VERSION ""

NS_ :

BS_:

BU_: mADC

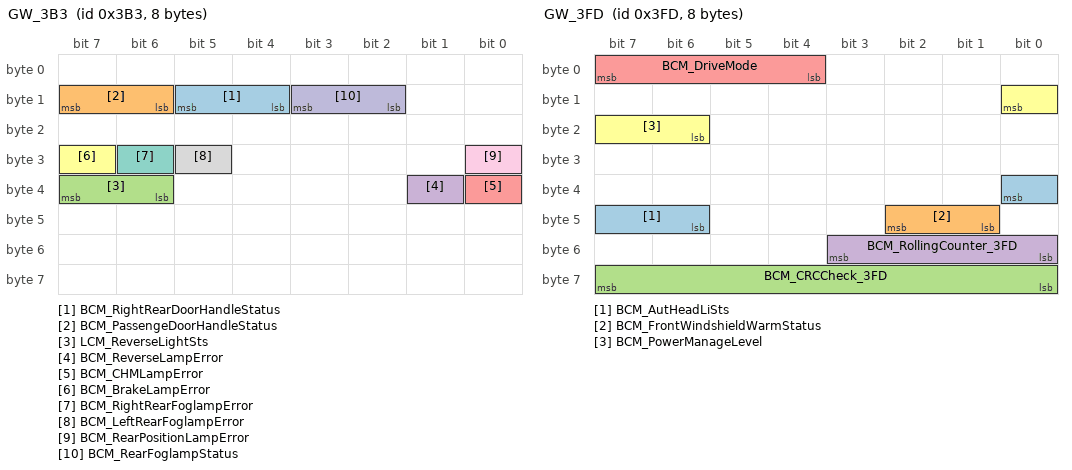
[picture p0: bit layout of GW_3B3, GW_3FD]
BO_ 947 GW_3B3: 8 Vector__XXX
 SG_ BCM_RightRearDoorHandleStatus : 13|2@0+ (1,0) [0|3] ""  mADC
 SG_ BCM_PassengeDoorHandleStatus : 15|2@0+ (1,0) [0|3] ""  mADC
 SG_ LCM_ReverseLightSts : 39|2@0+ (1,0) [0|3] ""  mADC
 SG_ BCM_ReverseLampError : 33|1@0+ (1,0) [0|1] ""  mADC
 SG_ BCM_CHMLampError : 32|1@0+ (1,0) [0|1] ""  mADC
 SG_ BCM_BrakeLampError : 31|1@0+ (1,0) [0|1] ""  mADC
 SG_ BCM_RightRearFoglampError : 30|1@0+ (1,0) [0|1] ""  mADC
 SG_ BCM_LeftRearFoglampError : 29|1@0+ (1,0) [0|1] ""  mADC
 SG_ BCM_RearPositionLampError : 24|1@0+ (1,0) [0|1] ""  mADC
 SG_ BCM_RearFoglampStatus : 11|2@0+ (1,0) [0|3] ""  mADC

BO_ 957 GW_3BD: 64 Vector__XXX
 SG_ HU_Llong_Tunnel_Len : 394|11@0+ (10,0) [0|20470] ""  mADC
 SG_ HU_Long_Ramp_Side : 396|2@0+ (1,0) [0|3] ""  mADC
 SG_ HU_Long_Ramp_Dis : 391|11@0+ (10,0) [0|20470] ""  mADC
 SG_ HU_ParallelRoadSide : 476|2@0+ (1,0) [0|3] ""  mADC
 SG_ HU_ParallelRoadInfo : 478|2@0+ (1,0) [0|3] ""  mADC
 SG_ HU_EnterParallelRoadInfo : 464|2@0+ (1,0) [0|3] ""  mADC
 SG_ HU_ParallelRoadDistance : 456|8@0+ (10,0) [0|2000] "m"  mADC
 SG_ HU_AsistantSysteSwitch : 365|2@0+ (1,0) [0|2] ""  mADC
 SG_ HU_ALCModeSelection : 353|2@0+ (1,0) [0|3] ""  mADC
 SG_ HU_SlotUserSelected : 271|4@0+ (1,0) [0|15] ""  mADC
 SG_ HU_SentryModeSt : 424|3@0+ (1,0) [0|5] ""  mADC
 SG_ HU_AutoHeadLiSet : 242|3@0+ (1,0) [0|7] ""  mADC
 SG_ HU_RADSSwitch : 220|2@0+ (1,0) [0|3] ""  mADC
 SG_ HU_CRCCheck_394 : 63|8@0+ (1,0) [0|255] ""  mADC
 SG_ HU_RollingCounter_394 : 51|4@0+ (1,0) [0|15] ""  mADC
 SG_ HU_LaneChangeReq : 13|2@0+ (1,0) [0|3] ""  mADC
 SG_ HU_UDLCEnable : 17|2@0+ (1,0) [0|3] ""  mADC
 SG_ HU_ESSEnable : 11|2@0+ (1,0) [0|3] ""  mADC
 SG_ HU_ELKEnable : 1|2@0+ (1,0) [0|3] ""  mADC
 SG_ HU_TLAEnable : 9|2@0+ (1,0) [0|3] ""  mADC
 SG_ HU_LAEBEnable : 194|2@0+ (1,0) [0|3] ""  mADC
 SG_ HU_APAModeSelect : 247|3@0+ (1,0) [0|7] ""  mADC
 SG_ HU_NaviDistance : 144|17@0+ (1,0) [0|131070] "m"  mADC

BO_ 964 GW_3C4: 64 Vector__XXX
 SG_ HU_Indication_BusLane_Dis : 415|8@0+ (10,0) [0|2550] ""  mADC
 SG_ HU_Indication_PedestrianCro_Dis : 407|8@0+ (10,0) [0|2550] ""  mADC
 SG_ HU_Indication_MainRoadPri_Dis : 399|8@0+ (10,0) [0|2550] ""  mADC
 SG_ HU_Indication_Walk_Dis : 391|8@0+ (10,0) [0|2550] ""  mADC
 SG_ HU_Indication_OneWay_Dis : 487|8@0+ (10,0) [0|2550] ""  mADC
 SG_ HU_Prohibitory_GiveWayOncom_Dis : 479|8@0+ (10,0) [0|2550] ""  mADC
 SG_ HU_Prohibitory_Honking_Dis : 471|8@0+ (10,0) [0|2550] ""  mADC
 SG_ HU_Prohibitory_Enter_Dis : 463|8@0+ (10,0) [0|2550] ""  mADC
 SG_ HU_Prohibitory_StopToGiveWay_Dis : 455|8@0+ (10,0) [0|2550] ""  mADC
 SG_ HU_Indication_BusLane : 492|1@0+ (1,0) [0|1] ""  mADC
 SG_ HU_Indication_PedestrianCrossing : 493|1@0+ (1,0) [0|1] ""  mADC
 SG_ HU_Indication_MainRoadPriority : 494|1@0+ (1,0) [0|1] ""  mADC
 SG_ HU_Indication_Walk : 495|1@0+ (1,0) [0|1] ""  mADC
 SG_ HU_Indication_OneWay : 327|1@0+ (1,0) [0|1] ""  mADC
 SG_ HU_Prohibitory_GiveWayToOncoming : 436|1@0+ (1,0) [0|1] ""  mADC
 SG_ HU_Prohibitory_Honking : 437|1@0+ (1,0) [0|1] ""  mADC
 SG_ HU_Prohibitory_Enter : 438|1@0+ (1,0) [0|1] ""  mADC
 SG_ HU_Prohibitory_StopToGiveWay : 439|1@0+ (1,0) [0|1] ""  mADC
 SG_ HU_Prohibitory_SpeedLimit : 424|1@0+ (1,0) [0|1] ""  mADC
 SG_ HU_Prohibitory_VehParkLongTime : 425|1@0+ (1,0) [0|1] ""  mADC
 SG_ HU_Prohibitory_VehicleParking : 426|1@0+ (1,0) [0|1] ""  mADC
 SG_ HU_Prohibitory_Overtake : 427|1@0+ (1,0) [0|1] ""  mADC
 SG_ HU_Prohibitory_Uturn : 428|1@0+ (1,0) [0|1] ""  mADC
 SG_ HU_Prohibitory_Straight : 429|1@0+ (1,0) [0|1] ""  mADC
 SG_ HU_Prohibitory_TurnRight : 430|1@0+ (1,0) [0|1] ""  mADC
 SG_ HU_Prohibitory_MotorVehicles : 431|1@0+ (1,0) [0|1] ""  mADC
 SG_ HU_Prohibitory_DriveInto : 416|1@0+ (1,0) [0|1] ""  mADC
 SG_ HU_Warning_RoadWorks : 417|1@0+ (1,0) [0|1] ""  mADC
 SG_ HU_Warning_Slow : 418|1@0+ (1,0) [0|1] ""  mADC
 SG_ HU_Warning_Tunnel : 419|1@0+ (1,0) [0|1] ""  mADC
 SG_ HU_Warning_Slip : 420|1@0+ (1,0) [0|1] ""  mADC
 SG_ HU_Warning_Pedestrian : 421|1@0+ (1,0) [0|1] ""  mADC
 SG_ HU_Warning_ContinuousDetours : 422|1@0+ (1,0) [0|1] ""  mADC
 SG_ HU_Warning_ReverseCurve : 423|1@0+ (1,0) [0|1] ""  mADC
 SG_ HU_BSDLCAMode : 183|3@0+ (1,0) [0|7] ""  mADC
 SG_ HU_CrossingAngle4 : 343|8@0+ (1,0) [0|255] ""  mADC
 SG_ HU_CrossingAngle3 : 351|8@0+ (1,0) [0|255] ""  mADC
 SG_ HU_CrossingAngle2 : 359|8@0+ (1,0) [0|255] ""  mADC
 SG_ HU_CrossingAngle1 : 367|8@0+ (1,0) [0|255] ""  mADC
 SG_ HU_EnterRoundaboutInfo : 373|2@0+ (1,0) [0|3] ""  mADC
 SG_ HU_RoundaboutDistance : 333|6@0+ (10,0) [0|63] ""  mADC
 SG_ HU_EnterCrossingInfo : 375|2@0+ (1,0) [0|3] ""  mADC
 SG_ HU_CrossingDistance : 323|6@0+ (10,0) [0|63] ""  mADC
 SG_ HU_CRCCheck_3C4 : 503|16@0+ (1,0) [0|65535] ""  mADC
 SG_ HU_RollingCounter_3C4 : 491|4@0+ (1,0) [0|15] ""  mADC
 SG_ HU_MapMatchStatus : 309|2@0+ (1,0) [0|3] ""  mADC
 SG_ HU_MapDataUpdateStatus : 118|3@0+ (1,0) [0|7] ""  mADC
 SG_ HU_SlopeGradient_300m : 303|10@0+ (0.1,-51.1) [-51.1|51.1] "%"  mADC
 SG_ HU_RoadCurvature_600m : 281|10@0+ (1,0) [0|1023] "1/m"  mADC
 SG_ HU_RoadCurvature_400m : 275|10@0+ (1,0) [0|1023] "1/m"  mADC
 SG_ HU_RoadCurvature_300m : 269|10@0+ (1,0) [0|1023] "1/m"  mADC
 SG_ HU_RoadCurvature_100m : 263|10@0+ (1,0) [0|1023] "1/m"  mADC
 SG_ HU_RoadCurvature_90m : 239|10@0+ (1,0) [0|1023] "1/m"  mADC
 SG_ HU_RoadCurvature_80m : 217|10@0+ (1,0) [0|1023] "1/m"  mADC
 SG_ HU_RoadCurvature_70m : 211|10@0+ (1,0) [0|1023] "1/m"  mADC
 SG_ HU_RoadCurvature_60m : 205|10@0+ (1,0) [0|1023] "1/m"  mADC
 SG_ HU_RoadCurvature_50m : 199|10@0+ (1,0) [0|1023] "1/m"  mADC
 SG_ HU_RoadCurvature_40m : 161|10@0+ (1,0) [0|1023] "1/m"  mADC
 SG_ HU_RoadCurvature_30m : 155|10@0+ (1,0) [0|1023] "1/m"  mADC
 SG_ HU_RoadCurvature_20m : 149|10@0+ (1,0) [0|1023] "1/m"  mADC
 SG_ HU_RoadCurvature_10m : 143|10@0+ (1,0) [0|1023] "1/m"  mADC
 SG_ HU_Road_TrafficFlow : 105|3@0+ (1,0) [0|7] ""  mADC
 SG_ HU_Lane_Changtype : 129|2@0+ (1,0) [0|3] ""  mADC
 SG_ HU_To_NumchangeOfLanes_Dist : 135|6@0+ (10,0) [0|600] "m"  mADC
 SG_ HU_To_Branch_Dis : 111|6@0+ (10,0) [0|600] "m"  mADC
 SG_ HU_To_TrafficAccident_Dis : 101|6@0+ (10,0) [0|600] "m"  mADC
 SG_ HU_TrafficAccident_Info : 103|2@0+ (1,0) [0|3] ""  mADC
 SG_ HU_To_Construction_Dis : 93|6@0+ (10,0) [0|600] "m"  mADC
 SG_ HU_Construction_Info : 95|2@0+ (1,0) [0|3] ""  mADC
 SG_ HU_TollDis : 85|6@0+ (10,0) [0|600] "m"  mADC
 SG_ HU_TollInfo : 87|2@0+ (1,0) [0|3] ""  mADC
 SG_ HU_FallingRockDi : 77|6@0+ (10,0) [0|600] "m"  mADC
 SG_ HU_FallingRockInfo : 79|2@0+ (1,0) [0|3] ""  mADC
 SG_ HU_LaneCnt : 66|3@0+ (1,0) [0|7] ""  mADC
 SG_ HU_ForwardRoadType : 69|3@0+ (1,0) [0|7] ""  mADC
 SG_ HU_RampSide : 71|2@0+ (1,0) [0|3] ""  mADC
 SG_ HU_NavGuiganceStatus : 47|2@0+ (1,0) [0|3] ""  mADC
 SG_ HU_SlopeDistance : 45|6@0+ (10,0) [0|600] "m"  mADC
 SG_ HU_TunnelLength : 37|6@0+ (10,0) [0|630] "m"  mADC
 SG_ HU_RoadCurvatureFar : 17|10@0+ (1,0) [0|1023] ""  mADC
 SG_ HU_TunnelDistance : 23|6@0+ (10,0) [0|600] "m"  mADC
 SG_ HU_RoadCurvature : 1|10@0+ (1,0) [0|1023] ""  mADC
 SG_ HU_EnterSlopeInfo : 5|2@0+ (1,0) [0|3] ""  mADC
 SG_ HU_EnterTunnelInfo : 3|2@0+ (1,0) [0|3] ""  mADC

BO_ 1021 GW_3FD: 8 Vector__XXX
 SG_ BCM_AutHeadLiSts : 32|3@0+ (1,0) [0|7] ""  mADC
 SG_ BCM_FrontWindshieldWarmStatus : 42|2@0+ (1,0) [0|3] ""  mADC
 SG_ BCM_CRCCheck_3FD : 63|8@0+ (1,0) [0|255] ""  mADC
 SG_ BCM_RollingCounter_3FD : 51|4@0+ (1,0) [0|15] ""  mADC
 SG_ BCM_DriveMode : 7|4@0+ (1,0) [0|15] ""  mADC
 SG_ BCM_PowerManageLevel : 8|3@0+ (1,0) [0|7] ""  mADC

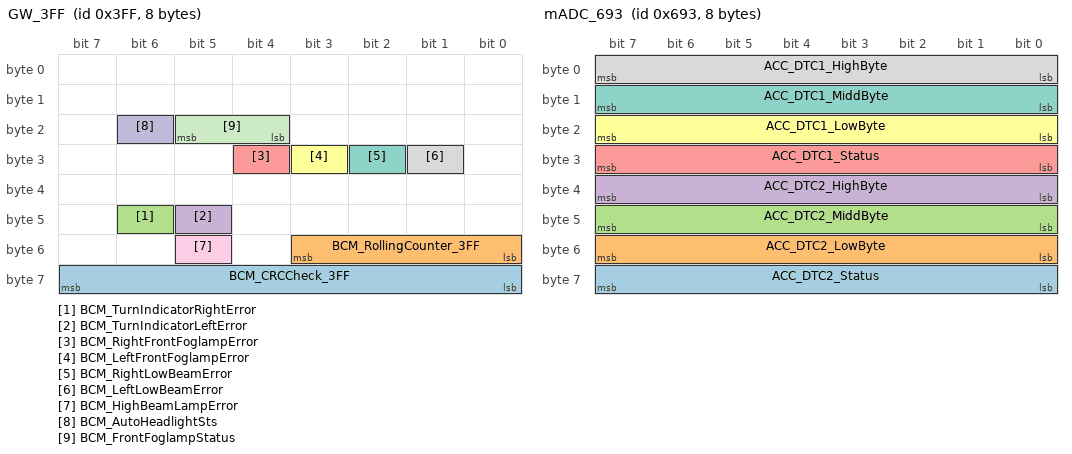
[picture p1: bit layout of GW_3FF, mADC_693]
BO_ 1023 GW_3FF: 8 Vector__XXX
 SG_ BCM_CRCCheck_3FF : 63|8@0+ (1,0) [0|255] ""  mADC
 SG_ BCM_RollingCounter_3FF : 51|4@0+ (1,0) [0|15] ""  mADC
 SG_ BCM_TurnIndicatorRightError : 46|1@0+ (1,0) [0|1] ""  mADC
 SG_ BCM_TurnIndicatorLeftError : 45|1@0+ (1,0) [0|1] ""  mADC
 SG_ BCM_RightFrontFoglampError : 28|1@0+ (1,0) [0|1] ""  mADC
 SG_ BCM_LeftFrontFoglampError : 27|1@0+ (1,0) [0|1] ""  mADC
 SG_ BCM_RightLowBeamError : 26|1@0+ (1,0) [0|1] ""  mADC
 SG_ BCM_LeftLowBeamError : 25|1@0+ (1,0) [0|1] ""  mADC
 SG_ BCM_HighBeamLampError : 53|1@0+ (1,0) [0|1] ""  mADC
 SG_ BCM_AutoHeadlightSts : 22|1@0+ (1,0) [0|1] ""  mADC
 SG_ BCM_FrontFoglampStatus : 21|2@0+ (1,0) [0|3] ""  mADC

BO_ 1683 mADC_693: 8 mADC
 SG_ ACC_DTC2_Status : 63|8@0+ (1,0) [0|255] "" Vector__XXX
 SG_ ACC_DTC2_LowByte : 55|8@0+ (1,0) [0|255] "" Vector__XXX
 SG_ ACC_DTC2_MiddByte : 47|8@0+ (1,0) [0|255] "" Vector__XXX
 SG_ ACC_DTC2_HighByte : 39|8@0+ (1,0) [0|255] "" Vector__XXX
 SG_ ACC_DTC1_Status : 31|8@0+ (1,0) [0|255] "" Vector__XXX
 SG_ ACC_DTC1_LowByte : 23|8@0+ (1,0) [0|255] "" Vector__XXX
 SG_ ACC_DTC1_MiddByte : 15|8@0+ (1,0) [0|255] "" Vector__XXX
 SG_ ACC_DTC1_HighByte : 7|8@0+ (1,0) [0|255] "" Vector__XXX

BO_ 652 GW_28C: 8 Vector__XXX
 SG_ GW_MFS_APA_switch : 35|2@0+ (1,0) [0|3] ""  mADC
 SG_ GW_MFS_HODCalibratedStatus : 29|1@0+ (1,0) [0|1] ""  mADC
 SG_ GW_MFS_HODLinStatus : 28|1@0+ (1,0) [0|1] ""  mADC
 SG_ GW_MFS_HODAppStatus : 27|1@0+ (1,0) [0|1] ""  mADC
 SG_ GW_MFS_HODSenserStatus : 47|1@0+ (1,0) [0|1] ""  mADC
 SG_ GW_MFS_HODSystemStatus : 23|3@0+ (1,0) [0|7] ""  mADC
 SG_ GW_MFS_handsoffAbilityDetect : 26|3@0+ (1,0) [0|7] ""  mADC
 SG_ GW_MFS_handsoffDetectResult : 20|3@0+ (1,0) [0|7] ""  mADC
 SG_ GW_MFS_CRCCheck_28C : 63|8@0+ (1,0) [0|255] ""  mADC
 SG_ GW_MFS_RollingCounter_28C : 51|4@0+ (1,0) [0|15] ""  mADC
 SG_ GW_MFS_DiagInfoSW_28C : 42|3@0+ (1,0) [0|7] ""  mADC
 SG_ GW_MFS_IACCenable_switch_signal : 13|2@0+ (1,0) [0|3] ""  mADC
 SG_ GW_MFS_LIM_switch_signal : 11|2@0+ (1,0) [0|3] ""  mADC
 SG_ GW_MFS_DIST_switch_signal : 9|2@0+ (1,0) [0|3] ""  mADC
 SG_ GW_MFS_SETReduce_switch_signal : 7|2@0+ (1,0) [0|3] ""  mADC
 SG_ GW_MFS_RESPlus_switch_signal : 5|2@0+ (1,0) [0|3] ""  mADC
 SG_ GW_MFS_Cancle_switch_signal : 3|2@0+ (1,0) [0|3] ""  mADC
 SG_ GW_MFS_Crusie_switch_signal : 1|2@0+ (1,0) [0|3] ""  mADC
 SG_ GW_MFS_DISTReduce_switch_signal : 31|2@0+ (1,0) [0|3] ""  mADC
 SG_ GW_MFS_DISTPlus_switch_signal : 17|2@0+ (1,0) [0|3] ""  mADC

BO_ 372 mADC_174: 8 mADC
 SG_ APA_ReqSYNMSG : 1|2@0+ (1,0) [0|3] "" Vector__XXX

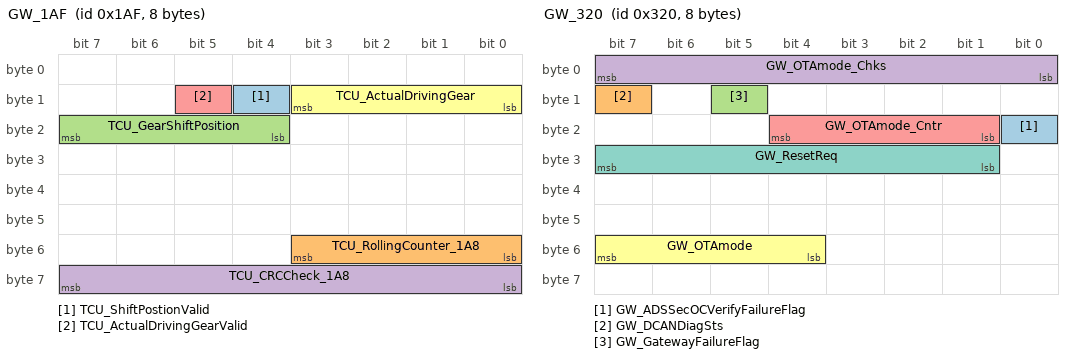
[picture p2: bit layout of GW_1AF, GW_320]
BO_ 431 GW_1AF: 8 Vector__XXX
 SG_ TCU_ShiftPostionValid : 12|1@0+ (1,0) [0|1] ""  mADC
 SG_ TCU_RollingCounter_1A8 : 51|4@0+ (1,0) [0|15] ""  mADC
 SG_ TCU_GearShiftPosition : 23|4@0+ (1,0) [0|15] ""  mADC
 SG_ TCU_CRCCheck_1A8 : 63|8@0+ (1,0) [0|255] ""  mADC
 SG_ TCU_ActualDrivingGearValid : 13|1@0+ (1,0) [0|1] ""  mADC
 SG_ TCU_ActualDrivingGear : 11|4@0+ (1,0) [0|15] ""  mADC

BO_ 800 GW_320: 8 Vector__XXX
 SG_ GW_ADSSecOCVerifyFailureFlag : 16|1@0+ (1,0) [0|1] ""  mADC
 SG_ GW_DCANDiagSts : 15|1@0+ (1,0) [0|1] ""  mADC
 SG_ GW_GatewayFailureFlag : 13|1@0+ (1,0) [0|1] ""  mADC
 SG_ GW_OTAmode_Chks : 7|8@0+ (1,0) [0|255] ""  mADC
 SG_ GW_OTAmode_Cntr : 20|4@0+ (1,0) [0|15] ""  mADC
 SG_ GW_OTAmode : 55|4@0+ (1,0) [0|15] ""  mADC
 SG_ GW_ResetReq : 31|7@0+ (1,0) [0|127] ""  mADC

BO_ 922 mADC_39A: 64 mADC
 SG_ LAS_RoadFeature : 395|4@0+ (1,0) [0|15] "" Vector__XXX
 SG_ LAS_RD4LongDistence : 407|8@0+ (1,0) [0|255] "" Vector__XXX
 SG_ LAS_RD3LongDistence : 415|8@0+ (1,0) [0|255] "" Vector__XXX
 SG_ LAS_RD2LongDistence : 423|8@0+ (1,0) [0|255] "" Vector__XXX
 SG_ LAS_RD1LongDistence : 431|8@0+ (1,0) [0|255] "" Vector__XXX
 SG_ LAS_RD4RoadInforAvailable : 399|2@0+ (1,0) [0|3] "" Vector__XXX
 SG_ LAS_RD3RoadInforAvailable : 439|2@0+ (1,0) [0|3] "" Vector__XXX
 SG_ LAS_RD2RoadInforAvailable : 397|2@0+ (1,0) [0|3] "" Vector__XXX
 SG_ LAS_RD1RoadInforAvailable : 437|2@0+ (1,0) [0|3] "" Vector__XXX
 SG_ LAS_RollingCounter_579 : 435|4@0+ (1,0) [0|15] "" Vector__XXX
 SG_ LAS_CRCCheck_579 : 447|8@0+ (1,0) [0|255] "" Vector__XXX
 SG_ ACC_RollingCounter_39A : 491|4@0+ (1,0) [0|15] "" Vector__XXX
 SG_ ACC_CRCCheck_39A : 503|16@0+ (1,0) [0|65535] "" Vector__XXX
 SG_ LAS_TSRRightLaneStatus : 55|3@0+ (1,0) [0|7] "" Vector__XXX
 SG_ LAS_TSRLeftLaneStatus : 47|3@0+ (1,0) [0|7] "" Vector__XXX
 SG_ LAS_CRCCheck_3C0 : 191|8@0+ (1,0) [0|255] "" Vector__XXX
 SG_ LAS_RollingCounter_3C0 : 179|4@0+ (1,0) [0|15] "" Vector__XXX
 SG_ LAS_TSRRightLaneSpdLimit : 143|8@0+ (1,0) [0|255] "" Vector__XXX
 SG_ LAS_TSRLeftLaneSpdLimit : 135|8@0+ (1,0) [0|255] "" Vector__XXX
 SG_ LAS_CRCCheck_3D4 : 127|8@0+ (1,0) [0|255] "" Vector__XXX
 SG_ LAS_RollingCounter_3D4 : 115|4@0+ (1,0) [0|15] "" Vector__XXX
 SG_ LAS_TLAStopLine_HostLane : 111|8@0+ (1,0) [0|255] "" Vector__XXX
 SG_ LAS_TLADistance_HostLane : 103|8@0+ (1,0) [0|255] "" Vector__XXX
 SG_ LAS_TLACountDownTime_HostLane : 94|7@0+ (1,0) [0|127] "" Vector__XXX
 SG_ LAS_TSRMandatorySign : 70|4@0+ (1,0) [0|15] "" Vector__XXX
 SG_ LAS_TSRWarningSign : 84|5@0+ (1,0) [0|31] "" Vector__XXX
 SG_ LAS_TSRProhibitionSign : 66|5@0+ (1,0) [0|31] "" Vector__XXX
 SG_ LAS_CRCCheck_332 : 63|8@0+ (1,0) [0|255] "" Vector__XXX
 SG_ LAS_RollingCounter_332 : 51|4@0+ (1,0) [0|15] "" Vector__XXX
 SG_ LAS_OverspeedSoundWarningEnSt : 27|1@0+ (1,0) [0|1] "" Vector__XXX
 SG_ LAS_TSREnable : 30|1@0+ (1,0) [0|1] "" Vector__XXX
 SG_ LAS_HMAEnableStatus : 22|1@0+ (1,0) [0|1] "" Vector__XXX
 SG_ LAS_HMALightDistribution : 8|1@0+ (1,0) [0|1] "" Vector__XXX
 SG_ LAS_HMAStatus : 44|2@0+ (1,0) [0|3] "" Vector__XXX
 SG_ LAS_TSRHostSpdLimitUnits : 41|2@0+ (1,0) [0|3] "" Vector__XXX
 SG_ LAS_TSRHostSpdLimit : 39|8@0+ (1,0) [0|255] "" Vector__XXX
 SG_ LAS_TSRStatus : 26|3@0+ (1,0) [0|7] "" Vector__XXX
 SG_ LAS_FrontCameraCalibrationStatus : 20|2@0+ (1,0) [0|3] "" Vector__XXX
 SG_ LAS_FrontCameraFailureStatus : 17|2@0+ (1,0) [0|3] "" Vector__XXX
 SG_ LAS_OverspeedWarningOffset : 14|6@0+ (1,-10) [-10|47] "km/h" Vector__XXX
 SG_ LAS_OverspeedWarningEnableStatus : 15|1@0+ (1,0) [0|1] "" Vector__XXX
 SG_ LAS_OverspeedSoundWarning : 2|1@0+ (1,0) [0|1] "" Vector__XXX
 SG_ LAS_OverspeedVisualWarning : 5|1@0+ (1,0) [0|1] "" Vector__XXX
 SG_ LAS_CRCCheck_37D : 255|8@0+ (1,0) [0|255] "" Vector__XXX
 SG_ LAS_RollingCounter_37D : 243|4@0+ (1,0) [0|15] "" Vector__XXX
 SG_ LAS_TLAArrowDirection_RightLane : 236|3@0+ (1,0) [0|7] "" Vector__XXX
 SG_ LAS_TLAObjectType_RightLane : 239|3@0+ (1,0) [0|7] "" Vector__XXX
 SG_ LAS_TLAObjectStatus_RightLane : 247|2@0+ (1,0) [0|3] "" Vector__XXX
 SG_ LAS_TLAObjectColour_RightLane : 225|2@0+ (1,0) [0|3] "" Vector__XXX
 SG_ LAS_TLAObjectDetection_RightLane : 227|1@0+ (1,0) [0|1] "" Vector__XXX
 SG_ LAS_TLAArrowDirection_LeftLane : 216|3@0+ (1,0) [0|7] "" Vector__XXX
 SG_ LAS_TLAObjectType_LeftLane : 219|3@0+ (1,0) [0|7] "" Vector__XXX
 SG_ LAS_TLAObjectStatus_LeftLane : 245|2@0+ (1,0) [0|3] "" Vector__XXX
 SG_ LAS_TLAObjectColour_LeftLane : 221|2@0+ (1,0) [0|3] "" Vector__XXX
 SG_ LAS_TLAObjectDetection_LeftLane : 223|1@0+ (1,0) [0|1] "" Vector__XXX
 SG_ LAS_TLAArrowDirection_HostLane : 215|3@0+ (1,0) [0|7] "" Vector__XXX
 SG_ LAS_TLAObjectStatus_HostLane : 199|2@0+ (1,0) [0|3] "" Vector__XXX
 SG_ LAS_TLAObjectType_HostLane : 212|3@0+ (1,0) [0|7] "" Vector__XXX
 SG_ LAS_TLAObjectColour_HostLane : 204|2@0+ (1,0) [0|3] "" Vector__XXX
 SG_ LAS_TLAObjectDetection_HostLane : 200|1@0+ (1,0) [0|1] "" Vector__XXX
 SG_ LAS_TLAWarninglevel : 197|2@0+ (1,0) [0|3] "" Vector__XXX
 SG_ LAS_TLAStatus : 193|2@0+ (1,0) [0|3] "" Vector__XXX
 SG_ LAS_TLAEnable : 194|1@0+ (1,0) [0|1] "" Vector__XXX
 SG_ LAS_RoadSignCenterLatRange_RLane : 306|9@0+ (0.05,-8) [-8|17.55] "m" Vector__XXX
 SG_ LAS_RoadSignCenterLngRange_RLane : 299|9@0+ (0.1,0) [0|51.1] "m" Vector__XXX
 SG_ LAS_RoadSignCenterLatRange_LLane : 292|9@0+ (0.05,-8) [-8|17.55] "m" Vector__XXX
 SG_ LAS_RoadSignCenterLngRange_LLane : 285|9@0+ (0.1,0) [0|51.1] "m" Vector__XXX
 SG_ LAS_RoadSignCenterLatRange_HLane : 278|9@0+ (0.05,-8) [-8|17.55] "m" Vector__XXX
 SG_ LAS_RoadSignCenterLngRange_HLane : 271|9@0+ (0.1,0) [0|51.1] "m" Vector__XXX
 SG_ LAS_CrosswalkLngRange_HLane : 263|8@0+ (1,0) [0|255] "" Vector__XXX
 SG_ LAS_RoadSignType_RLane : 157|5@0+ (1,0) [0|15] "" Vector__XXX
 SG_ LAS_RoadSignType_LLane : 146|5@0+ (1,0) [0|15] "" Vector__XXX
 SG_ LAS_RoadSignType_HLane : 151|5@0+ (1,0) [0|15] "" Vector__XXX

BO_ 906 GW_38A: 8 Vector__XXX
 SG_ GW_MFS_Cust_switch : 17|2@0+ (1,0) [0|3] ""  mADC

BO_ 583 BDC_247: 32 Vector__XXX
 SG_ APA_EngTorqReq : 87|10@0+ (0.097847,0) [0|99.999634] "%"  mADC
 SG_ APA_SlotNotice_1 : 169|6@0+ (1,0) [0|63] ""  mADC
 SG_ APA_VCUReadyReq : 43|1@0+ (1,0) [0|1] ""  mADC
 SG_ APA_ESPDistToStop : 149|12@0+ (1,0) [0|4095] "cm"  mADC
 SG_ APA_ESP_StandstillRequest : 150|1@0+ (1,0) [0|1] ""  mADC
 SG_ APA_RollingCounter_236 : 179|4@0+ (1,0) [0|15] ""  mADC
 SG_ APA_CRC_Checksum_236 : 191|8@0+ (1,0) [0|255] ""  mADC
 SG_ APA_PtTrqReqValid : 151|1@0+ (1,0) [0|1] ""  mADC
 SG_ APA_LatLongSC : 31|2@0+ (1,0) [0|3] ""  mADC
 SG_ APA_ESP_BrakeFunctionMode : 238|3@0+ (1,0) [0|7] ""  mADC
 SG_ APA_TrqHoldForTCUCl : 111|1@0+ (1,0) [0|1] ""  mADC
 SG_ APA_TCUClutchCombinationReq : 110|1@0+ (1,0) [0|1] ""  mADC
 SG_ APA_FunctionOnOffSts : 33|5@0+ (1,0) [0|31] ""  mADC
 SG_ APA_APAOnOff : 6|1@0+ (1,0) [0|1] ""  mADC
 SG_ APA_CRCCheck_264 : 63|8@0+ (1,0) [0|255] ""  mADC
 SG_ APA_ParkingPercentage : 42|7@0+ (1,0) [0|100] "%"  mADC
 SG_ APA_RollingCounter_264 : 51|4@0+ (1,0) [0|15] ""  mADC
 SG_ APA_TurnLightsCommand : 29|2@0+ (1,0) [0|3] ""  mADC
 SG_ APA_IncreasePressureReq : 27|1@0+ (1,0) [0|1] ""  mADC
 SG_ APA_RemoteOnOff : 25|2@0+ (1,0) [0|3] ""  mADC
 SG_ APA_SteeringAngleReq : 15|16@0- (0.1,0) [-780|780] "degree"  mADC
 SG_ APA_EmergenceBrake : 7|1@0+ (1,0) [0|1] ""  mADC
 SG_ APA_ErrorStatus : 2|1@0+ (1,0) [0|1] ""  mADC
 SG_ APA_SteeringAngleReqProtection : 1|2@0+ (1,0) [0|3] ""  mADC
 SG_ APA_HSAHDforbidden : 92|1@0+ (1,0) [0|1] ""  mADC
 SG_ APA_CRCCheck_26C : 127|8@0+ (1,0) [0|255] ""  mADC
 SG_ APA_RollingCounter_26C : 115|4@0+ (1,0) [0|15] "N/A"  mADC
 SG_ APA_AccPedShieldReq : 97|1@0+ (1,0) [0|1] ""  mADC
 SG_ APA_SlotNotice : 109|4@0+ (1,0) [0|15] ""  mADC
 SG_ APA_DynamicSlotWarning : 105|1@0+ (1,0) [0|1] ""  mADC
 SG_ APA_Activation_Status : 89|3@0+ (1,0) [0|7] ""  mADC
 SG_ APA_EngineTrqReqEnable : 93|1@0+ (1,0) [0|1] ""  mADC
 SG_ APA_LSCAction : 91|1@0+ (1,0) [0|1] ""  mADC
 SG_ APA_TransPRNDShiftEnable : 90|1@0+ (1,0) [0|1] ""  mADC
 SG_ APA_TargetAcceleration : 79|8@0+ (0.05,-5) [-5|7.75] "m/s2"  mADC
 SG_ APA_TransPRNDShiftReqValid : 71|1@0+ (1,0) [0|1] ""  mADC
 SG_ APA_TransPRNDShiftRequest : 70|3@0+ (1,0) [0|7] ""  mADC
 SG_ APA_TargetAccelerationValid : 67|1@0+ (1,0) [0|1] "NA"  mADC
 SG_ APA_EPBrequestValid : 66|1@0+ (1,0) [0|1] ""  mADC
 SG_ APA_EPBrequest : 65|2@0+ (1,0) [0|3] ""  mADC
 SG_ APA_PtTorqReq : 135|16@0+ (1,-32768) [-32768|32767] "Nm"  mADC
 SG_ APA_CRCCheck_247 : 247|16@0+ (1,0) [0|65535] ""  mADC
 SG_ APA_RollingCounter_247 : 235|4@0+ (1,0) [0|15] ""  mADC

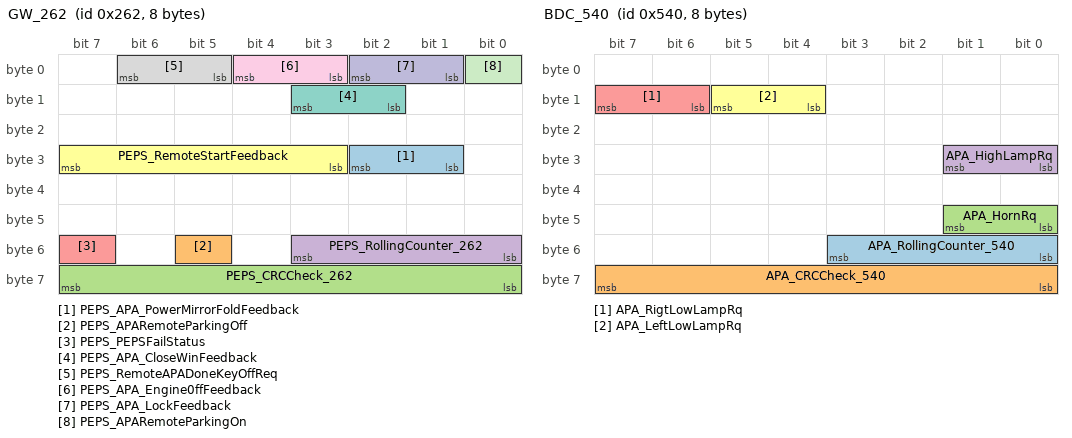
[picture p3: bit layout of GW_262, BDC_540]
BO_ 610 GW_262: 8 Vector__XXX
 SG_ PEPS_APA_PowerMirrorFoldFeedback : 26|2@0+ (1,0) [0|3] ""  mADC
 SG_ PEPS_APARemoteParkingOff : 53|1@0+ (1,0) [0|1] ""  mADC
 SG_ PEPS_CRCCheck_262 : 63|8@0+ (1,0) [0|255] ""  mADC
 SG_ PEPS_RollingCounter_262 : 51|4@0+ (1,0) [0|15] ""  mADC
 SG_ PEPS_PEPSFailStatus : 55|1@0+ (1,0) [0|1] ""  mADC
 SG_ PEPS_RemoteStartFeedback : 31|5@0+ (1,0) [0|31] ""  mADC
 SG_ PEPS_APA_CloseWinFeedback : 11|2@0+ (1,0) [0|3] ""  mADC
 SG_ PEPS_RemoteAPADoneKeyOffReq : 6|2@0+ (1,0) [0|3] ""  mADC
 SG_ PEPS_APA_Engine0ffFeedback : 4|2@0+ (1,0) [0|3] ""  mADC
 SG_ PEPS_APA_LockFeedback : 2|2@0+ (1,0) [0|3] ""  mADC
 SG_ PEPS_APARemoteParkingOn : 0|1@0+ (1,0) [0|1] ""  mADC

BO_ 917 GW_395: 64 Vector__XXX
 SG_ TBOX_APP_Ylevel : 215|16@0+ (1,0) [0|720] ""  mADC
 SG_ TBOX_APP_Xlevel : 199|16@0+ (1,0) [0|1920] ""  mADC
 SG_ TBOX_APAControlEnable : 226|5@0+ (1,0) [0|31] ""  mADC
 SG_ TBOX_RemoteStartReq : 228|2@0+ (1,0) [0|3] ""  mADC
 SG_ TBOX_APAFunctionReq : 231|3@0+ (1,0) [0|7] ""  mADC
 SG_ TBOX_SignalStrength : 89|3@0+ (1,0) [0|7] ""  mADC
 SG_ TBOX_SignalType : 92|3@0+ (1,0) [0|7] ""  mADC
 SG_ TBOX_APA_SignalDelay : 87|4@0+ (1,0) [0|15] ""  mADC
 SG_ TBOX_APAmoduleEnable : 71|2@0+ (1,0) [0|3] ""  mADC
 SG_ TBOX_RemoteDisReq : 50|1@0+ (1,0) [0|1] ""  mADC
 SG_ TBOX_VehicleVedioDetectReq : 1|2@0+ (1,0) [0|3] ""  mADC
 SG_ TBOX_RemoteDetectReq : 55|2@0+ (1,0) [0|3] ""  mADC

BO_ 1344 BDC_540: 8 Vector__XXX
 SG_ APA_RollingCounter_540 : 51|4@0+ (1,0) [0|15] ""  mADC
 SG_ APA_CRCCheck_540 : 63|8@0+ (1,0) [0|255] ""  mADC
 SG_ APA_HornRq : 41|2@0+ (1,0) [0|3] ""  mADC
 SG_ APA_HighLampRq : 25|2@0+ (1,0) [0|3] ""  mADC
 SG_ APA_RigtLowLampRq : 15|2@0+ (1,0) [0|3] ""  mADC
 SG_ APA_LeftLowLampRq : 13|2@0+ (1,0) [0|3] ""  mADC

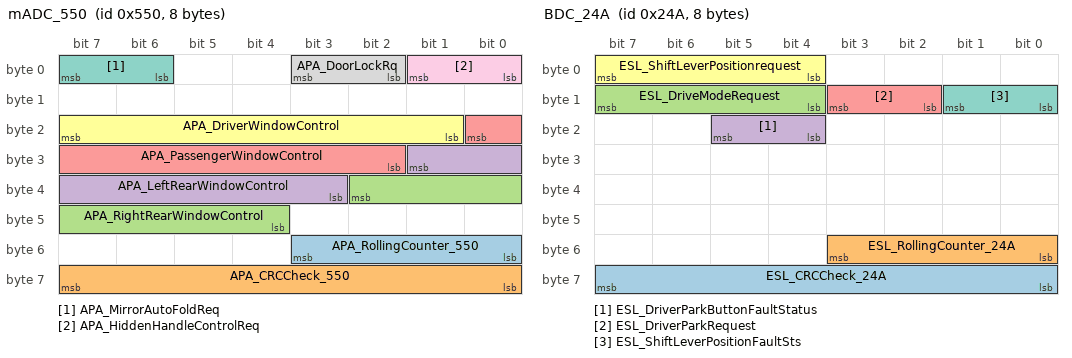
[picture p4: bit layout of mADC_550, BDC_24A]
BO_ 1360 mADC_550: 8 mADC
 SG_ APA_RollingCounter_550 : 51|4@0+ (1,0) [0|15] "" Vector__XXX
 SG_ APA_CRCCheck_550 : 63|8@0+ (1,0) [0|255] "" Vector__XXX
 SG_ APA_RightRearWindowControl : 34|7@0+ (1,0) [0|127] "" Vector__XXX
 SG_ APA_LeftRearWindowControl : 25|7@0+ (1,0) [0|127] "" Vector__XXX
 SG_ APA_PassengerWindowControl : 16|7@0+ (1,0) [0|127] "" Vector__XXX
 SG_ APA_DriverWindowControl : 23|7@0+ (1,0) [0|127] "" Vector__XXX
 SG_ APA_MirrorAutoFoldReq : 7|2@0+ (1,0) [0|3] "" Vector__XXX
 SG_ APA_DoorLockRq : 3|2@0+ (1,0) [0|3] "" Vector__XXX
 SG_ APA_HiddenHandleControlReq : 1|2@0+ (1,0) [0|3] "" Vector__XXX

BO_ 1364 mADC_554: 8 mADC
 SG_ APA_RollingCounter_554 : 51|4@0+ (1,0) [0|15] "" Vector__XXX
 SG_ APA_CRCCheck_554 : 63|8@0+ (1,0) [0|255] "" Vector__XXX

BO_ 1554 mADC_612: 8 mADC
 SG_ DVR_EmergencyRecordStatus : 29|2@0+ (1,0) [0|3] "" Vector__XXX

BO_ 394 GW_18A: 8 Vector__XXX
 SG_ TCU_APAShiftGearRequestEnable : 2|2@0+ (1,0) [0|3] ""  mADC
 SG_ TCU_APAdriverInterruption : 4|2@0+ (1,0) [0|3] ""  mADC

BO_ 586 BDC_24A: 8 Vector__XXX
 SG_ ESL_CRCCheck_24A : 63|8@0+ (1,0) [0|255] ""  mADC
 SG_ ESL_RollingCounter_24A : 51|4@0+ (1,0) [0|15] ""  mADC
 SG_ ESL_DriveModeRequest : 15|4@0+ (1,0) [0|15] ""  mADC
 SG_ ESL_DriverParkButtonFaultStatus : 21|2@0+ (1,0) [0|3] ""  mADC
 SG_ ESL_DriverParkRequest : 11|2@0+ (1,0) [0|3] ""  mADC
 SG_ ESL_ShiftLeverPositionrequest : 7|4@0+ (1,0) [0|15] ""  mADC
 SG_ ESL_ShiftLeverPositionFaultSts : 9|2@0+ (1,0) [0|3] ""  mADC

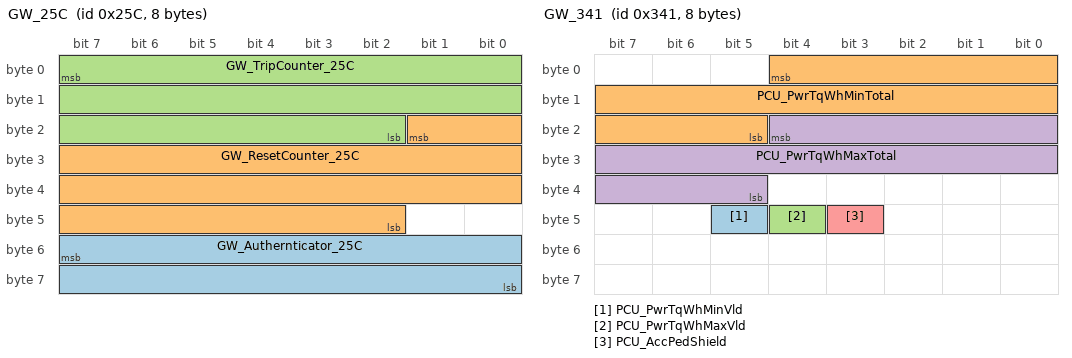
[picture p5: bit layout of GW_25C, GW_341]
BO_ 604 GW_25C: 8 Vector__XXX
 SG_ GW_Authernticator_25C : 55|16@0+ (1,0) [0|65535] ""  mADC
 SG_ GW_ResetCounter_25C : 17|24@0+ (1,0) [0|16777215] ""  mADC
 SG_ GW_TripCounter_25C : 7|22@0+ (1,0) [0|4194303] ""  mADC

BO_ 710 BDC_2C6: 64 Vector__XXX
 SG_ APA_FunctionOnOffSts : 75|4@0+ (1,0) [0|15] ""  mADC
 SG_ APA_ParkingSlot_Width : 429|6@0+ (0.1,1.7) [0|8] "m"  mADC
 SG_ APA_ParkingSlot_Length : 420|7@0+ (0.1,2.9) [0|15.6] "m"  mADC
 SG_ APA_ParkingSlot_ExtraFeature : 408|4@0+ (1,0) [0|15] ""  mADC
 SG_ APA_ParkingSlot_Type : 412|4@0+ (1,0) [0|15] ""  mADC
 SG_ APA_ActivationSts : 401|3@0+ (1,0) [0|7] ""  mADC
 SG_ APA_CRCCheck_2C6 : 503|16@0+ (1,0) [0|65535] ""  mADC
 SG_ APA_RollingCounter_2C6 : 491|4@0+ (1,0) [0|15] ""  mADC
 SG_ APA_Condition_Notice : 391|5@0+ (1,0) [0|31] ""  mADC
 SG_ APA_TouchInfOnOffRes : 111|3@0+ (1,0) [0|7] ""  mADC
 SG_ APA_RADSNotice : 108|6@0+ (1,0) [0|63] ""  mADC
 SG_ APA_PowerMirrorFoldReq : 89|2@0+ (1,0) [0|3] ""  mADC
 SG_ APA_LAEBReq : 71|1@0+ (1,0) [0|1] ""  mADC
 SG_ APA_left_fishboneslot_type : 55|2@0+ (1,0) [0|3] ""  mADC
 SG_ APA_right_fishboneslot_type : 53|2@0+ (1,0) [0|3] ""  mADC
 SG_ APA_right_slot_4_available_sts : 185|2@0+ (1,0) [0|3] ""  mADC
 SG_ APA_right_slot_3_available_sts : 187|2@0+ (1,0) [0|3] ""  mADC
 SG_ APA_right_slot_2_available_sts : 189|2@0+ (1,0) [0|3] ""  mADC
 SG_ APA_right_slot_1_available_sts : 191|2@0+ (1,0) [0|3] ""  mADC
 SG_ APA_left_slot_4_available_sts : 177|2@0+ (1,0) [0|3] ""  mADC
 SG_ APA_left_slot_3_available_sts : 179|2@0+ (1,0) [0|3] ""  mADC
 SG_ APA_left_slot_2_available_sts : 181|2@0+ (1,0) [0|3] ""  mADC
 SG_ APA_left_slot_1_available_sts : 183|2@0+ (1,0) [0|3] ""  mADC
 SG_ APA_right_slot_4_distance_px : 161|10@0+ (1,0) [0|1023] ""  mADC
 SG_ APA_right_slot_4_type : 163|2@0+ (1,0) [0|3] ""  mADC
 SG_ APA_right_slot_3_distance_px : 157|10@0+ (1,0) [0|1023] ""  mADC
 SG_ APA_right_slot_3_type : 159|2@0+ (1,0) [0|3] ""  mADC
 SG_ APA_left_slot_4_distance_px : 137|10@0+ (1,0) [0|1023] ""  mADC
 SG_ APA_left_slot_4_type : 139|2@0+ (1,0) [0|3] ""  mADC
 SG_ APA_left_slot_3_distance_px : 133|10@0+ (1,0) [0|1023] ""  mADC
 SG_ APA_left_slot_3_type : 135|2@0+ (1,0) [0|3] ""  mADC
 SG_ APA_NumberofParkingSlot : 95|4@0+ (1,0) [0|15] ""  mADC
 SG_ APA_BCMHornCommand : 97|2@0+ (1,0) [0|3] ""  mADC
 SG_ APA_PEPS_EngineOffLockRequest : 101|1@0+ (1,0) [0|1] ""  mADC
 SG_ APA_RemoteParkingUsingRemind : 83|1@0+ (1,0) [0|1] ""  mADC
 SG_ APA_BLEConnectionRemind : 79|1@0+ (1,0) [0|1] ""  mADC
 SG_ APA_ReleasePressureReq : 100|1@0+ (1,0) [0|1] ""  mADC
 SG_ APA_LAEBNotice : 82|3@0+ (1,0) [0|7] ""  mADC
 SG_ APA_LAEBStatus : 78|3@0+ (1,0) [0|7] ""  mADC
 SG_ APA_ParkNotice_5 : 70|7@0+ (1,0) [0|127] ""  mADC
 SG_ APA_right_slot_2_distance_px : 33|10@0+ (1,0) [0|1023] "px"  mADC
 SG_ APA_right_slot_1_distance_px : 29|10@0+ (1,0) [0|1023] "px"  mADC
 SG_ APA_right_slot_2_type : 35|2@0+ (1,0) [0|3] ""  mADC
 SG_ APA_right_slot_1_type : 31|2@0+ (1,0) [0|3] ""  mADC
 SG_ APA_left_slot_2_distance_px : 9|10@0+ (1,0) [0|1023] "px"  mADC
 SG_ APA_left_slot_1_distance_px : 5|10@0+ (1,0) [0|1023] "px"  mADC
 SG_ APA_left_slot_2_type : 11|2@0+ (1,0) [0|3] ""  mADC
 SG_ APA_left_slot_1_type : 7|2@0+ (1,0) [0|3] ""  mADC

BO_ 798 BDC_31E: 64 Vector__XXX
 SG_ APA_RollingCounter_31E : 491|4@0+ (1,0) [0|15] ""  mADC
 SG_ APA_CRCCheck_31E : 503|16@0+ (1,0) [0|65535] ""  mADC
 SG_ APA_VoiceTipType : 494|3@0+ (1,0) [0|7] ""  mADC
 SG_ APA_ActiveSts : 295|1@0+ (1,0) [0|1] ""  mADC
 SG_ APA_ParkVoiceIntSet : 301|2@0+ (1,0) [0|3] ""  mADC
 SG_ APA_AVMNotice : 310|3@0+ (1,0) [0|7] ""  mADC
 SG_ RRS_LoudspeakersPosition : 67|4@0+ (1,0) [0|15] ""  mADC
 SG_ APA_SystemFailureFlag : 284|5@0+ (1,0) [0|31] ""  mADC
 SG_ APA_ObstacleSafeDistSetStatus : 287|3@0+ (-1,0) [-7|0] "cm"  mADC
 SG_ APA_Uls_FKP_WarningSoundStatus : 277|2@0+ (1,0) [0|3] ""  mADC
 SG_ APA_CrossParkingModeSetSts : 299|2@0+ (1,0) [0|3] ""  mADC
 SG_ APA_CRCCheck_3BA : 319|8@0+ (1,0) [0|255] ""  mADC
 SG_ APA_RollingCounter_3BA : 307|4@0+ (1,0) [0|15] ""  mADC
 SG_ ACC_LAEBEnableSts : 289|2@0+ (1,0) [0|3] ""  mADC
 SG_ APA_CRCCheck_2A7 : 255|8@0+ (1,0) [0|255] ""  mADC
 SG_ APA_RollingCounter_2A7 : 243|4@0+ (1,0) [0|15] ""  mADC
 SG_ RFS_Sector_Dist : 228|7@0+ (1,0) [0|127] "cm"  mADC
 SG_ LFS_Sector_Dist : 219|7@0+ (1,0) [0|127] "cm"  mADC
 SG_ RFC_Sector_Dist : 210|7@0+ (1,0) [0|127] "cm"  mADC
 SG_ LFC_Sector_Dist : 201|7@0+ (1,0) [0|127] "cm"  mADC
 SG_ RFM_Sector_Dist : 192|7@0+ (1,0) [0|127] "cm"  mADC
 SG_ LFM_Sector_Dist : 199|7@0+ (1,0) [0|127] "cm"  mADC
 SG_ APA_CRCCheck_2A6 : 191|8@0+ (1,0) [0|255] ""  mADC
 SG_ APA_RollingCounter_2A6 : 179|4@0+ (1,0) [0|15] ""  mADC
 SG_ RRS_Sector_Dist : 162|7@0+ (1,0) [0|127] "cm"  mADC
 SG_ LRS_Sector_Dist : 153|7@0+ (1,0) [0|127] "cm"  mADC
 SG_ RRC_Sector_Dist : 144|7@0+ (1,0) [0|127] "cm"  mADC
 SG_ LRC_Sector_Dist : 151|7@0+ (1,0) [0|127] "cm"  mADC
 SG_ RRM_Sector_Dist : 143|8@0+ (1,0) [0|255] "cm"  mADC
 SG_ LRM_Sector_Dist : 135|8@0+ (1,0) [0|255] "cm"  mADC
 SG_ RRF_Sector_Dist : 107|7@0+ (1,0) [0|127] "cm"  mADC
 SG_ LRF_Sector_Dist : 98|7@0+ (1,0) [0|127] "cm"  mADC
 SG_ RFF_Sector_Dist : 89|7@0+ (1,0) [0|127] "cm"  mADC
 SG_ LFF_Sector_Dist : 80|7@0+ (1,0) [0|127] "cm"  mADC
 SG_ RRS_FrontRadarActiveStatus : 62|2@0+ (1,0) [0|3] ""  mADC
 SG_ RRS_SwitchIndicatorError : 60|1@0+ (1,0) [0|1] ""  mADC
 SG_ RRS_ButtonPress : 49|1@0+ (1,0) [0|1] ""  mADC
 SG_ RRS_WarningType : 47|4@0+ (1,0) [0|15] ""  mADC
 SG_ RRS_WarningFrequency : 41|2@0+ (1,0) [0|3] ""  mADC
 SG_ RRS_LFSDistance : 58|3@0+ (1,0) [0|7] ""  mADC
 SG_ RRS_LRSDistance : 55|3@0+ (1,0) [0|7] ""  mADC
 SG_ RRS_RFSDistance : 52|3@0+ (1,0) [0|7] ""  mADC
 SG_ RRS_SideZoneStatus_Rear : 43|2@0+ (1,0) [0|3] ""  mADC
 SG_ RRS_SideZoneStatus_Front : 39|2@0+ (1,0) [0|3] ""  mADC
 SG_ RRS_RRSDistance : 37|3@0+ (1,0) [0|7] ""  mADC
 SG_ RRS_MODE : 34|3@0+ (1,0) [0|7] ""  mADC
 SG_ RRS_LFMDistance : 31|4@0+ (1,0) [0|15] ""  mADC
 SG_ RRS_RFMDistance : 27|4@0+ (1,0) [0|15] ""  mADC
 SG_ RRS_RFCDistance : 23|4@0+ (1,0) [0|15] ""  mADC
 SG_ RRS_LFCDistance : 19|4@0+ (1,0) [0|15] ""  mADC
 SG_ RRS_RRCDistance : 15|4@0+ (1,0) [0|15] ""  mADC
 SG_ RRS_LRCDistance : 11|4@0+ (1,0) [0|15] ""  mADC
 SG_ RRS_RRMDistance : 7|4@0+ (1,0) [0|15] ""  mADC
 SG_ RRS_LRMDistance : 3|4@0+ (1,0) [0|15] ""  mADC

BO_ 833 GW_341: 8 Vector__XXX
 SG_ PCU_PwrTqWhMinVld : 45|1@0+ (1,0) [0|1] ""  mADC
 SG_ PCU_PwrTqWhMinTotal : 4|16@0+ (1,-32768) [-32768|32767] "Nm"  mADC
 SG_ PCU_PwrTqWhMaxVld : 44|1@0+ (1,0) [0|1] ""  mADC
 SG_ PCU_PwrTqWhMaxTotal : 20|16@0+ (1,-32768) [-32768|32767] "Nm"  mADC
 SG_ PCU_AccPedShield : 43|1@0+ (1,0) [0|1] ""  mADC

BO_ 866 GW_362: 8 Vector__XXX
 SG_ PCU_eDTE : 45|9@0+ (1,0) [0|510] "km"  mADC

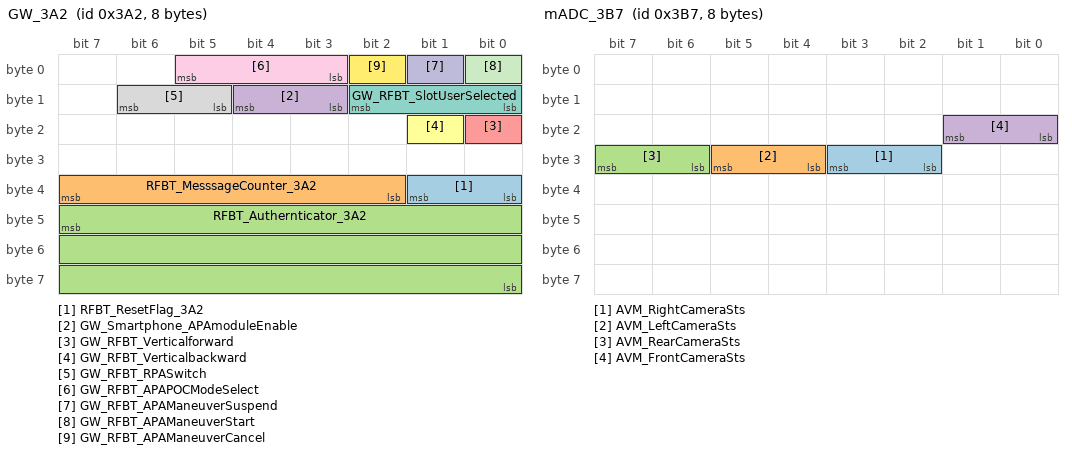
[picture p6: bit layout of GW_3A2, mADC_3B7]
BO_ 930 GW_3A2: 8 Vector__XXX
 SG_ RFBT_ResetFlag_3A2 : 33|2@0+ (1,0) [0|3] ""  mADC
 SG_ RFBT_MesssageCounter_3A2 : 39|6@0+ (1,0) [0|63] ""  mADC
 SG_ RFBT_Authernticator_3A2 : 47|24@0+ (1,0) [0|0] ""  mADC
 SG_ GW_Smartphone_APAmoduleEnable : 12|2@0+ (1,0) [0|3] ""  mADC
 SG_ GW_RFBT_Verticalforward : 16|1@0+ (1,0) [0|1] ""  mADC
 SG_ GW_RFBT_Verticalbackward : 17|1@0+ (1,0) [0|1] ""  mADC
 SG_ GW_RFBT_SlotUserSelected : 10|3@0+ (1,0) [0|7] ""  mADC
 SG_ GW_RFBT_RPASwitch : 14|2@0+ (1,0) [0|3] ""  mADC
 SG_ GW_RFBT_APAPOCModeSelect : 5|3@0+ (1,0) [0|7] ""  mADC
 SG_ GW_RFBT_APAManeuverSuspend : 1|1@0+ (1,0) [0|1] ""  mADC
 SG_ GW_RFBT_APAManeuverStart : 0|1@0+ (1,0) [0|1] ""  mADC
 SG_ GW_RFBT_APAManeuverCancel : 2|1@0+ (1,0) [0|1] ""  mADC

BO_ 951 mADC_3B7: 8 mADC
 SG_ AVM_RightCameraSts : 27|2@0+ (1,0) [0|3] "" Vector__XXX
 SG_ AVM_LeftCameraSts : 29|2@0+ (1,0) [0|3] "" Vector__XXX
 SG_ AVM_RearCameraSts : 31|2@0+ (1,0) [0|3] "" Vector__XXX
 SG_ AVM_FrontCameraSts : 17|2@0+ (1,0) [0|3] "" Vector__XXX

BO_ 982 GW_3D6: 8 Vector__XXX
 SG_ SLCM_RRWindowStatus : 40|8@0+ (0.5,0) [0|127.5] "%"  mADC
 SG_ SLCM_PassengerWindowStatus : 48|8@0+ (0.5,0) [0|127.5] "%"  mADC

BO_ 984 GW_3D8: 8 Vector__XXX
 SG_ SLCM_RLWindowStatus : 40|8@0+ (0.5,0) [0|127.5] "%"  mADC
 SG_ SLCM_DriverWindowStatus : 48|8@0+ (0.5,0) [0|127.5] "%"  mADC

BO_ 1006 GW_3EE: 8 Vector__XXX
 SG_ RFBT_BLEConnectSts : 2|3@0+ (1,0) [0|7] ""  mADC

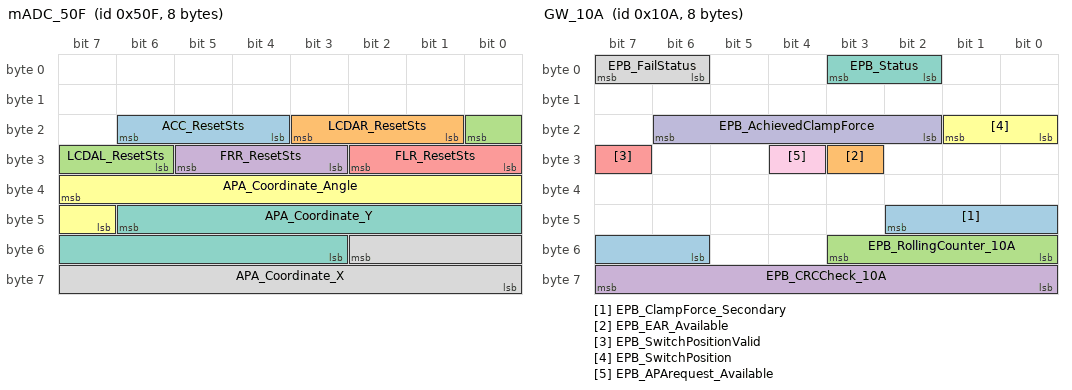
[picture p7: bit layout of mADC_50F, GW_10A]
BO_ 1295 mADC_50F: 8 mADC
 SG_ ACC_ResetSts : 22|3@0+ (1,0) [0|7] "" Vector__XXX
 SG_ LCDAR_ResetSts : 19|3@0+ (1,0) [0|7] "" Vector__XXX
 SG_ LCDAL_ResetSts : 16|3@0+ (1,0) [0|7] "" Vector__XXX
 SG_ FRR_ResetSts : 29|3@0+ (1,0) [0|7] "" Vector__XXX
 SG_ FLR_ResetSts : 26|3@0+ (1,0) [0|7] "" Vector__XXX
 SG_ APA_Coordinate_Angle : 39|9@0+ (1,-180) [-180|180] "degree" Vector__XXX
 SG_ APA_Coordinate_Y : 46|12@0+ (1,-1500) [-1500|500] "cm" Vector__XXX
 SG_ APA_Coordinate_X : 50|11@0+ (1,-500) [-500|500] "cm" Vector__XXX

BO_ 723 mADC_2D3: 64 mADC
 SG_ ACC_AEBTargetLatRelSpeed_for_SRS : 77|10@0+ (0.125,-64) [-64|63.875] "m/s" Vector__XXX
 SG_ ACC_AEBTargetLatRange_for_SRS : 71|10@0+ (0.1,-50) [-50|50] "m" Vector__XXX
 SG_ ACC_CRCCheckr_282 : 63|8@0+ (1,0) [0|255] "" Vector__XXX
 SG_ ACC_RollingCounter_282 : 51|4@0+ (1,0) [0|15] "" Vector__XXX
 SG_ ACC_AEBTargetProb_for_SRS : 38|7@0+ (1,0) [0|100] "%" Vector__XXX
 SG_ ACC_AEBTargetType_for_SRS : 26|4@0+ (1,0) [0|15] "" Vector__XXX
 SG_ ACC_AEBTargetTTC_for_SRS : 18|8@0+ (0.01,0.01) [0.01|2.5] "s" Vector__XXX
 SG_ ACC_AEBTargetRelSpeed_for_SRS : 11|9@0+ (1,-250) [-250|250] "km/h" Vector__XXX
 SG_ ACC_AEBTargetLngRange_for_SRS : 4|9@0+ (0.5,-70) [-70|180] "m" Vector__XXX
 SG_ ACC_AEBActive_for_SRS : 5|1@0+ (1,0) [0|1] "" Vector__XXX
 SG_ ACC_AEBStatus_for_SRS : 7|2@0+ (1,0) [0|3] "" Vector__XXX

BO_ 713 GW_2C9: 8 Vector__XXX
 SG_ HU_Ylevel : 23|16@0+ (1,0) [0|1920] ""  mADC
 SG_ HU_Xlevel : 7|16@0+ (1,0) [0|1920] ""  mADC

BO_ 881 GW_371: 8 Vector__XXX
 SG_ PCU_DrvMod2 : 31|3@0+ (1,0) [0|7] ""  mADC

BO_ 796 GW_31C: 8 Vector__XXX
 SG_ PCU_eDTEDisp : 50|11@0+ (1,0) [0|2047] "km"  mADC
 SG_ PCU_VcuRdySts : 16|1@0+ (1,0) [0|1] ""  mADC

BO_ 266 GW_10A: 8 Vector__XXX
 SG_ EPB_ClampForce_Secondary : 42|5@0+ (1,0) [0|31] ""  mADC
 SG_ EPB_EAR_Available : 27|1@0+ (1,0) [0|1] ""  mADC
 SG_ EPB_RollingCounter_10A : 51|4@0+ (1,0) [0|15] ""  mADC
 SG_ EPB_CRCCheck_10A : 63|8@0+ (1,0) [0|255] ""  mADC
 SG_ EPB_SwitchPositionValid : 31|1@0+ (1,0) [0|1] ""  mADC
 SG_ EPB_SwitchPosition : 17|2@0+ (1,0) [0|3] ""  mADC
 SG_ EPB_Status : 3|2@0+ (1,0) [0|3] ""  mADC
 SG_ EPB_FailStatus : 7|2@0+ (1,0) [0|3] ""  mADC
 SG_ EPB_APArequest_Available : 28|1@0+ (1,0) [0|1] ""  mADC
 SG_ EPB_AchievedClampForce : 22|5@0+ (1,0) [0|31] "KN"  mADC

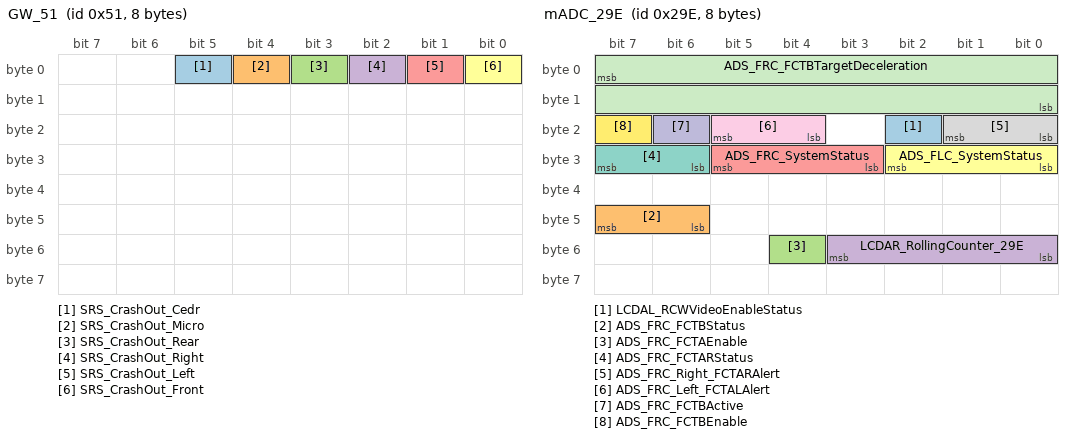
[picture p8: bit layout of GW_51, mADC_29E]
BO_ 81 GW_51: 8 Vector__XXX
 SG_ SRS_CrashOut_Cedr : 5|1@0+ (1,0) [0|1] ""  mADC
 SG_ SRS_CrashOut_Micro : 4|1@0+ (1,0) [0|1] ""  mADC
 SG_ SRS_CrashOut_Rear : 3|1@0+ (1,0) [0|1] ""  mADC
 SG_ SRS_CrashOut_Right : 2|1@0+ (1,0) [0|1] ""  mADC
 SG_ SRS_CrashOut_Left : 1|1@0+ (1,0) [0|1] ""  mADC
 SG_ SRS_CrashOut_Front : 0|1@0+ (1,0) [0|1] ""  mADC

BO_ 849 GW_351: 8 Vector__XXX
 SG_ AMB_Brightness : 21|10@0+ (30,0) [0|30690] "lux"  mADC
 SG_ FW_Brightness : 15|10@0+ (6,0) [0|6138] "lux"  mADC

BO_ 380 GW_17C: 32 Vector__XXX
 SG_ EMS_RollingCounter_1B7 : 179|4@0+ (1,0) [0|15] ""  mADC
 SG_ EMS_RngMod_trqCrSSetMinAvl : 153|10@0+ (1,-350) [-350|400] "Nm"  mADC
 SG_ EMS_RngMod_trqCrSSetMaxAvl : 147|10@0+ (1,-350) [-350|400] "Nm"  mADC
 SG_ EMS_RngMod_trqCrSLeadMinAvl : 141|10@0+ (1,-350) [-350|400] "Nm"  mADC
 SG_ EMS_RngMod_trqCrSLeadMaxAvl : 135|10@0+ (1,-350) [-350|400] "Nm"  mADC
 SG_ EMS_EngIdleTqFlywhMin : 175|10@0+ (1,-350) [-350|400] "Nm"  mADC
 SG_ EMS_CRCCheck_1B7 : 191|8@0+ (1,0) [0|255] ""  mADC
 SG_ EMS_RollingCounter_194 : 115|4@0+ (1,0) [0|15] ""  mADC
 SG_ EMS_IGNKL15Posn : 117|1@0+ (1,0) [0|1] ""  mADC
 SG_ EMS_IdleCtrlSts : 86|1@0+ (1,0) [0|1] ""  mADC
 SG_ EMS_EngTqFlywhFailr : 104|1@0+ (1,0) [0|1] ""  mADC
 SG_ EMS_EngTqFlywh : 88|16@0+ (0.02,-350) [-350|400] "Nm"  mADC
 SG_ EMS_EngSts : 119|2@0+ (1,0) [0|3] ""  mADC
 SG_ EMS_EngStrtSuccess : 90|1@0+ (1,0) [0|1] ""  mADC
 SG_ EMS_EngStopInhb : 93|3@0+ (1,0) [0|3] ""  mADC
 SG_ EMS_EngSpdErr : 71|1@0+ (1,0) [0|1] ""  mADC
 SG_ EMS_EngSpd : 70|16@0+ (0.25,0) [0|16383.5] "Rpm"  mADC
 SG_ EMS_EngRunReq : 85|3@0+ (1,0) [0|3] ""  mADC
 SG_ EMS_EngFuPumpSts : 95|2@0+ (1,0) [0|3] ""  mADC
 SG_ EMS_EngFuCutOff : 89|1@0+ (1,0) [0|1] ""  mADC
 SG_ EMS_CRCCheck_194 : 127|8@0+ (1,0) [0|255] ""  mADC
 SG_ EMS_RollingCounter_186 : 51|4@0+ (1,0) [0|15] ""  mADC
 SG_ EMS_RngMod_trqCrSLimtSts : 32|1@0+ (1,0) [0|1] ""  mADC
 SG_ EMS_RngMod_trqCrSLeadMin : 26|10@0+ (1,-350) [-350|400] "Nm"  mADC
 SG_ EMS_InterCoolerMotLopPumpSpdReq : 13|7@0+ (1,0) [0|100] "%"  mADC
 SG_ EMS_IdleSpdRef : 7|10@0+ (10,0) [0|10220] "rpm"  mADC
 SG_ EMS_EngTqFric : 22|12@0+ (0.1,0) [0|409.4] "Nm"  mADC
 SG_ EMS_EngIdleTqFlywh : 47|10@0+ (1,-350) [-350|400] "Nm"  mADC
 SG_ EMS_CRCCheck_186 : 63|8@0+ (1,0) [0|255] ""  mADC

BO_ 378 GW_17A: 64 Vector__XXX
 SG_ IBCU_TankTurn_Status : 93|2@0+ (1,0) [0|3] ""  mADC
 SG_ ESP_VehicleSpeedValid : 37|1@0+ (1,0) [0|1] ""  mADC
 SG_ ESP_VehicleSpeed : 36|13@0+ (0.05625,0) [0|360] "km/h"  mADC
 SG_ ESP_TCSFailStatus : 4|1@0+ (1,0) [0|1] ""  mADC
 SG_ ESP_RollingCounter_1DF : 371|4@0+ (1,0) [0|15] ""  mADC
 SG_ ESP_RollingCounter_187 : 51|4@0+ (1,0) [0|15] ""  mADC
 SG_ ESP_pMcVirtual_Q : 333|2@0+ (1,0) [0|2] ""  mADC
 SG_ ESP_pMcVirtual : 327|10@0+ (1,0) [0|250] "bar"  mADC
 SG_ ESP_MbRegenTarWhlRearQlfr : 247|2@0+ (1,0) [0|2] ""  mADC
 SG_ ESP_MbRegenTarWhlRear : 231|16@0+ (1,-32768) [-32768|0] "Nm"  mADC
 SG_ ESP_MbRegenTarWhlFrontQlfr : 168|2@0+ (1,0) [0|2] ""  mADC
 SG_ ESP_MbRegenTarWhlFront : 152|16@0+ (1,-32768) [-32768|32767] "Nm"  mADC
 SG_ ESP_ESPFunctionStatus : 1|1@0+ (1,0) [0|1] ""  mADC
 SG_ ESP_ESPActiveStatus : 0|1@0+ (1,0) [0|1] ""  mADC
 SG_ ESP_EngTorqIncRearActive : 200|1@0+ (1,0) [0|1] ""  mADC
 SG_ ESP_EngTorqIncFrontActive : 38|1@0+ (1,0) [0|1] ""  mADC
 SG_ ESP_EngTorqDecActive : 39|1@0+ (1,0) [0|1] ""  mADC
 SG_ ESP_CRCCheck_1DF : 383|8@0+ (1,0) [0|255] ""  mADC
 SG_ ESP_CRCCheck_187 : 63|8@0+ (1,0) [0|255] ""  mADC
 SG_ ESP_ABSFailStatus : 3|1@0+ (1,0) [0|1] ""  mADC
 SG_ ESP_ABSActiveStatus : 7|1@0+ (1,0) [0|1] ""  mADC

BO_ 670 mADC_29E: 8 mADC
 SG_ LCDAL_RCWVideoEnableStatus : 18|1@0+ (1,0) [0|1] "" Vector__XXX
 SG_ ADS_FRC_FCTBStatus : 47|2@0+ (1,0) [0|3] "" Vector__XXX
 SG_ ADS_FRC_FCTAEnable : 52|1@0+ (1,0) [0|1] "" Vector__XXX
 SG_ LCDAR_RollingCounter_29E : 51|4@0+ (1,0) [0|15] "" Vector__XXX
 SG_ ADS_FRC_SystemStatus : 29|3@0+ (1,0) [0|7] "" Vector__XXX
 SG_ ADS_FLC_SystemStatus : 26|3@0+ (1,0) [0|7] "" Vector__XXX
 SG_ ADS_FRC_FCTARStatus : 31|2@0+ (1,0) [0|3] "" Vector__XXX
 SG_ ADS_FRC_Right_FCTARAlert : 17|2@0+ (1,0) [0|3] "" Vector__XXX
 SG_ ADS_FRC_Left_FCTALAlert : 21|2@0+ (1,0) [0|3] "" Vector__XXX
 SG_ ADS_FRC_FCTBActive : 22|1@0+ (1,0) [0|1] "" Vector__XXX
 SG_ ADS_FRC_FCTBTargetDeceleration : 7|16@0+ (0.0005,-16) [-16|16] "m/s2" Vector__XXX
 SG_ ADS_FRC_FCTBEnable : 23|1@0+ (1,0) [0|1] "" Vector__XXX

BO_ 685 mADC_2AD: 64 mADC
 SG_ LCDAL_CRCCheck_2AD : 503|16@0+ (1,0) [0|65535] "" Vector__XXX
 SG_ LCDAL_RollingCounter_2AD : 491|4@0+ (1,0) [0|15] "" Vector__XXX
 SG_ LCDAL_CRCCheck_300 : 255|8@0+ (1,0) [0|255] "" Vector__XXX
 SG_ LCDAL_RollingCounter_300 : 243|4@0+ (1,0) [0|15] "" Vector__XXX
 SG_ LCDAL_CRCCheck_2F7 : 191|8@0+ (1,0) [0|255] "" Vector__XXX
 SG_ LCDAL_RollingCounter_2F7 : 179|4@0+ (1,0) [0|15] "" Vector__XXX
 SG_ LCDAL_CRCCheck_2EF : 127|8@0+ (1,0) [0|255] "" Vector__XXX
 SG_ LCDAL_RollingCounter_2EF : 115|4@0+ (1,0) [0|15] "" Vector__XXX
 SG_ LCDAL_CRCCheck_2AE : 63|8@0+ (1,0) [0|255] "" Vector__XXX
 SG_ LCDAL_RollingCounter_2AE : 51|4@0+ (1,0) [0|15] "" Vector__XXX
 SG_ LCDAL_Right_SEAAlert : 28|2@0+ (1,0) [0|3] "" Vector__XXX
 SG_ LCDAL_Right_RCWAlert : 21|2@0+ (1,0) [0|3] "" Vector__XXX
 SG_ LCDAL_SEAStatus : 36|2@0+ (1,0) [0|3] "" Vector__XXX
 SG_ LCDAL_SEAAlert : 38|2@0+ (1,0) [0|3] "" Vector__XXX
 SG_ LCDAL_SEAEnableStatus : 24|1@0+ (1,0) [0|1] "" Vector__XXX
 SG_ LCDAL_RCWStatus : 30|2@0+ (1,0) [0|3] "" Vector__XXX
 SG_ LCDAL_RCWAlert : 16|2@0+ (1,0) [0|3] "" Vector__XXX
 SG_ LCDAL_RCWEnableStatus : 18|1@0+ (1,0) [0|1] "" Vector__XXX
 SG_ LCDAL_SystemStatus : 6|3@0+ (1,0) [0|7] "" Vector__XXX

BO_ 879 mADC_36F: 64 mADC
 SG_ ADS_NDAStatus : 288|4@0+ (1,0) [0|15] "" Vector__XXX
 SG_ ADS_NDATextInfo : 294|6@0+ (1,0) [0|63] "" Vector__XXX
 SG_ ADS_NIDOutDis : 286|8@0+ (10,0) [0|2550] "" Vector__XXX
 SG_ LAS_OverspeedWarningRatioOffset_ : 397|6@0+ (0.5,-3) [-3|63] "%" Vector__XXX
 SG_ LAS_TSRSpeedLimitChangeSoundEnSt : 407|2@0+ (1,0) [0|3] "" Vector__XXX
 SG_ LAS_TSRSpeedLimitStatus : 399|2@0+ (1,0) [0|3] "" Vector__XXX
 SG_ LAS_TSRNavCountryCode : 391|8@0+ (1,0) [0|255] "" Vector__XXX
 SG_ RADS_DynamicButton : 118|3@0+ (1,0) [0|7] "" Vector__XXX
 SG_ LAS_OverspeedWarningRatioOffset : 360|6@0+ (1,-10) [-10|53] "%" Vector__XXX
 SG_ APA_RPA_Notice : 356|5@0+ (1,0) [0|31] "" Vector__XXX
 SG_ APA_FunRecomReq : 214|2@0+ (1,0) [0|3] "" Vector__XXX
 SG_ ADS_RoadLngRange : 87|8@0+ (1,0) [0|255] "m" Vector__XXX
 SG_ ACC_RollingCounter_36F : 491|4@0+ (1,0) [0|15] "" Vector__XXX
 SG_ ACC_CRCCheck_36F : 503|16@0+ (1,0) [0|65535] "" Vector__XXX
 SG_ ADS_TunnelStatus : 265|2@0+ (1,0) [0|3] "" Vector__XXX
 SG_ ADS_TunnelDis : 279|9@0+ (1,0) [0|400] "m" Vector__XXX
 SG_ ADS_RampStatus : 268|3@0+ (1,0) [0|3] "" Vector__XXX
 SG_ ADS_PathThroughRamp : 270|2@0+ (1,0) [0|3] "" Vector__XXX
 SG_ ADS_RampSide : 246|2@0+ (1,0) [0|3] "" Vector__XXX
 SG_ ADS_DisToRamp : 263|9@0+ (1,0) [0|400] "m" Vector__XXX
 SG_ ADS_PathShowLngRange : 238|8@0+ (1,0) [0|200] "m" Vector__XXX
 SG_ ADS_RoadMergeLatRange : 218|12@0+ (0.01,-16) [-16|16] "m" Vector__XXX
 SG_ ADS_AutoDriveStateDisplay : 196|4@0+ (1,0) [0|15] "" Vector__XXX
 SG_ ADS_PathShow_Status : 183|3@0+ (1,0) [0|7] "" Vector__XXX
 SG_ ADS_PathShow_C3 : 163|12@0+ (4.768E-007,-0.0009760857) [-0.0009760857|0.0009760857] "" Vector__XXX
 SG_ ADS_PathShow_C2 : 159|12@0+ (1.52588E-005,-0.0312347412) [-0.0312347412|0.0312347412] "" Vector__XXX
 SG_ ADS_PathShow_C1 : 139|12@0+ (0.0004882813,-1) [-1|0.9990234375] "" Vector__XXX
 SG_ ACC_TakeoverReqAtIPFail : 71|2@0+ (1,0) [0|3] "" Vector__XXX
 SG_ ADS_TSRHostNextSpdLimitDist : 23|9@0+ (1,0) [0|400] "" Vector__XXX
 SG_ ADS_TSRHostNextSpdLimit : 15|8@0+ (1,0) [0|255] "" Vector__XXX

BO_ 1535 GW_5FF: 8 Vector__XXX
 SG_ BCM_RemoteReadyReq : 47|2@0+ (1,0) [0|3] ""  mADC

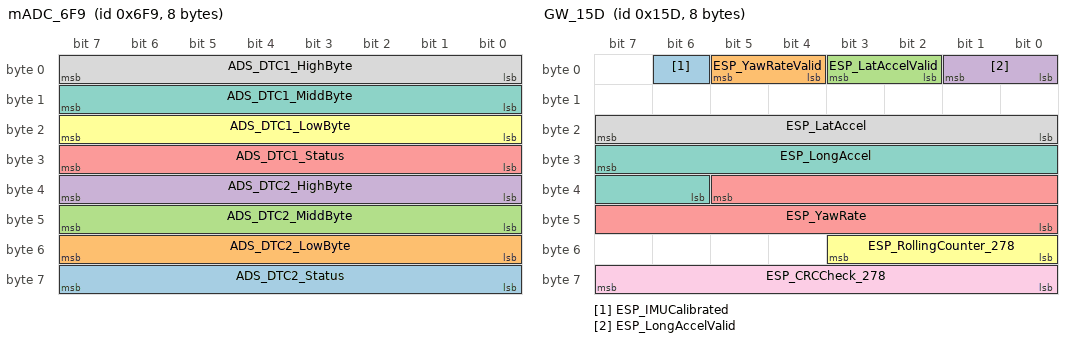
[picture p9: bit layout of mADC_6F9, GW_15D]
BO_ 1785 mADC_6F9: 8 mADC
 SG_ ADS_DTC2_Status : 63|8@0+ (1,0) [0|255] "" Vector__XXX
 SG_ ADS_DTC2_LowByte : 55|8@0+ (1,0) [0|255] "" Vector__XXX
 SG_ ADS_DTC2_MiddByte : 47|8@0+ (1,0) [0|255] "" Vector__XXX
 SG_ ADS_DTC2_HighByte : 39|8@0+ (1,0) [0|255] "" Vector__XXX
 SG_ ADS_DTC1_Status : 31|8@0+ (1,0) [0|255] "" Vector__XXX
 SG_ ADS_DTC1_LowByte : 23|8@0+ (1,0) [0|255] "" Vector__XXX
 SG_ ADS_DTC1_MiddByte : 15|8@0+ (1,0) [0|255] "" Vector__XXX
 SG_ ADS_DTC1_HighByte : 7|8@0+ (1,0) [0|255] "" Vector__XXX

BO_ 349 GW_15D: 8 Vector__XXX
 SG_ ESP_IMUCalibrated : 6|1@0+ (1,0) [0|1] ""  mADC
 SG_ ESP_YawRateValid : 5|2@0+ (1,0) [0|3] ""  mADC
 SG_ ESP_LatAccelValid : 3|2@0+ (1,0) [0|3] ""  mADC
 SG_ ESP_LongAccelValid : 1|2@0+ (1,0) [0|3] ""  mADC
 SG_ ESP_YawRate : 37|14@0+ (0.01,-81.91) [-81.91|81.91] "degree/s"  mADC
 SG_ ESP_RollingCounter_278 : 51|4@0+ (1,0) [0|15] ""  mADC
 SG_ ESP_LongAccel : 31|10@0+ (0.03125,-16) [-16|15.90625] "m/s2"  mADC
 SG_ ESP_LatAccel : 23|8@0+ (0.1,-12.7) [-12.7|12.7] "m/s2"  mADC
 SG_ ESP_CRCCheck_278 : 63|8@0+ (1,0) [0|255] ""  mADC

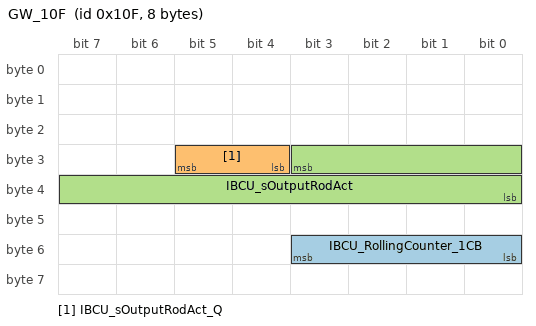
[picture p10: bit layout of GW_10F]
BO_ 271 GW_10F: 8 Vector__XXX
 SG_ IBCU_RollingCounter_1CB : 51|4@0+ (1,0) [0|15] ""  mADC
 SG_ IBCU_sOutputRodAct_Q : 29|2@0+ (1,0) [0|3] ""  mADC
 SG_ IBCU_sOutputRodAct : 27|12@0+ (0.015625,-5) [-5|47] "mm"  mADC

CM_ BO_ 947 " ";
CM_ BO_ 957 " ";
CM_ SG_ 957 HU_ALCModeSelection " ";
CM_ SG_ 957 HU_SentryModeSt " ";
CM_ SG_ 957 HU_AutoHeadLiSet " ";
CM_ SG_ 957 HU_RADSSwitch " ";
CM_ SG_ 957 HU_RollingCounter_394 " ";
CM_ SG_ 957 HU_UDLCEnable " ";
CM_ SG_ 957 HU_ESSEnable " ";
CM_ SG_ 957 HU_ELKEnable " ";
CM_ SG_ 957 HU_TLAEnable " ";
CM_ BO_ 964 " ";
CM_ SG_ 964 HU_Indication_BusLane_Dis " ";
CM_ SG_ 964 HU_Indication_PedestrianCro_Dis " ";
CM_ SG_ 964 HU_Indication_MainRoadPri_Dis " ";
CM_ SG_ 964 HU_Indication_Walk_Dis " ";
CM_ SG_ 964 HU_Indication_OneWay_Dis " ";
CM_ SG_ 964 HU_Prohibitory_GiveWayOncom_Dis " ";
CM_ SG_ 964 HU_Prohibitory_Honking_Dis " ";
CM_ SG_ 964 HU_Prohibitory_Enter_Dis " ";
CM_ SG_ 964 HU_Prohibitory_StopToGiveWay_Dis " ";
CM_ SG_ 964 HU_Indication_BusLane " ";
CM_ SG_ 964 HU_Indication_PedestrianCrossing " ";
CM_ SG_ 964 HU_Indication_MainRoadPriority " ";
CM_ SG_ 964 HU_Indication_Walk " ";
CM_ SG_ 964 HU_Indication_OneWay " ";
CM_ SG_ 964 HU_Prohibitory_GiveWayToOncoming " ";
CM_ SG_ 964 HU_Prohibitory_Honking " ";
CM_ SG_ 964 HU_Prohibitory_Enter " ";
CM_ SG_ 964 HU_Prohibitory_StopToGiveWay " ";
CM_ SG_ 964 HU_Prohibitory_SpeedLimit " ";
CM_ SG_ 964 HU_Prohibitory_VehParkLongTime " ";
CM_ SG_ 964 HU_Prohibitory_VehicleParking " ";
CM_ SG_ 964 HU_Prohibitory_Overtake " ";
CM_ SG_ 964 HU_Prohibitory_Uturn " ";
CM_ SG_ 964 HU_Prohibitory_Straight " ";
CM_ SG_ 964 HU_Prohibitory_TurnRight " ";
CM_ SG_ 964 HU_Prohibitory_MotorVehicles " ";
CM_ SG_ 964 HU_Prohibitory_DriveInto " ";
CM_ SG_ 964 HU_Warning_RoadWorks " ";
CM_ SG_ 964 HU_Warning_Slow " ";
CM_ SG_ 964 HU_Warning_Tunnel " ";
CM_ SG_ 964 HU_Warning_Slip " ";
CM_ SG_ 964 HU_Warning_Pedestrian " ";
CM_ SG_ 964 HU_Warning_ContinuousDetours " ";
CM_ SG_ 964 HU_Warning_ReverseCurve " ";
CM_ SG_ 964 HU_CrossingAngle4 " ";
CM_ SG_ 964 HU_CrossingAngle3 " ";
CM_ SG_ 964 HU_CrossingAngle2 " ";
CM_ SG_ 964 HU_CrossingAngle1 " ";
CM_ SG_ 964 HU_EnterRoundaboutInfo " ";
CM_ SG_ 964 HU_RoundaboutDistance " ";
CM_ SG_ 964 HU_EnterCrossingInfo " ";
CM_ SG_ 964 HU_CrossingDistance " ";
CM_ SG_ 964 HU_MapMatchStatus " ";
CM_ SG_ 964 HU_MapDataUpdateStatus " ";
CM_ SG_ 964 HU_SlopeGradient_300m " ";
CM_ SG_ 964 HU_RoadCurvature_600m " ";
CM_ SG_ 964 HU_RoadCurvature_400m " ";
CM_ SG_ 964 HU_RoadCurvature_300m " ";
CM_ SG_ 964 HU_RoadCurvature_100m " ";
CM_ SG_ 964 HU_RoadCurvature_90m " ";
CM_ SG_ 964 HU_RoadCurvature_80m " ";
CM_ SG_ 964 HU_RoadCurvature_70m " ";
CM_ SG_ 964 HU_RoadCurvature_60m " ";
CM_ SG_ 964 HU_RoadCurvature_50m " ";
CM_ SG_ 964 HU_RoadCurvature_40m " ";
CM_ SG_ 964 HU_RoadCurvature_30m " ";
CM_ SG_ 964 HU_RoadCurvature_20m " ";
CM_ SG_ 964 HU_RoadCurvature_10m " ";
CM_ SG_ 964 HU_Road_TrafficFlow " ";
CM_ SG_ 964 HU_Lane_Changtype " ";
CM_ SG_ 964 HU_To_NumchangeOfLanes_Dist " ";
CM_ SG_ 964 HU_To_Branch_Dis " ";
CM_ SG_ 964 HU_To_TrafficAccident_Dis " ";
CM_ SG_ 964 HU_TrafficAccident_Info " ";
CM_ SG_ 964 HU_To_Construction_Dis " ";
CM_ SG_ 964 HU_Construction_Info " ";
CM_ SG_ 964 HU_TollDis " ";
CM_ SG_ 964 HU_TollInfo " ";
CM_ SG_ 964 HU_FallingRockDi " ";
CM_ SG_ 964 HU_FallingRockInfo " ";
CM_ SG_ 964 HU_LaneCnt " ";
CM_ SG_ 964 HU_ForwardRoadType " ";
CM_ SG_ 964 HU_RampSide " ";
CM_ BO_ 1021 " ";
CM_ SG_ 1021 BCM_AutHeadLiSts " ";
CM_ SG_ 1021 BCM_DriveMode "ACC 主控则ACC接收，LAS 主控则LAS接收 ";
CM_ BO_ 1023 " ";
CM_ SG_ 1023 BCM_HighBeamLampError " ";
CM_ BO_ 1683 " ";
CM_ SG_ 1683 ACC_DTC2_Status "DTC上传 ";
CM_ SG_ 1683 ACC_DTC2_LowByte "DTC上传 ";
CM_ SG_ 1683 ACC_DTC2_MiddByte "DTC上传 ";
CM_ SG_ 1683 ACC_DTC2_HighByte "DTC上传 ";
CM_ SG_ 1683 ACC_DTC1_Status "DTC上传 ";
CM_ SG_ 1683 ACC_DTC1_LowByte "DTC上传 ";
CM_ SG_ 1683 ACC_DTC1_MiddByte "DTC上传 ";
CM_ SG_ 1683 ACC_DTC1_HighByte "DTC上传 ";
CM_ BO_ 652 "GW自发MFS_LIN_2 ";
CM_ SG_ 652 GW_MFS_CRCCheck_28C "GW对LIN的CRC重新计算并发出 ";
CM_ BO_ 372 " ";
CM_ SG_ 372 APA_ReqSYNMSG "见《车端消息认证集成规范》
触发时连续发送3帧，帧间隔50ms ";
CM_ BO_ 431 " ";
CM_ SG_ 431 TCU_ShiftPostionValid "APA配置接收方无BDC ";
CM_ SG_ 431 TCU_GearShiftPosition "TCU receives driver demands gear from ESL and make decisition of actual drive mode based on current vehicle/transmission status.
PCU receives this signals to understand actual drive mode and estimate target gear ";
CM_ SG_ 431 TCU_CRCCheck_1A8 "CRCCheck_SAE_J1850_2001,multinomial is X8+X4+X3+X2+1 ";
CM_ SG_ 431 TCU_ActualDrivingGearValid "APA配置接收方无BDC ";
CM_ SG_ 431 TCU_ActualDrivingGear "RMU法规要求
Message relaying what the current engaged gear is (On DCT this will also be the gear on the shaft with the engaged clutch). ";
CM_ BO_ 800 "GW自发 ";
CM_ SG_ 800 GW_DCANDiagSts " ";
CM_ SG_ 800 GW_OTAmode_Chks "与GW_OTAmode分配到一个ID的相邻字节 ";
CM_ SG_ 800 GW_OTAmode_Cntr "与GW_OTAmode分配到1个字节 ";
CM_ SG_ 800 GW_OTAmode "与GW_OTAmode_Cntr分配到1个字节 ";
CM_ SG_ 800 GW_ResetReq " ";
CM_ BO_ 922 " ";
CM_ SG_ 922 LAS_TSRRightLaneStatus "GW报文转发 ";
CM_ SG_ 922 LAS_TSRLeftLaneStatus "GW报文转发 ";
CM_ SG_ 922 LAS_CRCCheck_3C0 "
 ";
CM_ SG_ 922 LAS_RollingCounter_3C0 "rolling counter ";
CM_ SG_ 922 LAS_TSRRightLaneSpdLimit "GW报文转发
0x0=no speed limit detected;
0x1=SL5;
0x2=SL10;
…
0x32=SL160;
0x33~0x253= Reserved;
0x254=Unknown;
0x255=SLEND ";
CM_ SG_ 922 LAS_TSRLeftLaneSpdLimit "GW报文转发
0x0=no speed limit detected;
0x1=SL5;
0x2=SL10;
…
0x32=SL160;
0x33~0x253= Reserved;
0x254=Unknown;
0x255=SLEND ";
CM_ SG_ 922 LAS_CRCCheck_3D4 "
 ";
CM_ SG_ 922 LAS_RollingCounter_3D4 "rolling counter ";
CM_ SG_ 922 LAS_TLAStopLine_HostLane " ";
CM_ SG_ 922 LAS_TLADistance_HostLane " ";
CM_ SG_ 922 LAS_TLACountDownTime_HostLane " ";
CM_ SG_ 922 LAS_TSRMandatorySign " ";
CM_ SG_ 922 LAS_TSRWarningSign " ";
CM_ SG_ 922 LAS_TSRProhibitionSign " ";
CM_ SG_ 922 LAS_CRCCheck_332 "
 ";
CM_ SG_ 922 LAS_RollingCounter_332 "rolling counter ";
CM_ SG_ 922 LAS_HMALightDistribution "GW报文转发 ";
CM_ SG_ 922 LAS_HMAStatus "GW报文转发 ";
CM_ SG_ 922 LAS_TSRHostSpdLimitUnits "GW报文转发 ";
CM_ SG_ 922 LAS_TSRStatus "GW报文转发 ";
CM_ SG_ 922 LAS_FrontCameraCalibrationStatus "有LAS时由LAS发送，其余由APA或AVM发送 ";
CM_ SG_ 922 LAS_FrontCameraFailureStatus "有LAS时由LAS发送，其余由APA或AVM发送 ";
CM_ SG_ 922 LAS_CRCCheck_37D " ";
CM_ SG_ 922 LAS_RollingCounter_37D "rolling counter ";
CM_ SG_ 922 LAS_TLAArrowDirection_RightLane " ";
CM_ SG_ 922 LAS_TLAObjectType_RightLane " ";
CM_ SG_ 922 LAS_TLAObjectStatus_RightLane " ";
CM_ SG_ 922 LAS_TLAObjectColour_RightLane " ";
CM_ SG_ 922 LAS_TLAObjectDetection_RightLane " ";
CM_ SG_ 922 LAS_TLAArrowDirection_LeftLane " ";
CM_ SG_ 922 LAS_TLAObjectType_LeftLane " ";
CM_ SG_ 922 LAS_TLAObjectStatus_LeftLane " ";
CM_ SG_ 922 LAS_TLAObjectColour_LeftLane " ";
CM_ SG_ 922 LAS_TLAObjectDetection_LeftLane " ";
CM_ SG_ 922 LAS_TLAArrowDirection_HostLane " ";
CM_ SG_ 922 LAS_TLAObjectStatus_HostLane " ";
CM_ SG_ 922 LAS_TLAObjectType_HostLane " ";
CM_ SG_ 922 LAS_TLAObjectColour_HostLane " ";
CM_ SG_ 922 LAS_TLAObjectDetection_HostLane " ";
CM_ SG_ 922 LAS_TLAWarninglevel " ";
CM_ SG_ 922 LAS_TLAStatus " ";
CM_ SG_ 922 LAS_TLAEnable " ";
CM_ BO_ 906 "GW自发 ";
CM_ BO_ 583 " ";
CM_ SG_ 583 APA_SlotNotice_1 "GW接收并加密，再密文转发至蓝牙模块到手机APP接收 ";
CM_ SG_ 583 APA_VCUReadyReq " ";
CM_ SG_ 583 APA_FunctionOnOffSts "(网关加密发送给RFBT)
APA配置发送方为APA ";
CM_ SG_ 583 APA_SteeringAngleReq "即PAS_PSC_SetSteeringWheel
Ang ";
CM_ SG_ 583 APA_ErrorStatus "即PAS_PSC_Status ";
CM_ SG_ 583 APA_SteeringAngleReqProtection "PAS_PSC_EPS_Control_Requ
est ";
CM_ SG_ 583 APA_RollingCounter_26C "建议改为100ms ";
CM_ SG_ 583 APA_AccPedShieldReq "GW报文转发 ";
CM_ SG_ 583 APA_SlotNotice "GW接收并加密，再密文转发至蓝牙模块到手机APP接收 ";
CM_ SG_ 583 APA_DynamicSlotWarning "连发5帧 ";
CM_ SG_ 583 APA_EPBrequestValid "APA配置发送方为APA ";
CM_ SG_ 583 APA_EPBrequest "APA配置发送方为APA ";
CM_ SG_ 583 APA_CRCCheck_247 " ";
CM_ SG_ 583 APA_RollingCounter_247 "rolling counter ";
CM_ BO_ 610 " ";
CM_ BO_ 917 " ";
CM_ SG_ 917 TBOX_APP_Ylevel " ";
CM_ SG_ 917 TBOX_APP_Xlevel " ";
CM_ SG_ 917 TBOX_APAControlEnable " ";
CM_ SG_ 917 TBOX_RemoteStartReq " ";
CM_ SG_ 917 TBOX_APAFunctionReq " ";
CM_ SG_ 917 TBOX_SignalStrength " ";
CM_ SG_ 917 TBOX_SignalType " ";
CM_ SG_ 917 TBOX_APA_SignalDelay " ";
CM_ SG_ 917 TBOX_APAmoduleEnable " ";
CM_ SG_ 917 TBOX_RemoteDisReq "GW报文转发 ";
CM_ SG_ 917 TBOX_VehicleVedioDetectReq "GW报文转发 ";
CM_ SG_ 917 TBOX_RemoteDetectReq "GW报文转发 ";
CM_ BO_ 1344 " ";
CM_ SG_ 1344 APA_HornRq "APA配置发送方为APA ";
CM_ SG_ 1344 APA_HighLampRq " ";
CM_ SG_ 1344 APA_RigtLowLampRq " ";
CM_ SG_ 1344 APA_LeftLowLampRq " ";
CM_ BO_ 1360 " ";
CM_ SG_ 1360 APA_RightRearWindowControl " ";
CM_ SG_ 1360 APA_LeftRearWindowControl " ";
CM_ SG_ 1360 APA_PassengerWindowControl " ";
CM_ SG_ 1360 APA_DriverWindowControl " ";
CM_ SG_ 1360 APA_MirrorAutoFoldReq " ";
CM_ SG_ 1360 APA_DoorLockRq " ";
CM_ SG_ 1360 APA_HiddenHandleControlReq " ";
CM_ BO_ 1364 " ";
CM_ BO_ 1554 " ";
CM_ SG_ 1554 DVR_EmergencyRecordStatus "
 ";
CM_ BO_ 394 " ";
CM_ SG_ 394 TCU_APAShiftGearRequestEnable "APA配置接收方无BDC ";
CM_ SG_ 394 TCU_APAdriverInterruption "APA配置接收方无BDC ";
CM_ BO_ 586 " ";
CM_ SG_ 586 ESL_CRCCheck_24A "ACM接收为AT专用 ";
CM_ SG_ 586 ESL_RollingCounter_24A "ACM接收为AT专用 ";
CM_ SG_ 586 ESL_DriveModeRequest "ACM接收为AT专用
原信号名称ESL_DriveModePosition，CD569、S202DA使用 ";
CM_ SG_ 586 ESL_DriverParkButtonFaultStatus "TCU接收为DCT专用
ACM接收为AT专用
原信号名称ESL_DriverParkButtonStatus，CD569、S202DA使用 ";
CM_ SG_ 586 ESL_DriverParkRequest "TCU接收为DCT专用
ACM接收为AT专用 ";
CM_ SG_ 586 ESL_ShiftLeverPositionrequest "ACM接收为AT专用
原信号名称ESL_ShiftLeverPositon，CD569、S202DA使用 ";
CM_ SG_ 586 ESL_ShiftLeverPositionFaultSts "TCU接收为DCT专用
ACM接收为AT专用
原信号名称ESL_ShiftLeverStatus，CD569、S202DA使用 ";
CM_ BO_ 604 "GW自发 ";
CM_ SG_ 604 GW_Authernticator_25C " ";
CM_ SG_ 604 GW_ResetCounter_25C " ";
CM_ SG_ 604 GW_TripCounter_25C " ";
CM_ BO_ 710 " ";
CM_ SG_ 710 APA_FunctionOnOffSts "(网关加密发送给RFBT)
APA配置发送方为APA ";
CM_ SG_ 710 APA_ParkingSlot_Width " ";
CM_ SG_ 710 APA_ParkingSlot_Length " ";
CM_ SG_ 710 APA_ParkingSlot_ExtraFeature " ";
CM_ SG_ 710 APA_ParkingSlot_Type " ";
CM_ SG_ 710 APA_ActivationSts " ";
CM_ SG_ 710 APA_CRCCheck_2C6 " ";
CM_ SG_ 710 APA_RollingCounter_2C6 "rolling counter ";
CM_ SG_ 710 APA_Condition_Notice " ";
CM_ SG_ 710 APA_RADSNotice " ";
CM_ SG_ 710 APA_PowerMirrorFoldReq "APA配置发送方为APA ";
CM_ SG_ 710 APA_LAEBReq "网关报文转发 ";
CM_ SG_ 710 APA_left_fishboneslot_type "1.报文转发至InfoCAN
2.GW接收并加密，再密文转发至蓝牙模块手机APP接收 ";
CM_ SG_ 710 APA_right_fishboneslot_type "1.报文转发至InfoCAN
2.GW接收并加密，再密文转发至蓝牙模块手机APP接收 ";
CM_ SG_ 710 APA_right_slot_4_available_sts "1.报文转发至InfoCAN
2.GW接收并加密，再密文转发至蓝牙模块手机APP接收 ";
CM_ SG_ 710 APA_right_slot_3_available_sts "1.报文转发至InfoCAN
2.GW接收并加密，再密文转发至蓝牙模块手机APP接收 ";
CM_ SG_ 710 APA_right_slot_2_available_sts "1.报文转发至InfoCAN
2.GW接收并加密，再密文转发至蓝牙模块手机APP接收 ";
CM_ SG_ 710 APA_right_slot_1_available_sts "1.报文转发至InfoCAN
2.GW接收并加密，再密文转发至蓝牙模块手机APP接收 ";
CM_ SG_ 710 APA_left_slot_4_available_sts "1.报文转发至InfoCAN
2.GW接收并加密，再密文转发至蓝牙模块手机APP接收 ";
CM_ SG_ 710 APA_left_slot_3_available_sts "1.报文转发至InfoCAN
2.GW接收并加密，再密文转发至蓝牙模块手机APP接收 ";
CM_ SG_ 710 APA_left_slot_2_available_sts "1.报文转发至InfoCAN
2.GW接收并加密，再密文转发至蓝牙模块手机APP接收 ";
CM_ SG_ 710 APA_left_slot_1_available_sts "1.报文转发至InfoCAN
2.GW接收并加密，再密文转发至蓝牙模块手机APP接收 ";
CM_ SG_ 710 APA_right_slot_4_distance_px "1.报文转发至InfoCAN
2.GW接收并加密，再密文转发至蓝牙模块手机APP接收 ";
CM_ SG_ 710 APA_right_slot_4_type "1.报文转发至InfoCAN
2.GW接收并加密，再密文转发至蓝牙模块手机APP接收 ";
CM_ SG_ 710 APA_right_slot_3_distance_px "1.报文转发至InfoCAN
2.GW接收并加密，再密文转发至蓝牙模块手机APP接收 ";
CM_ SG_ 710 APA_right_slot_3_type "1.报文转发至InfoCAN
2.GW接收并加密，再密文转发至蓝牙模块手机APP接收 ";
CM_ SG_ 710 APA_left_slot_4_distance_px "1.报文转发至InfoCAN
2.GW接收并加密，再密文转发至蓝牙模块手机APP接收 ";
CM_ SG_ 710 APA_left_slot_4_type "1.报文转发至InfoCAN
2.GW接收并加密，再密文转发至蓝牙模块手机APP接收 ";
CM_ SG_ 710 APA_left_slot_3_distance_px "1.报文转发至InfoCAN
2.GW接收并加密，再密文转发至蓝牙模块手机APP接收 ";
CM_ SG_ 710 APA_left_slot_3_type "1.报文转发至InfoCAN
2.GW接收并加密，再密文转发至蓝牙模块手机APP接收 ";
CM_ SG_ 710 APA_NumberofParkingSlot "网关报文转发 ";
CM_ SG_ 710 APA_BCMHornCommand "APA配置发送方为APA ";
CM_ SG_ 710 APA_RemoteParkingUsingRemind "(网关加密发送给RFBT) ";
CM_ SG_ 710 APA_BLEConnectionRemind "APA配置发送方为APA ";
CM_ SG_ 710 APA_ReleasePressureReq "1、博世提出不能用一个信号表示两种状态，新增的信号
2、APA配置发送方为APA ";
CM_ SG_ 710 APA_LAEBNotice " ";
CM_ SG_ 710 APA_LAEBStatus " ";
CM_ SG_ 710 APA_ParkNotice_5 "(网关加密发送给RFBT)
APA配置发送方为APA ";
CM_ SG_ 710 APA_right_slot_2_distance_px "GW报文转发 ";
CM_ SG_ 710 APA_right_slot_1_distance_px "GW报文转发 ";
CM_ SG_ 710 APA_right_slot_2_type "GW报文转发 ";
CM_ SG_ 710 APA_right_slot_1_type "GW报文转发 ";
CM_ SG_ 710 APA_left_slot_2_distance_px "GW报文转发 ";
CM_ SG_ 710 APA_left_slot_1_distance_px "GW报文转发 ";
CM_ SG_ 710 APA_left_slot_2_type "GW报文转发 ";
CM_ SG_ 710 APA_left_slot_1_type "GW报文转发 ";
CM_ BO_ 798 " ";
CM_ SG_ 798 APA_SystemFailureFlag "GW报文转发 ";
CM_ SG_ 798 APA_CRCCheck_2A7 "GW报文转发 ";
CM_ SG_ 798 APA_RollingCounter_2A7 "GW报文转发 ";
CM_ SG_ 798 RFS_Sector_Dist "GW报文转发 ";
CM_ SG_ 798 LFS_Sector_Dist "GW报文转发 ";
CM_ SG_ 798 RFC_Sector_Dist "GW报文转发 ";
CM_ SG_ 798 LFC_Sector_Dist "GW报文转发 ";
CM_ SG_ 798 RFM_Sector_Dist "GW报文转发 ";
CM_ SG_ 798 LFM_Sector_Dist "GW报文转发 ";
CM_ SG_ 798 APA_CRCCheck_2A6 "GW报文转发 ";
CM_ SG_ 798 APA_RollingCounter_2A6 "GW报文转发 ";
CM_ SG_ 798 RRS_Sector_Dist "GW报文转发 ";
CM_ SG_ 798 LRS_Sector_Dist "GW报文转发 ";
CM_ SG_ 798 RRC_Sector_Dist "GW报文转发 ";
CM_ SG_ 798 LRC_Sector_Dist "GW报文转发 ";
CM_ SG_ 798 RRM_Sector_Dist "GW报文转发 ";
CM_ SG_ 798 LRM_Sector_Dist "GW报文转发 ";
CM_ SG_ 798 RRF_Sector_Dist "GW报文转发 ";
CM_ SG_ 798 LRF_Sector_Dist "GW报文转发 ";
CM_ SG_ 798 RFF_Sector_Dist "GW报文转发 ";
CM_ SG_ 798 LFF_Sector_Dist "GW报文转发 ";
CM_ BO_ 833 "源端HybridA_PCU_33B,1 ";
CM_ SG_ 833 PCU_PwrTqWhMinVld "ACC 主控则ACC接收，LAS 主控则LAS接收 ";
CM_ SG_ 833 PCU_PwrTqWhMinTotal "ACC 主控则ACC接收，LAS 主控则LAS接收 ";
CM_ SG_ 833 PCU_PwrTqWhMaxVld "ACC 主控则ACC接收，LAS 主控则LAS接收 ";
CM_ SG_ 833 PCU_PwrTqWhMaxTotal "ACC 主控则ACC接收，LAS 主控则LAS接收 ";
CM_ SG_ 833 PCU_AccPedShield "APA配置接收方无BDC ";
CM_ BO_ 866 "源端HybridA_PCU_33B,2 ";
CM_ SG_ 866 PCU_eDTE " ";
CM_ BO_ 930 " ";
CM_ SG_ 930 RFBT_ResetFlag_3A2 "APA配置接收方无BDC ";
CM_ SG_ 930 RFBT_MesssageCounter_3A2 "APA配置接收方无BDC ";
CM_ SG_ 930 RFBT_Authernticator_3A2 "APA配置接收方无BDC ";
CM_ SG_ 930 GW_Smartphone_APAmoduleEnable "APA配置接收方无BDC ";
CM_ SG_ 930 GW_RFBT_Verticalforward "GW报文转发 ";
CM_ SG_ 930 GW_RFBT_Verticalbackward "GW报文转发 ";
CM_ SG_ 930 GW_RFBT_SlotUserSelected "(GW加解密发送) ";
CM_ SG_ 930 GW_RFBT_RPASwitch "(GW加解密发送) ";
CM_ SG_ 930 GW_RFBT_APAPOCModeSelect "系统判断车位类型，(GW加解密发送) ";
CM_ SG_ 930 GW_RFBT_APAManeuverSuspend "手机APP“开始泊车“按键按下，APA接收到该信号为0x1后，则控制车辆泊车暂停(GW加解密发送) ";
CM_ SG_ 930 GW_RFBT_APAManeuverStart "手机APP“开始泊车“按键按下，APA接收到该信号为0x1后，则控制车辆进行泊车(GW加解密发送) ";
CM_ SG_ 930 GW_RFBT_APAManeuverCancel "手机APP“泊车取消“按键按下，APA接收到该信号为0x1后，则控制泊车系统退出，(GW加解密发送) ";
CM_ BO_ 951 " ";
CM_ SG_ 951 AVM_RightCameraSts "GW报文转发
有APA5.0的车型从ADASCAN转发 ";
CM_ SG_ 951 AVM_LeftCameraSts "GW报文转发
有APA5.0的车型从ADASCAN转发 ";
CM_ SG_ 951 AVM_RearCameraSts "GW报文转发
有APA5.0的车型从ADASCAN转发 ";
CM_ SG_ 951 AVM_FrontCameraSts "GW报文转发
有APA5.0的车型从ADASCAN转发 ";
CM_ BO_ 982 " ";
CM_ SG_ 982 SLCM_RRWindowStatus "纹波防夹 ";
CM_ SG_ 982 SLCM_PassengerWindowStatus "纹波防夹 ";
CM_ BO_ 984 " ";
CM_ SG_ 984 SLCM_RLWindowStatus "纹波防夹 ";
CM_ SG_ 984 SLCM_DriverWindowStatus "纹波防夹 ";
CM_ BO_ 1006 " ";
CM_ SG_ 1006 RFBT_BLEConnectSts "APA配置接收方无BDC ";
CM_ BO_ 1295 " ";
CM_ SG_ 1295 APA_Coordinate_Angle "(GW加解密发送) ";
CM_ SG_ 1295 APA_Coordinate_Y "(GW加解密发送) ";
CM_ SG_ 1295 APA_Coordinate_X "(GW加解密发送) ";
CM_ BO_ 723 " ";
CM_ SG_ 723 ACC_AEBTargetLatRelSpeed_for_SRS "向左为正，向右为 ";
CM_ SG_ 723 ACC_AEBTargetLatRange_for_SRS "向左为正，向右为 ";
CM_ SG_ 723 ACC_CRCCheckr_282 " ";
CM_ SG_ 723 ACC_RollingCounter_282 " ";
CM_ SG_ 723 ACC_AEBTargetProb_for_SRS " ";
CM_ SG_ 723 ACC_AEBTargetType_for_SRS " ";
CM_ SG_ 723 ACC_AEBTargetTTC_for_SRS "碰撞时刻为0 ";
CM_ SG_ 723 ACC_AEBTargetRelSpeed_for_SRS "前方目标比本车快为正，前方目标比本车慢为负 ";
CM_ SG_ 723 ACC_AEBTargetLngRange_for_SRS "负数代表向后，正数代表向前，原点为前雷达波束发射 ";
CM_ SG_ 723 ACC_AEBActive_for_SRS " ";
CM_ SG_ 723 ACC_AEBStatus_for_SRS " ";
CM_ BO_ 713 " ";
CM_ SG_ 713 HU_Ylevel "513(周期)和514(事件)，当前多数项目使用514(事件)报文。 ";
CM_ SG_ 713 HU_Xlevel "513(周期)和514(事件)，当前多数项目使用514(事件)报文。 ";
CM_ BO_ 881 " ";
CM_ BO_ 796 "源端HybridA_PCU/PDCU_3FC.6 ";
CM_ SG_ 796 PCU_VcuRdySts "APA配置接收方无BDC ";
CM_ BO_ 266 " ";
CM_ SG_ 266 EPB_ClampForce_Secondary "用于驻车冗余 ";
CM_ SG_ 266 EPB_EAR_Available " ";
CM_ SG_ 266 EPB_RollingCounter_10A " ";
CM_ SG_ 266 EPB_CRCCheck_10A " ";
CM_ SG_ 266 EPB_Status "APA配置接收方无BDC ";
CM_ SG_ 266 EPB_FailStatus "APA配置接收方无BDC ";
CM_ SG_ 266 EPB_APArequest_Available "APA配置接收方无BDC ";
CM_ BO_ 849 " ";
CM_ SG_ 849 FW_Brightness " ";
CM_ BO_ 380 " ";
CM_ BO_ 378 " ";
CM_ SG_ 378 ESP_VehicleSpeedValid "TCU接收为DCT专用 ";
CM_ SG_ 378 ESP_VehicleSpeed "TCU接收为DCT专用 ";
CM_ SG_ 378 ESP_RollingCounter_187 "AT/DCT ";
CM_ SG_ 378 ESP_pMcVirtual_Q " ";
CM_ SG_ 378 ESP_pMcVirtual " ";
CM_ SG_ 378 ESP_MbRegenTarWhlRearQlfr " ";
CM_ SG_ 378 ESP_MbRegenTarWhlRear " ";
CM_ SG_ 378 ESP_MbRegenTarWhlFrontQlfr " ";
CM_ SG_ 378 ESP_MbRegenTarWhlFront " ";
CM_ SG_ 378 ESP_ESPActiveStatus "TCU接收为DCT专用 ";
CM_ SG_ 378 ESP_EngTorqIncRearActive " ";
CM_ SG_ 378 ESP_CRCCheck_187 "AT/DCT ";
CM_ BO_ 670 " ";
CM_ SG_ 670 LCDAL_RCWVideoEnableStatus "INFO_GW_2AE
B_GW_2AE ";
CM_ SG_ 670 ADS_FRC_FCTAEnable " ";
CM_ SG_ 670 LCDAR_RollingCounter_29E "rolling counter ";
CM_ SG_ 670 ADS_FRC_SystemStatus " ";
CM_ SG_ 670 ADS_FLC_SystemStatus " ";
CM_ SG_ 670 ADS_FRC_FCTBActive " ";
CM_ SG_ 670 ADS_FRC_FCTBTargetDeceleration " ";
CM_ SG_ 670 ADS_FRC_FCTBEnable " ";
CM_ BO_ 685 " ";
CM_ SG_ 685 LCDAL_CRCCheck_2AD " ";
CM_ SG_ 685 LCDAL_RollingCounter_2AD "rolling counter ";
CM_ SG_ 685 LCDAL_CRCCheck_300 " ";
CM_ SG_ 685 LCDAL_RollingCounter_300 "rolling counter ";
CM_ SG_ 685 LCDAL_CRCCheck_2F7 " ";
CM_ SG_ 685 LCDAL_RollingCounter_2F7 "rolling counter ";
CM_ SG_ 685 LCDAL_CRCCheck_2EF " ";
CM_ SG_ 685 LCDAL_RollingCounter_2EF "rolling counter ";
CM_ SG_ 685 LCDAL_CRCCheck_2AE " ";
CM_ SG_ 685 LCDAL_RollingCounter_2AE "rolling counter ";
CM_ SG_ 685 LCDAL_SEAStatus " ";
CM_ SG_ 685 LCDAL_SEAAlert " ";
CM_ SG_ 685 LCDAL_SEAEnableStatus " ";
CM_ SG_ 685 LCDAL_RCWStatus " ";
CM_ SG_ 685 LCDAL_RCWAlert " ";
CM_ SG_ 685 LCDAL_RCWEnableStatus " ";
CM_ SG_ 685 LCDAL_SystemStatus " ";
CM_ BO_ 879 " ";
CM_ SG_ 879 ADS_NDAStatus " ";
CM_ SG_ 879 ADS_NDATextInfo " ";
CM_ SG_ 879 ADS_NIDOutDis " ";
CM_ SG_ 879 RADS_DynamicButton " ";
CM_ SG_ 879 LAS_OverspeedWarningRatioOffset " ";
CM_ SG_ 879 APA_RPA_Notice " ";
CM_ SG_ 879 APA_FunRecomReq " ";
CM_ SG_ 879 ADS_RoadLngRange " ";
CM_ SG_ 879 ADS_PathShowLngRange " ";
CM_ SG_ 879 ADS_RoadMergeLatRange " ";
CM_ SG_ 879 ADS_PathShow_C3 "与ACC_LaneEquationC3定义一致 ";
CM_ SG_ 879 ADS_PathShow_C2 "与ACC_LaneEquationC2定义一致 ";
CM_ SG_ 879 ADS_PathShow_C1 "与ACC_LaneEquationC1定义一致 ";
CM_ BO_ 1535 " ";
CM_ SG_ 1535 BCM_RemoteReadyReq " ";
CM_ BO_ 1785 " ";
CM_ SG_ 1785 ADS_DTC2_Status "DTC上传 ";
CM_ SG_ 1785 ADS_DTC2_LowByte "DTC上传 ";
CM_ SG_ 1785 ADS_DTC2_MiddByte "DTC上传 ";
CM_ SG_ 1785 ADS_DTC2_HighByte "DTC上传 ";
CM_ SG_ 1785 ADS_DTC1_Status "DTC上传 ";
CM_ SG_ 1785 ADS_DTC1_LowByte "DTC上传 ";
CM_ SG_ 1785 ADS_DTC1_MiddByte "DTC上传 ";
CM_ SG_ 1785 ADS_DTC1_HighByte "DTC上传 ";
CM_ BO_ 349 "信号路由（变周期） ";
CM_ SG_ 349 ESP_YawRate "右正左负（举例理解=水平路面向
右转弯时，发正值。反之发负值） ";
CM_ SG_ 349 ESP_LongAccel "举例理解=水平路面直线加速
时，发正值。反之发负值。 ";
CM_ SG_ 349 ESP_LatAccel "右正左负（举例理解=水平路面向
右转弯时，发正值。反之发负值） ";
CM_ BO_ 271 "源端CHS_IBCU_1CB,0
信号路由（变周期） ";
BA_DEF_ SG_  "GenSigSendType" ENUM  "Cyclic","OnWrite","OnWriteWithRepetition","OnChange","OnChangeWithRepetition","IfActive","IfActiveWithRepetition","NoSigSendType","NotUsed","NotUsed","NotUsed","NotUsed","NotUsed";
BA_DEF_ SG_  "GenSigCycleTime" INT 0 0;
BA_DEF_ SG_  "GenSigInvalidValue" STRING ;
BA_DEF_ SG_  "GenSigStartValue" INT 0 0;
BA_DEF_ BO_  "VFrameFormat" ENUM  "StandardCAN","ExtendedCAN","reserved","reserved","reserved","reserved","reserved","reserved","reserved","reserved","reserved","reserved","reserved","reserved","StandardCAN_FD","ExtendedCAN_FD";
BA_DEF_ BO_  "CANFD_BRS" ENUM  "0","1";
BA_DEF_ BO_  "GenMsgCycleTime" INT 0 65535;
BA_DEF_ BO_  "GenMsgILSupport" ENUM  "No","Yes";
BA_DEF_ BO_  "GenMsgSendType" ENUM  "Cyclic","Event","NotUsed","NotUsed","NotUsed","Cyclic","NotUsed","IfActive","NoMsgSendType","NotUsed";
BA_DEF_ SG_  "SystemSignalLongSymbol" STRING ;
BA_DEF_DEF_  "GenSigSendType" "Cyclic";
BA_DEF_DEF_  "GenSigCycleTime" 0;
BA_DEF_DEF_  "GenSigInvalidValue" "/";
BA_DEF_DEF_  "GenSigStartValue" 0;
BA_DEF_DEF_  "VFrameFormat" "StandardCAN";
BA_DEF_DEF_  "CANFD_BRS" "1";
BA_DEF_DEF_  "GenMsgCycleTime" 0;
BA_DEF_DEF_  "GenMsgILSupport" "Yes";
BA_DEF_DEF_  "GenMsgSendType" "NoMsgSendType";
BA_DEF_DEF_  "SystemSignalLongSymbol" "";
BA_ "GenMsgCycleTime" BO_ 947 100;
BA_ "GenMsgSendType" BO_ 947 0;
BA_ "VFrameFormat" BO_ 947 14;
BA_ "GenMsgCycleTime" BO_ 957 100;
BA_ "GenMsgSendType" BO_ 957 0;
BA_ "VFrameFormat" BO_ 957 14;
BA_ "GenMsgCycleTime" BO_ 964 100;
BA_ "GenMsgSendType" BO_ 964 0;
BA_ "VFrameFormat" BO_ 964 14;
BA_ "GenMsgCycleTime" BO_ 1021 100;
BA_ "GenMsgSendType" BO_ 1021 0;
BA_ "VFrameFormat" BO_ 1021 14;
BA_ "GenMsgCycleTime" BO_ 1023 100;
BA_ "GenMsgSendType" BO_ 1023 0;
BA_ "VFrameFormat" BO_ 1023 14;
BA_ "GenMsgCycleTime" BO_ 1683 500;
BA_ "GenMsgSendType" BO_ 1683 0;
BA_ "VFrameFormat" BO_ 1683 14;
BA_ "GenMsgCycleTime" BO_ 652 40;
BA_ "GenMsgSendType" BO_ 652 0;
BA_ "VFrameFormat" BO_ 652 14;
BA_ "GenMsgSendType" BO_ 372 1;
BA_ "VFrameFormat" BO_ 372 14;
BA_ "GenMsgCycleTime" BO_ 431 10;
BA_ "GenMsgSendType" BO_ 431 0;
BA_ "VFrameFormat" BO_ 431 14;
BA_ "GenMsgCycleTime" BO_ 800 100;
BA_ "GenMsgSendType" BO_ 800 0;
BA_ "VFrameFormat" BO_ 800 14;
BA_ "GenMsgCycleTime" BO_ 922 100;
BA_ "GenMsgSendType" BO_ 922 0;
BA_ "VFrameFormat" BO_ 922 14;
BA_ "GenMsgCycleTime" BO_ 906 40;
BA_ "GenMsgSendType" BO_ 906 0;
BA_ "VFrameFormat" BO_ 906 14;
BA_ "GenMsgCycleTime" BO_ 583 20;
BA_ "GenMsgSendType" BO_ 583 0;
BA_ "VFrameFormat" BO_ 583 14;
BA_ "GenMsgCycleTime" BO_ 610 40;
BA_ "GenMsgSendType" BO_ 610 0;
BA_ "VFrameFormat" BO_ 610 14;
BA_ "GenMsgCycleTime" BO_ 917 100;
BA_ "GenMsgSendType" BO_ 917 0;
BA_ "VFrameFormat" BO_ 917 14;
BA_ "GenMsgSendType" BO_ 1344 1;
BA_ "VFrameFormat" BO_ 1344 14;
BA_ "GenMsgSendType" BO_ 1360 1;
BA_ "VFrameFormat" BO_ 1360 14;
BA_ "GenMsgSendType" BO_ 1364 1;
BA_ "VFrameFormat" BO_ 1364 14;
BA_ "GenMsgCycleTime" BO_ 1554 100;
BA_ "GenMsgSendType" BO_ 1554 0;
BA_ "VFrameFormat" BO_ 1554 14;
BA_ "GenMsgCycleTime" BO_ 394 10;
BA_ "GenMsgSendType" BO_ 394 0;
BA_ "VFrameFormat" BO_ 394 14;
BA_ "GenMsgCycleTime" BO_ 586 20;
BA_ "GenMsgSendType" BO_ 586 0;
BA_ "VFrameFormat" BO_ 586 14;
BA_ "GenMsgSendType" BO_ 604 1;
BA_ "VFrameFormat" BO_ 604 14;
BA_ "GenMsgCycleTime" BO_ 710 40;
BA_ "GenMsgSendType" BO_ 710 0;
BA_ "VFrameFormat" BO_ 710 14;
BA_ "GenMsgCycleTime" BO_ 798 100;
BA_ "GenMsgSendType" BO_ 798 0;
BA_ "VFrameFormat" BO_ 798 14;
BA_ "GenMsgCycleTime" BO_ 833 100;
BA_ "GenMsgSendType" BO_ 833 0;
BA_ "VFrameFormat" BO_ 833 14;
BA_ "GenMsgCycleTime" BO_ 866 100;
BA_ "GenMsgSendType" BO_ 866 0;
BA_ "VFrameFormat" BO_ 866 14;
BA_ "GenMsgCycleTime" BO_ 930 100;
BA_ "GenMsgSendType" BO_ 930 0;
BA_ "VFrameFormat" BO_ 930 14;
BA_ "GenMsgCycleTime" BO_ 951 100;
BA_ "GenMsgSendType" BO_ 951 0;
BA_ "VFrameFormat" BO_ 951 14;
BA_ "GenMsgCycleTime" BO_ 982 100;
BA_ "GenMsgSendType" BO_ 982 0;
BA_ "VFrameFormat" BO_ 982 14;
BA_ "GenMsgCycleTime" BO_ 984 100;
BA_ "GenMsgSendType" BO_ 984 0;
BA_ "VFrameFormat" BO_ 984 14;
BA_ "GenMsgCycleTime" BO_ 1006 100;
BA_ "GenMsgSendType" BO_ 1006 0;
BA_ "VFrameFormat" BO_ 1006 14;
BA_ "GenMsgCycleTime" BO_ 1295 200;
BA_ "GenMsgSendType" BO_ 1295 0;
BA_ "VFrameFormat" BO_ 1295 14;
BA_ "GenMsgCycleTime" BO_ 723 40;
BA_ "GenMsgSendType" BO_ 723 0;
BA_ "VFrameFormat" BO_ 723 14;
BA_ "GenMsgCycleTime" BO_ 713 40;
BA_ "GenMsgSendType" BO_ 713 0;
BA_ "VFrameFormat" BO_ 713 14;
BA_ "GenMsgCycleTime" BO_ 881 100;
BA_ "GenMsgSendType" BO_ 881 0;
BA_ "VFrameFormat" BO_ 881 14;
BA_ "GenMsgCycleTime" BO_ 796 100;
BA_ "GenMsgSendType" BO_ 796 0;
BA_ "VFrameFormat" BO_ 796 14;
BA_ "GenMsgCycleTime" BO_ 266 10;
BA_ "GenMsgSendType" BO_ 266 0;
BA_ "VFrameFormat" BO_ 266 14;
BA_ "GenMsgCycleTime" BO_ 81 500;
BA_ "GenMsgSendType" BO_ 81 0;
BA_ "VFrameFormat" BO_ 81 14;
BA_ "GenMsgCycleTime" BO_ 849 100;
BA_ "GenMsgSendType" BO_ 849 0;
BA_ "VFrameFormat" BO_ 849 14;
BA_ "GenMsgCycleTime" BO_ 380 10;
BA_ "GenMsgSendType" BO_ 380 0;
BA_ "VFrameFormat" BO_ 380 14;
BA_ "GenMsgCycleTime" BO_ 378 10;
BA_ "GenMsgSendType" BO_ 378 0;
BA_ "VFrameFormat" BO_ 378 14;
BA_ "GenMsgCycleTime" BO_ 670 50;
BA_ "GenMsgSendType" BO_ 670 0;
BA_ "VFrameFormat" BO_ 670 14;
BA_ "GenMsgCycleTime" BO_ 685 50;
BA_ "GenMsgSendType" BO_ 685 0;
BA_ "VFrameFormat" BO_ 685 14;
BA_ "GenMsgCycleTime" BO_ 879 100;
BA_ "GenMsgSendType" BO_ 879 0;
BA_ "VFrameFormat" BO_ 879 14;
BA_ "GenMsgCycleTime" BO_ 1535 100;
BA_ "GenMsgSendType" BO_ 1535 0;
BA_ "VFrameFormat" BO_ 1535 14;
BA_ "GenMsgCycleTime" BO_ 1785 500;
BA_ "GenMsgSendType" BO_ 1785 0;
BA_ "VFrameFormat" BO_ 1785 14;
BA_ "GenMsgCycleTime" BO_ 349 20;
BA_ "GenMsgSendType" BO_ 349 0;
BA_ "VFrameFormat" BO_ 349 14;
BA_ "GenMsgCycleTime" BO_ 271 20;
BA_ "GenMsgSendType" BO_ 271 0;
BA_ "VFrameFormat" BO_ 271 14;
BA_ "GenSigCycleTime" SG_ 947 BCM_RightRearDoorHandleStatus 100;
BA_ "GenSigCycleTime" SG_ 947 BCM_PassengeDoorHandleStatus 100;
BA_ "GenSigCycleTime" SG_ 947 LCM_ReverseLightSts 100;
BA_ "GenSigInvalidValue" SG_ 947 LCM_ReverseLightSts "3";
BA_ "GenSigCycleTime" SG_ 947 BCM_ReverseLampError 100;
BA_ "GenSigCycleTime" SG_ 947 BCM_CHMLampError 100;
BA_ "GenSigCycleTime" SG_ 947 BCM_BrakeLampError 100;
BA_ "GenSigCycleTime" SG_ 947 BCM_RightRearFoglampError 100;
BA_ "GenSigCycleTime" SG_ 947 BCM_LeftRearFoglampError 100;
BA_ "GenSigCycleTime" SG_ 947 BCM_RearPositionLampError 100;
BA_ "GenSigCycleTime" SG_ 947 BCM_RearFoglampStatus 100;
BA_ "GenSigInvalidValue" SG_ 947 BCM_RearFoglampStatus "3";
BA_ "GenSigCycleTime" SG_ 957 HU_Llong_Tunnel_Len 100;
BA_ "GenSigInvalidValue" SG_ 957 HU_Llong_Tunnel_Len "2047";
BA_ "GenSigStartValue" SG_ 957 HU_Llong_Tunnel_Len 2047;
BA_ "GenSigCycleTime" SG_ 957 HU_Long_Ramp_Side 100;
BA_ "GenSigInvalidValue" SG_ 957 HU_Long_Ramp_Side "3";
BA_ "GenSigCycleTime" SG_ 957 HU_Long_Ramp_Dis 100;
BA_ "GenSigInvalidValue" SG_ 957 HU_Long_Ramp_Dis "2047";
BA_ "GenSigStartValue" SG_ 957 HU_Long_Ramp_Dis 2047;
BA_ "GenSigCycleTime" SG_ 957 HU_ParallelRoadSide 100;
BA_ "GenSigInvalidValue" SG_ 957 HU_ParallelRoadSide "3";
BA_ "GenSigCycleTime" SG_ 957 HU_ParallelRoadInfo 100;
BA_ "GenSigInvalidValue" SG_ 957 HU_ParallelRoadInfo "3";
BA_ "GenSigCycleTime" SG_ 957 HU_EnterParallelRoadInfo 100;
BA_ "GenSigCycleTime" SG_ 957 HU_ParallelRoadDistance 100;
BA_ "GenSigStartValue" SG_ 957 HU_ParallelRoadDistance 255;
BA_ "GenSigCycleTime" SG_ 957 HU_AsistantSysteSwitch 100;
BA_ "GenSigInvalidValue" SG_ 957 HU_AsistantSysteSwitch "0";
BA_ "GenSigCycleTime" SG_ 957 HU_ALCModeSelection 100;
BA_ "GenSigCycleTime" SG_ 957 HU_SlotUserSelected 100;
BA_ "GenSigInvalidValue" SG_ 957 HU_SlotUserSelected "7";
BA_ "GenSigCycleTime" SG_ 957 HU_SentryModeSt 100;
BA_ "GenSigCycleTime" SG_ 957 HU_AutoHeadLiSet 100;
BA_ "GenSigCycleTime" SG_ 957 HU_RADSSwitch 100;
BA_ "GenSigInvalidValue" SG_ 957 HU_RADSSwitch "0";
BA_ "GenSigCycleTime" SG_ 957 HU_CRCCheck_394 100;
BA_ "GenSigCycleTime" SG_ 957 HU_RollingCounter_394 100;
BA_ "GenSigCycleTime" SG_ 957 HU_LaneChangeReq 100;
BA_ "GenSigCycleTime" SG_ 957 HU_UDLCEnable 100;
BA_ "GenSigInvalidValue" SG_ 957 HU_UDLCEnable "0";
BA_ "GenSigCycleTime" SG_ 957 HU_ESSEnable 100;
BA_ "GenSigInvalidValue" SG_ 957 HU_ESSEnable "0";
BA_ "GenSigCycleTime" SG_ 957 HU_ELKEnable 100;
BA_ "GenSigInvalidValue" SG_ 957 HU_ELKEnable "0";
BA_ "GenSigCycleTime" SG_ 957 HU_TLAEnable 100;
BA_ "GenSigInvalidValue" SG_ 957 HU_TLAEnable "0";
BA_ "GenSigCycleTime" SG_ 957 HU_LAEBEnable 100;
BA_ "GenSigCycleTime" SG_ 957 HU_APAModeSelect 100;
BA_ "GenSigInvalidValue" SG_ 957 HU_APAModeSelect "3";
BA_ "GenSigStartValue" SG_ 957 HU_APAModeSelect 7;
BA_ "GenSigCycleTime" SG_ 957 HU_NaviDistance 100;
BA_ "GenSigInvalidValue" SG_ 957 HU_NaviDistance "131071";
BA_ "GenSigCycleTime" SG_ 964 HU_Indication_BusLane_Dis 100;
BA_ "GenSigInvalidValue" SG_ 964 HU_Indication_BusLane_Dis "255";
BA_ "GenSigStartValue" SG_ 964 HU_Indication_BusLane_Dis 255;
BA_ "GenSigCycleTime" SG_ 964 HU_Indication_PedestrianCro_Dis 100;
BA_ "GenSigInvalidValue" SG_ 964 HU_Indication_PedestrianCro_Dis "255";
BA_ "GenSigStartValue" SG_ 964 HU_Indication_PedestrianCro_Dis 255;
BA_ "GenSigCycleTime" SG_ 964 HU_Indication_MainRoadPri_Dis 100;
BA_ "GenSigInvalidValue" SG_ 964 HU_Indication_MainRoadPri_Dis "255";
BA_ "GenSigStartValue" SG_ 964 HU_Indication_MainRoadPri_Dis 255;
BA_ "GenSigCycleTime" SG_ 964 HU_Indication_Walk_Dis 100;
BA_ "GenSigInvalidValue" SG_ 964 HU_Indication_Walk_Dis "255";
BA_ "GenSigStartValue" SG_ 964 HU_Indication_Walk_Dis 255;
BA_ "GenSigCycleTime" SG_ 964 HU_Indication_OneWay_Dis 100;
BA_ "GenSigInvalidValue" SG_ 964 HU_Indication_OneWay_Dis "255";
BA_ "GenSigStartValue" SG_ 964 HU_Indication_OneWay_Dis 255;
BA_ "GenSigCycleTime" SG_ 964 HU_Prohibitory_GiveWayOncom_Dis 100;
BA_ "GenSigInvalidValue" SG_ 964 HU_Prohibitory_GiveWayOncom_Dis "255";
BA_ "GenSigStartValue" SG_ 964 HU_Prohibitory_GiveWayOncom_Dis 255;
BA_ "GenSigCycleTime" SG_ 964 HU_Prohibitory_Honking_Dis 100;
BA_ "GenSigInvalidValue" SG_ 964 HU_Prohibitory_Honking_Dis "255";
BA_ "GenSigStartValue" SG_ 964 HU_Prohibitory_Honking_Dis 255;
BA_ "GenSigCycleTime" SG_ 964 HU_Prohibitory_Enter_Dis 100;
BA_ "GenSigInvalidValue" SG_ 964 HU_Prohibitory_Enter_Dis "255";
BA_ "GenSigStartValue" SG_ 964 HU_Prohibitory_Enter_Dis 255;
BA_ "GenSigCycleTime" SG_ 964 HU_Prohibitory_StopToGiveWay_Dis 100;
BA_ "GenSigInvalidValue" SG_ 964 HU_Prohibitory_StopToGiveWay_Dis "255";
BA_ "GenSigStartValue" SG_ 964 HU_Prohibitory_StopToGiveWay_Dis 255;
BA_ "GenSigCycleTime" SG_ 964 HU_Indication_BusLane 100;
BA_ "GenSigInvalidValue" SG_ 964 HU_Indication_BusLane "1";
BA_ "GenSigStartValue" SG_ 964 HU_Indication_BusLane 1;
BA_ "GenSigCycleTime" SG_ 964 HU_Indication_PedestrianCrossing 100;
BA_ "GenSigInvalidValue" SG_ 964 HU_Indication_PedestrianCrossing "1";
BA_ "GenSigStartValue" SG_ 964 HU_Indication_PedestrianCrossing 1;
BA_ "GenSigCycleTime" SG_ 964 HU_Indication_MainRoadPriority 100;
BA_ "GenSigInvalidValue" SG_ 964 HU_Indication_MainRoadPriority "1";
BA_ "GenSigStartValue" SG_ 964 HU_Indication_MainRoadPriority 1;
BA_ "GenSigCycleTime" SG_ 964 HU_Indication_Walk 100;
BA_ "GenSigInvalidValue" SG_ 964 HU_Indication_Walk "1";
BA_ "GenSigStartValue" SG_ 964 HU_Indication_Walk 1;
BA_ "GenSigCycleTime" SG_ 964 HU_Indication_OneWay 100;
BA_ "GenSigInvalidValue" SG_ 964 HU_Indication_OneWay "1";
BA_ "GenSigStartValue" SG_ 964 HU_Indication_OneWay 1;
BA_ "GenSigCycleTime" SG_ 964 HU_Prohibitory_GiveWayToOncoming 100;
BA_ "GenSigInvalidValue" SG_ 964 HU_Prohibitory_GiveWayToOncoming "1";
BA_ "GenSigStartValue" SG_ 964 HU_Prohibitory_GiveWayToOncoming 1;
BA_ "GenSigCycleTime" SG_ 964 HU_Prohibitory_Honking 100;
BA_ "GenSigInvalidValue" SG_ 964 HU_Prohibitory_Honking "1";
BA_ "GenSigStartValue" SG_ 964 HU_Prohibitory_Honking 1;
BA_ "GenSigCycleTime" SG_ 964 HU_Prohibitory_Enter 100;
BA_ "GenSigInvalidValue" SG_ 964 HU_Prohibitory_Enter "1";
BA_ "GenSigStartValue" SG_ 964 HU_Prohibitory_Enter 1;
BA_ "GenSigCycleTime" SG_ 964 HU_Prohibitory_StopToGiveWay 100;
BA_ "GenSigInvalidValue" SG_ 964 HU_Prohibitory_StopToGiveWay "1";
BA_ "GenSigStartValue" SG_ 964 HU_Prohibitory_StopToGiveWay 1;
BA_ "GenSigCycleTime" SG_ 964 HU_Prohibitory_SpeedLimit 100;
BA_ "GenSigInvalidValue" SG_ 964 HU_Prohibitory_SpeedLimit "1";
BA_ "GenSigStartValue" SG_ 964 HU_Prohibitory_SpeedLimit 1;
BA_ "GenSigCycleTime" SG_ 964 HU_Prohibitory_VehParkLongTime 100;
BA_ "GenSigInvalidValue" SG_ 964 HU_Prohibitory_VehParkLongTime "1";
BA_ "GenSigStartValue" SG_ 964 HU_Prohibitory_VehParkLongTime 1;
BA_ "GenSigCycleTime" SG_ 964 HU_Prohibitory_VehicleParking 100;
BA_ "GenSigInvalidValue" SG_ 964 HU_Prohibitory_VehicleParking "1";
BA_ "GenSigStartValue" SG_ 964 HU_Prohibitory_VehicleParking 1;
BA_ "GenSigCycleTime" SG_ 964 HU_Prohibitory_Overtake 100;
BA_ "GenSigInvalidValue" SG_ 964 HU_Prohibitory_Overtake "1";
BA_ "GenSigStartValue" SG_ 964 HU_Prohibitory_Overtake 1;
BA_ "GenSigCycleTime" SG_ 964 HU_Prohibitory_Uturn 100;
BA_ "GenSigInvalidValue" SG_ 964 HU_Prohibitory_Uturn "1";
BA_ "GenSigStartValue" SG_ 964 HU_Prohibitory_Uturn 1;
BA_ "GenSigCycleTime" SG_ 964 HU_Prohibitory_Straight 100;
BA_ "GenSigInvalidValue" SG_ 964 HU_Prohibitory_Straight "1";
BA_ "GenSigStartValue" SG_ 964 HU_Prohibitory_Straight 1;
BA_ "GenSigCycleTime" SG_ 964 HU_Prohibitory_TurnRight 100;
BA_ "GenSigInvalidValue" SG_ 964 HU_Prohibitory_TurnRight "1";
BA_ "GenSigStartValue" SG_ 964 HU_Prohibitory_TurnRight 1;
BA_ "GenSigCycleTime" SG_ 964 HU_Prohibitory_MotorVehicles 100;
BA_ "GenSigInvalidValue" SG_ 964 HU_Prohibitory_MotorVehicles "1";
BA_ "GenSigStartValue" SG_ 964 HU_Prohibitory_MotorVehicles 1;
BA_ "GenSigCycleTime" SG_ 964 HU_Prohibitory_DriveInto 100;
BA_ "GenSigInvalidValue" SG_ 964 HU_Prohibitory_DriveInto "1";
BA_ "GenSigStartValue" SG_ 964 HU_Prohibitory_DriveInto 1;
BA_ "GenSigCycleTime" SG_ 964 HU_Warning_RoadWorks 100;
BA_ "GenSigInvalidValue" SG_ 964 HU_Warning_RoadWorks "1";
BA_ "GenSigStartValue" SG_ 964 HU_Warning_RoadWorks 1;
BA_ "GenSigCycleTime" SG_ 964 HU_Warning_Slow 100;
BA_ "GenSigInvalidValue" SG_ 964 HU_Warning_Slow "1";
BA_ "GenSigStartValue" SG_ 964 HU_Warning_Slow 1;
BA_ "GenSigCycleTime" SG_ 964 HU_Warning_Tunnel 100;
BA_ "GenSigInvalidValue" SG_ 964 HU_Warning_Tunnel "1";
BA_ "GenSigStartValue" SG_ 964 HU_Warning_Tunnel 1;
BA_ "GenSigCycleTime" SG_ 964 HU_Warning_Slip 100;
BA_ "GenSigInvalidValue" SG_ 964 HU_Warning_Slip "1";
BA_ "GenSigStartValue" SG_ 964 HU_Warning_Slip 1;
BA_ "GenSigCycleTime" SG_ 964 HU_Warning_Pedestrian 100;
BA_ "GenSigInvalidValue" SG_ 964 HU_Warning_Pedestrian "1";
BA_ "GenSigStartValue" SG_ 964 HU_Warning_Pedestrian 1;
BA_ "GenSigCycleTime" SG_ 964 HU_Warning_ContinuousDetours 100;
BA_ "GenSigInvalidValue" SG_ 964 HU_Warning_ContinuousDetours "1";
BA_ "GenSigStartValue" SG_ 964 HU_Warning_ContinuousDetours 1;
BA_ "GenSigCycleTime" SG_ 964 HU_Warning_ReverseCurve 100;
BA_ "GenSigInvalidValue" SG_ 964 HU_Warning_ReverseCurve "1";
BA_ "GenSigStartValue" SG_ 964 HU_Warning_ReverseCurve 1;
BA_ "GenSigCycleTime" SG_ 964 HU_BSDLCAMode 100;
BA_ "GenSigCycleTime" SG_ 964 HU_CrossingAngle4 100;
BA_ "GenSigInvalidValue" SG_ 964 HU_CrossingAngle4 "254";
BA_ "GenSigStartValue" SG_ 964 HU_CrossingAngle4 254;
BA_ "GenSigCycleTime" SG_ 964 HU_CrossingAngle3 100;
BA_ "GenSigInvalidValue" SG_ 964 HU_CrossingAngle3 "254";
BA_ "GenSigStartValue" SG_ 964 HU_CrossingAngle3 254;
BA_ "GenSigCycleTime" SG_ 964 HU_CrossingAngle2 100;
BA_ "GenSigInvalidValue" SG_ 964 HU_CrossingAngle2 "254";
BA_ "GenSigStartValue" SG_ 964 HU_CrossingAngle2 254;
BA_ "GenSigCycleTime" SG_ 964 HU_CrossingAngle1 100;
BA_ "GenSigInvalidValue" SG_ 964 HU_CrossingAngle1 "254";
BA_ "GenSigStartValue" SG_ 964 HU_CrossingAngle1 254;
BA_ "GenSigCycleTime" SG_ 964 HU_EnterRoundaboutInfo 100;
BA_ "GenSigInvalidValue" SG_ 964 HU_EnterRoundaboutInfo "0";
BA_ "GenSigCycleTime" SG_ 964 HU_RoundaboutDistance 100;
BA_ "GenSigInvalidValue" SG_ 964 HU_RoundaboutDistance "63";
BA_ "GenSigStartValue" SG_ 964 HU_RoundaboutDistance 63;
BA_ "GenSigCycleTime" SG_ 964 HU_EnterCrossingInfo 100;
BA_ "GenSigInvalidValue" SG_ 964 HU_EnterCrossingInfo "0";
BA_ "GenSigCycleTime" SG_ 964 HU_CrossingDistance 100;
BA_ "GenSigInvalidValue" SG_ 964 HU_CrossingDistance "63";
BA_ "GenSigStartValue" SG_ 964 HU_CrossingDistance 63;
BA_ "GenSigCycleTime" SG_ 964 HU_CRCCheck_3C4 100;
BA_ "GenSigCycleTime" SG_ 964 HU_RollingCounter_3C4 100;
BA_ "GenSigCycleTime" SG_ 964 HU_MapMatchStatus 100;
BA_ "GenSigInvalidValue" SG_ 964 HU_MapMatchStatus "3";
BA_ "GenSigCycleTime" SG_ 964 HU_MapDataUpdateStatus 100;
BA_ "GenSigInvalidValue" SG_ 964 HU_MapDataUpdateStatus "7";
BA_ "GenSigCycleTime" SG_ 964 HU_SlopeGradient_300m 100;
BA_ "GenSigInvalidValue" SG_ 964 HU_SlopeGradient_300m "1023";
BA_ "GenSigStartValue" SG_ 964 HU_SlopeGradient_300m 1023;
BA_ "GenSigCycleTime" SG_ 964 HU_RoadCurvature_600m 100;
BA_ "GenSigInvalidValue" SG_ 964 HU_RoadCurvature_600m "1023";
BA_ "GenSigStartValue" SG_ 964 HU_RoadCurvature_600m 511;
BA_ "GenSigCycleTime" SG_ 964 HU_RoadCurvature_400m 100;
BA_ "GenSigInvalidValue" SG_ 964 HU_RoadCurvature_400m "1023";
BA_ "GenSigStartValue" SG_ 964 HU_RoadCurvature_400m 511;
BA_ "GenSigCycleTime" SG_ 964 HU_RoadCurvature_300m 100;
BA_ "GenSigInvalidValue" SG_ 964 HU_RoadCurvature_300m "1023";
BA_ "GenSigStartValue" SG_ 964 HU_RoadCurvature_300m 511;
BA_ "GenSigCycleTime" SG_ 964 HU_RoadCurvature_100m 100;
BA_ "GenSigInvalidValue" SG_ 964 HU_RoadCurvature_100m "1023";
BA_ "GenSigStartValue" SG_ 964 HU_RoadCurvature_100m 511;
BA_ "GenSigCycleTime" SG_ 964 HU_RoadCurvature_90m 100;
BA_ "GenSigInvalidValue" SG_ 964 HU_RoadCurvature_90m "1023";
BA_ "GenSigStartValue" SG_ 964 HU_RoadCurvature_90m 511;
BA_ "GenSigCycleTime" SG_ 964 HU_RoadCurvature_80m 100;
BA_ "GenSigInvalidValue" SG_ 964 HU_RoadCurvature_80m "1023";
BA_ "GenSigStartValue" SG_ 964 HU_RoadCurvature_80m 511;
BA_ "GenSigCycleTime" SG_ 964 HU_RoadCurvature_70m 100;
BA_ "GenSigInvalidValue" SG_ 964 HU_RoadCurvature_70m "1023";
BA_ "GenSigStartValue" SG_ 964 HU_RoadCurvature_70m 511;
BA_ "GenSigCycleTime" SG_ 964 HU_RoadCurvature_60m 100;
BA_ "GenSigInvalidValue" SG_ 964 HU_RoadCurvature_60m "1023";
BA_ "GenSigStartValue" SG_ 964 HU_RoadCurvature_60m 511;
BA_ "GenSigCycleTime" SG_ 964 HU_RoadCurvature_50m 100;
BA_ "GenSigInvalidValue" SG_ 964 HU_RoadCurvature_50m "1023";
BA_ "GenSigStartValue" SG_ 964 HU_RoadCurvature_50m 511;
BA_ "GenSigCycleTime" SG_ 964 HU_RoadCurvature_40m 100;
BA_ "GenSigInvalidValue" SG_ 964 HU_RoadCurvature_40m "1023";
BA_ "GenSigStartValue" SG_ 964 HU_RoadCurvature_40m 511;
BA_ "GenSigCycleTime" SG_ 964 HU_RoadCurvature_30m 100;
BA_ "GenSigInvalidValue" SG_ 964 HU_RoadCurvature_30m "1023";
BA_ "GenSigStartValue" SG_ 964 HU_RoadCurvature_30m 511;
BA_ "GenSigCycleTime" SG_ 964 HU_RoadCurvature_20m 100;
BA_ "GenSigInvalidValue" SG_ 964 HU_RoadCurvature_20m "1023";
BA_ "GenSigStartValue" SG_ 964 HU_RoadCurvature_20m 511;
BA_ "GenSigCycleTime" SG_ 964 HU_RoadCurvature_10m 100;
BA_ "GenSigInvalidValue" SG_ 964 HU_RoadCurvature_10m "1023";
BA_ "GenSigStartValue" SG_ 964 HU_RoadCurvature_10m 511;
BA_ "GenSigCycleTime" SG_ 964 HU_Road_TrafficFlow 100;
BA_ "GenSigInvalidValue" SG_ 964 HU_Road_TrafficFlow "7";
BA_ "GenSigCycleTime" SG_ 964 HU_Lane_Changtype 100;
BA_ "GenSigInvalidValue" SG_ 964 HU_Lane_Changtype "3";
BA_ "GenSigStartValue" SG_ 964 HU_Lane_Changtype 3;
BA_ "GenSigCycleTime" SG_ 964 HU_To_NumchangeOfLanes_Dist 100;
BA_ "GenSigInvalidValue" SG_ 964 HU_To_NumchangeOfLanes_Dist "63";
BA_ "GenSigStartValue" SG_ 964 HU_To_NumchangeOfLanes_Dist 63;
BA_ "GenSigCycleTime" SG_ 964 HU_To_Branch_Dis 100;
BA_ "GenSigInvalidValue" SG_ 964 HU_To_Branch_Dis "63";
BA_ "GenSigStartValue" SG_ 964 HU_To_Branch_Dis 63;
BA_ "GenSigCycleTime" SG_ 964 HU_To_TrafficAccident_Dis 100;
BA_ "GenSigInvalidValue" SG_ 964 HU_To_TrafficAccident_Dis "63";
BA_ "GenSigStartValue" SG_ 964 HU_To_TrafficAccident_Dis 63;
BA_ "GenSigCycleTime" SG_ 964 HU_TrafficAccident_Info 100;
BA_ "GenSigInvalidValue" SG_ 964 HU_TrafficAccident_Info "3";
BA_ "GenSigStartValue" SG_ 964 HU_TrafficAccident_Info 3;
BA_ "GenSigCycleTime" SG_ 964 HU_To_Construction_Dis 100;
BA_ "GenSigInvalidValue" SG_ 964 HU_To_Construction_Dis "63";
BA_ "GenSigStartValue" SG_ 964 HU_To_Construction_Dis 63;
BA_ "GenSigCycleTime" SG_ 964 HU_Construction_Info 100;
BA_ "GenSigInvalidValue" SG_ 964 HU_Construction_Info "3";
BA_ "GenSigStartValue" SG_ 964 HU_Construction_Info 3;
BA_ "GenSigCycleTime" SG_ 964 HU_TollDis 100;
BA_ "GenSigInvalidValue" SG_ 964 HU_TollDis "63";
BA_ "GenSigStartValue" SG_ 964 HU_TollDis 63;
BA_ "GenSigCycleTime" SG_ 964 HU_TollInfo 100;
BA_ "GenSigInvalidValue" SG_ 964 HU_TollInfo "3";
BA_ "GenSigStartValue" SG_ 964 HU_TollInfo 3;
BA_ "GenSigCycleTime" SG_ 964 HU_FallingRockDi 100;
BA_ "GenSigInvalidValue" SG_ 964 HU_FallingRockDi "63";
BA_ "GenSigStartValue" SG_ 964 HU_FallingRockDi 63;
BA_ "GenSigCycleTime" SG_ 964 HU_FallingRockInfo 100;
BA_ "GenSigInvalidValue" SG_ 964 HU_FallingRockInfo "3";
BA_ "GenSigStartValue" SG_ 964 HU_FallingRockInfo 3;
BA_ "GenSigCycleTime" SG_ 964 HU_LaneCnt 100;
BA_ "GenSigInvalidValue" SG_ 964 HU_LaneCnt "0";
BA_ "GenSigCycleTime" SG_ 964 HU_ForwardRoadType 100;
BA_ "GenSigInvalidValue" SG_ 964 HU_ForwardRoadType "0";
BA_ "GenSigCycleTime" SG_ 964 HU_RampSide 100;
BA_ "GenSigInvalidValue" SG_ 964 HU_RampSide "0";
BA_ "GenSigCycleTime" SG_ 964 HU_NavGuiganceStatus 100;
BA_ "GenSigInvalidValue" SG_ 964 HU_NavGuiganceStatus "3";
BA_ "GenSigCycleTime" SG_ 964 HU_SlopeDistance 100;
BA_ "GenSigInvalidValue" SG_ 964 HU_SlopeDistance "63";
BA_ "GenSigStartValue" SG_ 964 HU_SlopeDistance 63;
BA_ "GenSigCycleTime" SG_ 964 HU_TunnelLength 100;
BA_ "GenSigInvalidValue" SG_ 964 HU_TunnelLength "63";
BA_ "GenSigStartValue" SG_ 964 HU_TunnelLength 63;
BA_ "GenSigCycleTime" SG_ 964 HU_RoadCurvatureFar 100;
BA_ "GenSigInvalidValue" SG_ 964 HU_RoadCurvatureFar "1023";
BA_ "GenSigStartValue" SG_ 964 HU_RoadCurvatureFar 511;
BA_ "GenSigCycleTime" SG_ 964 HU_TunnelDistance 100;
BA_ "GenSigInvalidValue" SG_ 964 HU_TunnelDistance "63";
BA_ "GenSigStartValue" SG_ 964 HU_TunnelDistance 63;
BA_ "GenSigCycleTime" SG_ 964 HU_RoadCurvature 100;
BA_ "GenSigInvalidValue" SG_ 964 HU_RoadCurvature "1023";
BA_ "GenSigStartValue" SG_ 964 HU_RoadCurvature 511;
BA_ "GenSigCycleTime" SG_ 964 HU_EnterSlopeInfo 100;
BA_ "GenSigInvalidValue" SG_ 964 HU_EnterSlopeInfo "0";
BA_ "GenSigCycleTime" SG_ 964 HU_EnterTunnelInfo 100;
BA_ "GenSigInvalidValue" SG_ 964 HU_EnterTunnelInfo "0";
BA_ "GenSigCycleTime" SG_ 1021 BCM_AutHeadLiSts 100;
BA_ "GenSigCycleTime" SG_ 1021 BCM_FrontWindshieldWarmStatus 100;
BA_ "GenSigInvalidValue" SG_ 1021 BCM_FrontWindshieldWarmStatus "0";
BA_ "GenSigCycleTime" SG_ 1021 BCM_CRCCheck_3FD 100;
BA_ "GenSigCycleTime" SG_ 1021 BCM_RollingCounter_3FD 100;
BA_ "GenSigCycleTime" SG_ 1021 BCM_DriveMode 100;
BA_ "GenSigInvalidValue" SG_ 1021 BCM_DriveMode "15";
BA_ "GenSigCycleTime" SG_ 1021 BCM_PowerManageLevel 100;
BA_ "GenSigInvalidValue" SG_ 1021 BCM_PowerManageLevel "7";
BA_ "GenSigCycleTime" SG_ 1023 BCM_CRCCheck_3FF 100;
BA_ "GenSigCycleTime" SG_ 1023 BCM_RollingCounter_3FF 100;
BA_ "GenSigCycleTime" SG_ 1023 BCM_TurnIndicatorRightError 100;
BA_ "GenSigCycleTime" SG_ 1023 BCM_TurnIndicatorLeftError 100;
BA_ "GenSigCycleTime" SG_ 1023 BCM_RightFrontFoglampError 100;
BA_ "GenSigCycleTime" SG_ 1023 BCM_LeftFrontFoglampError 100;
BA_ "GenSigCycleTime" SG_ 1023 BCM_RightLowBeamError 100;
BA_ "GenSigCycleTime" SG_ 1023 BCM_LeftLowBeamError 100;
BA_ "GenSigCycleTime" SG_ 1023 BCM_HighBeamLampError 100;
BA_ "GenSigCycleTime" SG_ 1023 BCM_AutoHeadlightSts 100;
BA_ "GenSigInvalidValue" SG_ 1023 BCM_AutoHeadlightSts "0";
BA_ "GenSigCycleTime" SG_ 1023 BCM_FrontFoglampStatus 100;
BA_ "GenSigInvalidValue" SG_ 1023 BCM_FrontFoglampStatus "3";
BA_ "GenSigCycleTime" SG_ 1683 ACC_DTC2_Status 500;
BA_ "GenSigCycleTime" SG_ 1683 ACC_DTC2_LowByte 500;
BA_ "GenSigCycleTime" SG_ 1683 ACC_DTC2_MiddByte 500;
BA_ "GenSigCycleTime" SG_ 1683 ACC_DTC2_HighByte 500;
BA_ "GenSigCycleTime" SG_ 1683 ACC_DTC1_Status 500;
BA_ "GenSigCycleTime" SG_ 1683 ACC_DTC1_LowByte 500;
BA_ "GenSigCycleTime" SG_ 1683 ACC_DTC1_MiddByte 500;
BA_ "GenSigCycleTime" SG_ 1683 ACC_DTC1_HighByte 500;
BA_ "GenSigCycleTime" SG_ 652 GW_MFS_APA_switch 40;
BA_ "GenSigInvalidValue" SG_ 652 GW_MFS_APA_switch "3";
BA_ "GenSigCycleTime" SG_ 652 GW_MFS_HODCalibratedStatus 40;
BA_ "GenSigStartValue" SG_ 652 GW_MFS_HODCalibratedStatus 1;
BA_ "GenSigCycleTime" SG_ 652 GW_MFS_HODLinStatus 40;
BA_ "GenSigCycleTime" SG_ 652 GW_MFS_HODAppStatus 40;
BA_ "GenSigCycleTime" SG_ 652 GW_MFS_HODSenserStatus 40;
BA_ "GenSigCycleTime" SG_ 652 GW_MFS_HODSystemStatus 40;
BA_ "GenSigCycleTime" SG_ 652 GW_MFS_handsoffAbilityDetect 40;
BA_ "GenSigCycleTime" SG_ 652 GW_MFS_handsoffDetectResult 40;
BA_ "GenSigCycleTime" SG_ 652 GW_MFS_CRCCheck_28C 40;
BA_ "GenSigCycleTime" SG_ 652 GW_MFS_RollingCounter_28C 40;
BA_ "GenSigCycleTime" SG_ 652 GW_MFS_DiagInfoSW_28C 40;
BA_ "GenSigInvalidValue" SG_ 652 GW_MFS_DiagInfoSW_28C "7";
BA_ "GenSigCycleTime" SG_ 652 GW_MFS_IACCenable_switch_signal 40;
BA_ "GenSigInvalidValue" SG_ 652 GW_MFS_IACCenable_switch_signal "3";
BA_ "GenSigCycleTime" SG_ 652 GW_MFS_LIM_switch_signal 40;
BA_ "GenSigInvalidValue" SG_ 652 GW_MFS_LIM_switch_signal "3";
BA_ "GenSigCycleTime" SG_ 652 GW_MFS_DIST_switch_signal 40;
BA_ "GenSigInvalidValue" SG_ 652 GW_MFS_DIST_switch_signal "3";
BA_ "GenSigCycleTime" SG_ 652 GW_MFS_SETReduce_switch_signal 40;
BA_ "GenSigInvalidValue" SG_ 652 GW_MFS_SETReduce_switch_signal "3";
BA_ "GenSigCycleTime" SG_ 652 GW_MFS_RESPlus_switch_signal 40;
BA_ "GenSigInvalidValue" SG_ 652 GW_MFS_RESPlus_switch_signal "3";
BA_ "GenSigCycleTime" SG_ 652 GW_MFS_Cancle_switch_signal 40;
BA_ "GenSigInvalidValue" SG_ 652 GW_MFS_Cancle_switch_signal "3";
BA_ "GenSigCycleTime" SG_ 652 GW_MFS_Crusie_switch_signal 40;
BA_ "GenSigInvalidValue" SG_ 652 GW_MFS_Crusie_switch_signal "3";
BA_ "GenSigCycleTime" SG_ 652 GW_MFS_DISTReduce_switch_signal 40;
BA_ "GenSigCycleTime" SG_ 652 GW_MFS_DISTPlus_switch_signal 40;
BA_ "GenSigSendType" SG_ 372 APA_ReqSYNMSG 1;
BA_ "GenSigCycleTime" SG_ 431 TCU_ShiftPostionValid 10;
BA_ "GenSigInvalidValue" SG_ 431 TCU_ShiftPostionValid "1";
BA_ "GenSigCycleTime" SG_ 431 TCU_RollingCounter_1A8 10;
BA_ "GenSigCycleTime" SG_ 431 TCU_GearShiftPosition 10;
BA_ "GenSigInvalidValue" SG_ 431 TCU_GearShiftPosition "15";
BA_ "GenSigStartValue" SG_ 431 TCU_GearShiftPosition 13;
BA_ "GenSigCycleTime" SG_ 431 TCU_CRCCheck_1A8 10;
BA_ "GenSigCycleTime" SG_ 431 TCU_ActualDrivingGearValid 10;
BA_ "GenSigInvalidValue" SG_ 431 TCU_ActualDrivingGearValid "1";
BA_ "GenSigCycleTime" SG_ 431 TCU_ActualDrivingGear 10;
BA_ "GenSigInvalidValue" SG_ 431 TCU_ActualDrivingGear "15";
BA_ "GenSigCycleTime" SG_ 800 GW_ADSSecOCVerifyFailureFlag 100;
BA_ "GenSigInvalidValue" SG_ 800 GW_ADSSecOCVerifyFailureFlag "1";
BA_ "GenSigCycleTime" SG_ 800 GW_DCANDiagSts 100;
BA_ "GenSigInvalidValue" SG_ 800 GW_DCANDiagSts "NA";
BA_ "GenSigCycleTime" SG_ 800 GW_GatewayFailureFlag 100;
BA_ "GenSigInvalidValue" SG_ 800 GW_GatewayFailureFlag "0";
BA_ "GenSigCycleTime" SG_ 800 GW_OTAmode_Chks 100;
BA_ "GenSigInvalidValue" SG_ 800 GW_OTAmode_Chks "0";
BA_ "GenSigCycleTime" SG_ 800 GW_OTAmode_Cntr 100;
BA_ "GenSigInvalidValue" SG_ 800 GW_OTAmode_Cntr "0";
BA_ "GenSigCycleTime" SG_ 800 GW_OTAmode 100;
BA_ "GenSigInvalidValue" SG_ 800 GW_OTAmode "0";
BA_ "GenSigCycleTime" SG_ 800 GW_ResetReq 100;
BA_ "GenSigInvalidValue" SG_ 800 GW_ResetReq "127";
BA_ "GenSigCycleTime" SG_ 922 LAS_RoadFeature 100;
BA_ "GenSigInvalidValue" SG_ 922 LAS_RoadFeature "15";
BA_ "GenSigStartValue" SG_ 922 LAS_RoadFeature 15;
BA_ "GenSigCycleTime" SG_ 922 LAS_RD4LongDistence 100;
BA_ "GenSigInvalidValue" SG_ 922 LAS_RD4LongDistence "255";
BA_ "GenSigStartValue" SG_ 922 LAS_RD4LongDistence 255;
BA_ "GenSigCycleTime" SG_ 922 LAS_RD3LongDistence 100;
BA_ "GenSigInvalidValue" SG_ 922 LAS_RD3LongDistence "255";
BA_ "GenSigStartValue" SG_ 922 LAS_RD3LongDistence 255;
BA_ "GenSigCycleTime" SG_ 922 LAS_RD2LongDistence 100;
BA_ "GenSigInvalidValue" SG_ 922 LAS_RD2LongDistence "255";
BA_ "GenSigStartValue" SG_ 922 LAS_RD2LongDistence 255;
BA_ "GenSigCycleTime" SG_ 922 LAS_RD1LongDistence 100;
BA_ "GenSigInvalidValue" SG_ 922 LAS_RD1LongDistence "255";
BA_ "GenSigStartValue" SG_ 922 LAS_RD1LongDistence 255;
BA_ "GenSigCycleTime" SG_ 922 LAS_RD4RoadInforAvailable 100;
BA_ "GenSigInvalidValue" SG_ 922 LAS_RD4RoadInforAvailable "1";
BA_ "GenSigCycleTime" SG_ 922 LAS_RD3RoadInforAvailable 100;
BA_ "GenSigInvalidValue" SG_ 922 LAS_RD3RoadInforAvailable "1";
BA_ "GenSigCycleTime" SG_ 922 LAS_RD2RoadInforAvailable 100;
BA_ "GenSigInvalidValue" SG_ 922 LAS_RD2RoadInforAvailable "1";
BA_ "GenSigCycleTime" SG_ 922 LAS_RD1RoadInforAvailable 100;
BA_ "GenSigInvalidValue" SG_ 922 LAS_RD1RoadInforAvailable "1";
BA_ "GenSigCycleTime" SG_ 922 LAS_RollingCounter_579 100;
BA_ "GenSigCycleTime" SG_ 922 LAS_CRCCheck_579 100;
BA_ "GenSigCycleTime" SG_ 922 ACC_RollingCounter_39A 100;
BA_ "GenSigCycleTime" SG_ 922 ACC_CRCCheck_39A 100;
BA_ "GenSigCycleTime" SG_ 922 LAS_TSRRightLaneStatus 100;
BA_ "GenSigInvalidValue" SG_ 922 LAS_TSRRightLaneStatus "7";
BA_ "GenSigCycleTime" SG_ 922 LAS_TSRLeftLaneStatus 100;
BA_ "GenSigInvalidValue" SG_ 922 LAS_TSRLeftLaneStatus "7";
BA_ "GenSigCycleTime" SG_ 922 LAS_CRCCheck_3C0 100;
BA_ "GenSigCycleTime" SG_ 922 LAS_RollingCounter_3C0 100;
BA_ "GenSigCycleTime" SG_ 922 LAS_TSRRightLaneSpdLimit 100;
BA_ "GenSigInvalidValue" SG_ 922 LAS_TSRRightLaneSpdLimit "254";
BA_ "GenSigCycleTime" SG_ 922 LAS_TSRLeftLaneSpdLimit 100;
BA_ "GenSigInvalidValue" SG_ 922 LAS_TSRLeftLaneSpdLimit "254";
BA_ "GenSigCycleTime" SG_ 922 LAS_CRCCheck_3D4 100;
BA_ "GenSigCycleTime" SG_ 922 LAS_RollingCounter_3D4 100;
BA_ "GenSigCycleTime" SG_ 922 LAS_TLAStopLine_HostLane 100;
BA_ "GenSigStartValue" SG_ 922 LAS_TLAStopLine_HostLane 255;
BA_ "GenSigCycleTime" SG_ 922 LAS_TLADistance_HostLane 100;
BA_ "GenSigStartValue" SG_ 922 LAS_TLADistance_HostLane 255;
BA_ "GenSigCycleTime" SG_ 922 LAS_TLACountDownTime_HostLane 100;
BA_ "GenSigCycleTime" SG_ 922 LAS_TSRMandatorySign 100;
BA_ "GenSigCycleTime" SG_ 922 LAS_TSRWarningSign 100;
BA_ "GenSigCycleTime" SG_ 922 LAS_TSRProhibitionSign 100;
BA_ "GenSigCycleTime" SG_ 922 LAS_CRCCheck_332 100;
BA_ "GenSigCycleTime" SG_ 922 LAS_RollingCounter_332 100;
BA_ "GenSigCycleTime" SG_ 922 LAS_OverspeedSoundWarningEnSt 100;
BA_ "GenSigCycleTime" SG_ 922 LAS_TSREnable 100;
BA_ "GenSigCycleTime" SG_ 922 LAS_HMAEnableStatus 100;
BA_ "GenSigCycleTime" SG_ 922 LAS_HMALightDistribution 100;
BA_ "GenSigCycleTime" SG_ 922 LAS_HMAStatus 100;
BA_ "GenSigInvalidValue" SG_ 922 LAS_HMAStatus "3";
BA_ "GenSigCycleTime" SG_ 922 LAS_TSRHostSpdLimitUnits 100;
BA_ "GenSigInvalidValue" SG_ 922 LAS_TSRHostSpdLimitUnits "0";
BA_ "GenSigCycleTime" SG_ 922 LAS_TSRHostSpdLimit 100;
BA_ "GenSigInvalidValue" SG_ 922 LAS_TSRHostSpdLimit "254";
BA_ "GenSigCycleTime" SG_ 922 LAS_TSRStatus 100;
BA_ "GenSigInvalidValue" SG_ 922 LAS_TSRStatus "7";
BA_ "GenSigCycleTime" SG_ 922 LAS_FrontCameraCalibrationStatus 100;
BA_ "GenSigInvalidValue" SG_ 922 LAS_FrontCameraCalibrationStatus "3";
BA_ "GenSigCycleTime" SG_ 922 LAS_FrontCameraFailureStatus 100;
BA_ "GenSigInvalidValue" SG_ 922 LAS_FrontCameraFailureStatus "3";
BA_ "GenSigCycleTime" SG_ 922 LAS_OverspeedWarningOffset 100;
BA_ "GenSigStartValue" SG_ 922 LAS_OverspeedWarningOffset 10;
BA_ "GenSigCycleTime" SG_ 922 LAS_OverspeedWarningEnableStatus 100;
BA_ "GenSigCycleTime" SG_ 922 LAS_OverspeedSoundWarning 100;
BA_ "GenSigCycleTime" SG_ 922 LAS_OverspeedVisualWarning 100;
BA_ "GenSigCycleTime" SG_ 922 LAS_CRCCheck_37D 100;
BA_ "GenSigCycleTime" SG_ 922 LAS_RollingCounter_37D 100;
BA_ "GenSigCycleTime" SG_ 922 LAS_TLAArrowDirection_RightLane 100;
BA_ "GenSigCycleTime" SG_ 922 LAS_TLAObjectType_RightLane 100;
BA_ "GenSigCycleTime" SG_ 922 LAS_TLAObjectStatus_RightLane 100;
BA_ "GenSigCycleTime" SG_ 922 LAS_TLAObjectColour_RightLane 100;
BA_ "GenSigCycleTime" SG_ 922 LAS_TLAObjectDetection_RightLane 100;
BA_ "GenSigCycleTime" SG_ 922 LAS_TLAArrowDirection_LeftLane 100;
BA_ "GenSigCycleTime" SG_ 922 LAS_TLAObjectType_LeftLane 100;
BA_ "GenSigCycleTime" SG_ 922 LAS_TLAObjectStatus_LeftLane 100;
BA_ "GenSigCycleTime" SG_ 922 LAS_TLAObjectColour_LeftLane 100;
BA_ "GenSigCycleTime" SG_ 922 LAS_TLAObjectDetection_LeftLane 100;
BA_ "GenSigCycleTime" SG_ 922 LAS_TLAArrowDirection_HostLane 100;
BA_ "GenSigCycleTime" SG_ 922 LAS_TLAObjectStatus_HostLane 100;
BA_ "GenSigCycleTime" SG_ 922 LAS_TLAObjectType_HostLane 100;
BA_ "GenSigCycleTime" SG_ 922 LAS_TLAObjectColour_HostLane 100;
BA_ "GenSigCycleTime" SG_ 922 LAS_TLAObjectDetection_HostLane 100;
BA_ "GenSigCycleTime" SG_ 922 LAS_TLAWarninglevel 100;
BA_ "GenSigCycleTime" SG_ 922 LAS_TLAStatus 100;
BA_ "GenSigInvalidValue" SG_ 922 LAS_TLAStatus "3";
BA_ "GenSigCycleTime" SG_ 922 LAS_TLAEnable 100;
BA_ "GenSigCycleTime" SG_ 922 LAS_RoadSignCenterLatRange_RLane 100;
BA_ "GenSigCycleTime" SG_ 922 LAS_RoadSignCenterLngRange_RLane 100;
BA_ "GenSigCycleTime" SG_ 922 LAS_RoadSignCenterLatRange_LLane 100;
BA_ "GenSigCycleTime" SG_ 922 LAS_RoadSignCenterLngRange_LLane 100;
BA_ "GenSigCycleTime" SG_ 922 LAS_RoadSignCenterLatRange_HLane 100;
BA_ "GenSigCycleTime" SG_ 922 LAS_RoadSignCenterLngRange_HLane 100;
BA_ "GenSigCycleTime" SG_ 922 LAS_CrosswalkLngRange_HLane 100;
BA_ "GenSigStartValue" SG_ 922 LAS_CrosswalkLngRange_HLane 255;
BA_ "GenSigCycleTime" SG_ 922 LAS_RoadSignType_RLane 100;
BA_ "GenSigCycleTime" SG_ 922 LAS_RoadSignType_LLane 100;
BA_ "GenSigCycleTime" SG_ 922 LAS_RoadSignType_HLane 100;
BA_ "GenSigCycleTime" SG_ 906 GW_MFS_Cust_switch 40;
BA_ "GenSigInvalidValue" SG_ 906 GW_MFS_Cust_switch "3";
BA_ "GenSigCycleTime" SG_ 583 APA_EngTorqReq 20;
BA_ "GenSigInvalidValue" SG_ 583 APA_EngTorqReq "1023";
BA_ "GenSigCycleTime" SG_ 583 APA_SlotNotice_1 20;
BA_ "GenSigCycleTime" SG_ 583 APA_VCUReadyReq 20;
BA_ "GenSigCycleTime" SG_ 583 APA_ESPDistToStop 20;
BA_ "GenSigCycleTime" SG_ 583 APA_ESP_StandstillRequest 20;
BA_ "GenSigCycleTime" SG_ 583 APA_RollingCounter_236 20;
BA_ "GenSigCycleTime" SG_ 583 APA_CRC_Checksum_236 20;
BA_ "GenSigCycleTime" SG_ 583 APA_PtTrqReqValid 20;
BA_ "GenSigCycleTime" SG_ 583 APA_LatLongSC 20;
BA_ "GenSigCycleTime" SG_ 583 APA_ESP_BrakeFunctionMode 20;
BA_ "GenSigInvalidValue" SG_ 583 APA_ESP_BrakeFunctionMode "0";
BA_ "GenSigCycleTime" SG_ 583 APA_TrqHoldForTCUCl 20;
BA_ "GenSigCycleTime" SG_ 583 APA_TCUClutchCombinationReq 20;
BA_ "GenSigCycleTime" SG_ 583 APA_FunctionOnOffSts 20;
BA_ "GenSigInvalidValue" SG_ 583 APA_FunctionOnOffSts "15";
BA_ "GenSigCycleTime" SG_ 583 APA_APAOnOff 20;
BA_ "GenSigCycleTime" SG_ 583 APA_CRCCheck_264 20;
BA_ "GenSigCycleTime" SG_ 583 APA_ParkingPercentage 20;
BA_ "GenSigInvalidValue" SG_ 583 APA_ParkingPercentage "101";
BA_ "GenSigCycleTime" SG_ 583 APA_RollingCounter_264 20;
BA_ "GenSigCycleTime" SG_ 583 APA_TurnLightsCommand 20;
BA_ "GenSigInvalidValue" SG_ 583 APA_TurnLightsCommand "0";
BA_ "GenSigCycleTime" SG_ 583 APA_IncreasePressureReq 20;
BA_ "GenSigInvalidValue" SG_ 583 APA_IncreasePressureReq "0";
BA_ "GenSigCycleTime" SG_ 583 APA_RemoteOnOff 20;
BA_ "GenSigCycleTime" SG_ 583 APA_SteeringAngleReq 20;
BA_ "GenSigInvalidValue" SG_ 583 APA_SteeringAngleReq "32767";
BA_ "GenSigStartValue" SG_ 583 APA_SteeringAngleReq 32767;
BA_ "GenSigCycleTime" SG_ 583 APA_EmergenceBrake 20;
BA_ "GenSigInvalidValue" SG_ 583 APA_EmergenceBrake "0";
BA_ "GenSigCycleTime" SG_ 583 APA_ErrorStatus 20;
BA_ "GenSigCycleTime" SG_ 583 APA_SteeringAngleReqProtection 20;
BA_ "GenSigCycleTime" SG_ 583 APA_HSAHDforbidden 20;
BA_ "GenSigInvalidValue" SG_ 583 APA_HSAHDforbidden "0";
BA_ "GenSigCycleTime" SG_ 583 APA_CRCCheck_26C 20;
BA_ "GenSigCycleTime" SG_ 583 APA_RollingCounter_26C 20;
BA_ "GenSigCycleTime" SG_ 583 APA_AccPedShieldReq 20;
BA_ "GenSigCycleTime" SG_ 583 APA_SlotNotice 20;
BA_ "GenSigInvalidValue" SG_ 583 APA_SlotNotice "15";
BA_ "GenSigCycleTime" SG_ 583 APA_DynamicSlotWarning 20;
BA_ "GenSigInvalidValue" SG_ 583 APA_DynamicSlotWarning "0";
BA_ "GenSigCycleTime" SG_ 583 APA_Activation_Status 20;
BA_ "GenSigCycleTime" SG_ 583 APA_EngineTrqReqEnable 20;
BA_ "GenSigInvalidValue" SG_ 583 APA_EngineTrqReqEnable "0";
BA_ "GenSigCycleTime" SG_ 583 APA_LSCAction 20;
BA_ "GenSigCycleTime" SG_ 583 APA_TransPRNDShiftEnable 20;
BA_ "GenSigInvalidValue" SG_ 583 APA_TransPRNDShiftEnable "0";
BA_ "GenSigCycleTime" SG_ 583 APA_TargetAcceleration 20;
BA_ "GenSigStartValue" SG_ 583 APA_TargetAcceleration 100;
BA_ "GenSigCycleTime" SG_ 583 APA_TransPRNDShiftReqValid 20;
BA_ "GenSigInvalidValue" SG_ 583 APA_TransPRNDShiftReqValid "0";
BA_ "GenSigCycleTime" SG_ 583 APA_TransPRNDShiftRequest 20;
BA_ "GenSigInvalidValue" SG_ 583 APA_TransPRNDShiftRequest "0";
BA_ "GenSigCycleTime" SG_ 583 APA_TargetAccelerationValid 20;
BA_ "GenSigInvalidValue" SG_ 583 APA_TargetAccelerationValid "0";
BA_ "GenSigCycleTime" SG_ 583 APA_EPBrequestValid 20;
BA_ "GenSigInvalidValue" SG_ 583 APA_EPBrequestValid "0";
BA_ "GenSigCycleTime" SG_ 583 APA_EPBrequest 20;
BA_ "GenSigInvalidValue" SG_ 583 APA_EPBrequest "0";
BA_ "GenSigCycleTime" SG_ 583 APA_PtTorqReq 20;
BA_ "GenSigCycleTime" SG_ 583 APA_CRCCheck_247 20;
BA_ "GenSigCycleTime" SG_ 583 APA_RollingCounter_247 20;
BA_ "GenSigCycleTime" SG_ 610 PEPS_APA_PowerMirrorFoldFeedback 40;
BA_ "GenSigCycleTime" SG_ 610 PEPS_APARemoteParkingOff 40;
BA_ "GenSigCycleTime" SG_ 610 PEPS_CRCCheck_262 40;
BA_ "GenSigCycleTime" SG_ 610 PEPS_RollingCounter_262 40;
BA_ "GenSigCycleTime" SG_ 610 PEPS_PEPSFailStatus 40;
BA_ "GenSigCycleTime" SG_ 610 PEPS_RemoteStartFeedback 40;
BA_ "GenSigCycleTime" SG_ 610 PEPS_APA_CloseWinFeedback 40;
BA_ "GenSigInvalidValue" SG_ 610 PEPS_APA_CloseWinFeedback "0";
BA_ "GenSigCycleTime" SG_ 610 PEPS_RemoteAPADoneKeyOffReq 40;
BA_ "GenSigInvalidValue" SG_ 610 PEPS_RemoteAPADoneKeyOffReq "0";
BA_ "GenSigCycleTime" SG_ 610 PEPS_APA_Engine0ffFeedback 40;
BA_ "GenSigInvalidValue" SG_ 610 PEPS_APA_Engine0ffFeedback "0";
BA_ "GenSigCycleTime" SG_ 610 PEPS_APA_LockFeedback 40;
BA_ "GenSigInvalidValue" SG_ 610 PEPS_APA_LockFeedback "0";
BA_ "GenSigCycleTime" SG_ 610 PEPS_APARemoteParkingOn 40;
BA_ "GenSigCycleTime" SG_ 917 TBOX_APP_Ylevel 100;
BA_ "GenSigCycleTime" SG_ 917 TBOX_APP_Xlevel 100;
BA_ "GenSigCycleTime" SG_ 917 TBOX_APAControlEnable 100;
BA_ "GenSigCycleTime" SG_ 917 TBOX_RemoteStartReq 100;
BA_ "GenSigInvalidValue" SG_ 917 TBOX_RemoteStartReq "3";
BA_ "GenSigCycleTime" SG_ 917 TBOX_APAFunctionReq 100;
BA_ "GenSigCycleTime" SG_ 917 TBOX_SignalStrength 100;
BA_ "GenSigCycleTime" SG_ 917 TBOX_SignalType 100;
BA_ "GenSigCycleTime" SG_ 917 TBOX_APA_SignalDelay 100;
BA_ "GenSigCycleTime" SG_ 917 TBOX_APAmoduleEnable 100;
BA_ "GenSigCycleTime" SG_ 917 TBOX_RemoteDisReq 100;
BA_ "GenSigCycleTime" SG_ 917 TBOX_VehicleVedioDetectReq 100;
BA_ "GenSigInvalidValue" SG_ 917 TBOX_VehicleVedioDetectReq "0";
BA_ "GenSigCycleTime" SG_ 917 TBOX_RemoteDetectReq 100;
BA_ "GenSigInvalidValue" SG_ 917 TBOX_RemoteDetectReq "3";
BA_ "GenSigSendType" SG_ 1344 APA_RollingCounter_540 1;
BA_ "GenSigSendType" SG_ 1344 APA_CRCCheck_540 1;
BA_ "GenSigSendType" SG_ 1344 APA_HornRq 1;
BA_ "GenSigSendType" SG_ 1344 APA_HighLampRq 1;
BA_ "GenSigSendType" SG_ 1344 APA_RigtLowLampRq 1;
BA_ "GenSigSendType" SG_ 1344 APA_LeftLowLampRq 1;
BA_ "GenSigSendType" SG_ 1360 APA_RollingCounter_550 1;
BA_ "GenSigSendType" SG_ 1360 APA_CRCCheck_550 1;
BA_ "GenSigSendType" SG_ 1360 APA_RightRearWindowControl 1;
BA_ "GenSigSendType" SG_ 1360 APA_LeftRearWindowControl 1;
BA_ "GenSigSendType" SG_ 1360 APA_PassengerWindowControl 1;
BA_ "GenSigSendType" SG_ 1360 APA_DriverWindowControl 1;
BA_ "GenSigSendType" SG_ 1360 APA_MirrorAutoFoldReq 1;
BA_ "GenSigSendType" SG_ 1360 APA_DoorLockRq 1;
BA_ "GenSigSendType" SG_ 1360 APA_HiddenHandleControlReq 1;
BA_ "GenSigSendType" SG_ 1364 APA_RollingCounter_554 1;
BA_ "GenSigSendType" SG_ 1364 APA_CRCCheck_554 1;
BA_ "GenSigCycleTime" SG_ 1554 DVR_EmergencyRecordStatus 100;
BA_ "GenSigInvalidValue" SG_ 1554 DVR_EmergencyRecordStatus "0";
BA_ "GenSigCycleTime" SG_ 394 TCU_APAShiftGearRequestEnable 10;
BA_ "GenSigInvalidValue" SG_ 394 TCU_APAShiftGearRequestEnable "3";
BA_ "GenSigCycleTime" SG_ 394 TCU_APAdriverInterruption 10;
BA_ "GenSigInvalidValue" SG_ 394 TCU_APAdriverInterruption "3";
BA_ "GenSigCycleTime" SG_ 586 ESL_CRCCheck_24A 20;
BA_ "GenSigCycleTime" SG_ 586 ESL_RollingCounter_24A 20;
BA_ "GenSigCycleTime" SG_ 586 ESL_DriveModeRequest 20;
BA_ "GenSigInvalidValue" SG_ 586 ESL_DriveModeRequest "15";
BA_ "GenSigCycleTime" SG_ 586 ESL_DriverParkButtonFaultStatus 20;
BA_ "GenSigCycleTime" SG_ 586 ESL_DriverParkRequest 20;
BA_ "GenSigInvalidValue" SG_ 586 ESL_DriverParkRequest "3";
BA_ "GenSigCycleTime" SG_ 586 ESL_ShiftLeverPositionrequest 20;
BA_ "GenSigInvalidValue" SG_ 586 ESL_ShiftLeverPositionrequest "15";
BA_ "GenSigCycleTime" SG_ 586 ESL_ShiftLeverPositionFaultSts 20;
BA_ "GenSigSendType" SG_ 604 GW_Authernticator_25C 1;
BA_ "GenSigSendType" SG_ 604 GW_ResetCounter_25C 1;
BA_ "GenSigSendType" SG_ 604 GW_TripCounter_25C 1;
BA_ "GenSigCycleTime" SG_ 710 APA_FunctionOnOffSts 40;
BA_ "GenSigInvalidValue" SG_ 710 APA_FunctionOnOffSts "15";
BA_ "GenSigCycleTime" SG_ 710 APA_ParkingSlot_Width 40;
BA_ "GenSigInvalidValue" SG_ 710 APA_ParkingSlot_Width "0";
BA_ "GenSigCycleTime" SG_ 710 APA_ParkingSlot_Length 40;
BA_ "GenSigInvalidValue" SG_ 710 APA_ParkingSlot_Length "0";
BA_ "GenSigCycleTime" SG_ 710 APA_ParkingSlot_ExtraFeature 40;
BA_ "GenSigInvalidValue" SG_ 710 APA_ParkingSlot_ExtraFeature "0";
BA_ "GenSigCycleTime" SG_ 710 APA_ParkingSlot_Type 40;
BA_ "GenSigInvalidValue" SG_ 710 APA_ParkingSlot_Type "0";
BA_ "GenSigCycleTime" SG_ 710 APA_ActivationSts 40;
BA_ "GenSigCycleTime" SG_ 710 APA_CRCCheck_2C6 40;
BA_ "GenSigCycleTime" SG_ 710 APA_RollingCounter_2C6 40;
BA_ "GenSigCycleTime" SG_ 710 APA_Condition_Notice 40;
BA_ "GenSigCycleTime" SG_ 710 APA_TouchInfOnOffRes 40;
BA_ "GenSigCycleTime" SG_ 710 APA_RADSNotice 40;
BA_ "GenSigInvalidValue" SG_ 710 APA_RADSNotice "31";
BA_ "GenSigCycleTime" SG_ 710 APA_PowerMirrorFoldReq 40;
BA_ "GenSigCycleTime" SG_ 710 APA_LAEBReq 40;
BA_ "GenSigCycleTime" SG_ 710 APA_left_fishboneslot_type 40;
BA_ "GenSigCycleTime" SG_ 710 APA_right_fishboneslot_type 40;
BA_ "GenSigCycleTime" SG_ 710 APA_right_slot_4_available_sts 40;
BA_ "GenSigCycleTime" SG_ 710 APA_right_slot_3_available_sts 40;
BA_ "GenSigCycleTime" SG_ 710 APA_right_slot_2_available_sts 40;
BA_ "GenSigCycleTime" SG_ 710 APA_right_slot_1_available_sts 40;
BA_ "GenSigCycleTime" SG_ 710 APA_left_slot_4_available_sts 40;
BA_ "GenSigCycleTime" SG_ 710 APA_left_slot_3_available_sts 40;
BA_ "GenSigCycleTime" SG_ 710 APA_left_slot_2_available_sts 40;
BA_ "GenSigCycleTime" SG_ 710 APA_left_slot_1_available_sts 40;
BA_ "GenSigCycleTime" SG_ 710 APA_right_slot_4_distance_px 40;
BA_ "GenSigCycleTime" SG_ 710 APA_right_slot_4_type 40;
BA_ "GenSigCycleTime" SG_ 710 APA_right_slot_3_distance_px 40;
BA_ "GenSigCycleTime" SG_ 710 APA_right_slot_3_type 40;
BA_ "GenSigCycleTime" SG_ 710 APA_left_slot_4_distance_px 40;
BA_ "GenSigCycleTime" SG_ 710 APA_left_slot_4_type 40;
BA_ "GenSigCycleTime" SG_ 710 APA_left_slot_3_distance_px 40;
BA_ "GenSigCycleTime" SG_ 710 APA_left_slot_3_type 40;
BA_ "GenSigCycleTime" SG_ 710 APA_NumberofParkingSlot 40;
BA_ "GenSigCycleTime" SG_ 710 APA_BCMHornCommand 40;
BA_ "GenSigInvalidValue" SG_ 710 APA_BCMHornCommand "0";
BA_ "GenSigCycleTime" SG_ 710 APA_PEPS_EngineOffLockRequest 40;
BA_ "GenSigCycleTime" SG_ 710 APA_RemoteParkingUsingRemind 40;
BA_ "GenSigInvalidValue" SG_ 710 APA_RemoteParkingUsingRemind "0";
BA_ "GenSigCycleTime" SG_ 710 APA_BLEConnectionRemind 40;
BA_ "GenSigInvalidValue" SG_ 710 APA_BLEConnectionRemind "0";
BA_ "GenSigCycleTime" SG_ 710 APA_ReleasePressureReq 40;
BA_ "GenSigInvalidValue" SG_ 710 APA_ReleasePressureReq "0";
BA_ "GenSigCycleTime" SG_ 710 APA_LAEBNotice 40;
BA_ "GenSigCycleTime" SG_ 710 APA_LAEBStatus 40;
BA_ "GenSigCycleTime" SG_ 710 APA_ParkNotice_5 40;
BA_ "GenSigInvalidValue" SG_ 710 APA_ParkNotice_5 "17";
BA_ "GenSigCycleTime" SG_ 710 APA_right_slot_2_distance_px 40;
BA_ "GenSigCycleTime" SG_ 710 APA_right_slot_1_distance_px 40;
BA_ "GenSigCycleTime" SG_ 710 APA_right_slot_2_type 40;
BA_ "GenSigCycleTime" SG_ 710 APA_right_slot_1_type 40;
BA_ "GenSigCycleTime" SG_ 710 APA_left_slot_2_distance_px 40;
BA_ "GenSigCycleTime" SG_ 710 APA_left_slot_1_distance_px 40;
BA_ "GenSigCycleTime" SG_ 710 APA_left_slot_2_type 40;
BA_ "GenSigCycleTime" SG_ 710 APA_left_slot_1_type 40;
BA_ "GenSigCycleTime" SG_ 798 APA_RollingCounter_31E 100;
BA_ "GenSigCycleTime" SG_ 798 APA_CRCCheck_31E 100;
BA_ "GenSigCycleTime" SG_ 798 APA_VoiceTipType 100;
BA_ "GenSigCycleTime" SG_ 798 APA_ActiveSts 100;
BA_ "GenSigCycleTime" SG_ 798 APA_ParkVoiceIntSet 100;
BA_ "GenSigCycleTime" SG_ 798 APA_AVMNotice 100;
BA_ "GenSigCycleTime" SG_ 798 RRS_LoudspeakersPosition 100;
BA_ "GenSigCycleTime" SG_ 798 APA_SystemFailureFlag 100;
BA_ "GenSigInvalidValue" SG_ 798 APA_SystemFailureFlag "0";
BA_ "GenSigCycleTime" SG_ 798 APA_ObstacleSafeDistSetStatus 100;
BA_ "GenSigInvalidValue" SG_ 798 APA_ObstacleSafeDistSetStatus "0";
BA_ "GenSigCycleTime" SG_ 798 APA_Uls_FKP_WarningSoundStatus 100;
BA_ "GenSigInvalidValue" SG_ 798 APA_Uls_FKP_WarningSoundStatus "0";
BA_ "GenSigCycleTime" SG_ 798 APA_CrossParkingModeSetSts 100;
BA_ "GenSigCycleTime" SG_ 798 APA_CRCCheck_3BA 100;
BA_ "GenSigCycleTime" SG_ 798 APA_RollingCounter_3BA 100;
BA_ "GenSigCycleTime" SG_ 798 ACC_LAEBEnableSts 100;
BA_ "GenSigCycleTime" SG_ 798 APA_CRCCheck_2A7 100;
BA_ "GenSigCycleTime" SG_ 798 APA_RollingCounter_2A7 100;
BA_ "GenSigCycleTime" SG_ 798 RFS_Sector_Dist 100;
BA_ "GenSigInvalidValue" SG_ 798 RFS_Sector_Dist "127";
BA_ "GenSigCycleTime" SG_ 798 LFS_Sector_Dist 100;
BA_ "GenSigInvalidValue" SG_ 798 LFS_Sector_Dist "127";
BA_ "GenSigCycleTime" SG_ 798 RFC_Sector_Dist 100;
BA_ "GenSigInvalidValue" SG_ 798 RFC_Sector_Dist "127";
BA_ "GenSigCycleTime" SG_ 798 LFC_Sector_Dist 100;
BA_ "GenSigInvalidValue" SG_ 798 LFC_Sector_Dist "127";
BA_ "GenSigCycleTime" SG_ 798 RFM_Sector_Dist 100;
BA_ "GenSigInvalidValue" SG_ 798 RFM_Sector_Dist "127";
BA_ "GenSigCycleTime" SG_ 798 LFM_Sector_Dist 100;
BA_ "GenSigInvalidValue" SG_ 798 LFM_Sector_Dist "127";
BA_ "GenSigCycleTime" SG_ 798 APA_CRCCheck_2A6 100;
BA_ "GenSigCycleTime" SG_ 798 APA_RollingCounter_2A6 100;
BA_ "GenSigCycleTime" SG_ 798 RRS_Sector_Dist 100;
BA_ "GenSigInvalidValue" SG_ 798 RRS_Sector_Dist "127";
BA_ "GenSigCycleTime" SG_ 798 LRS_Sector_Dist 100;
BA_ "GenSigInvalidValue" SG_ 798 LRS_Sector_Dist "127";
BA_ "GenSigCycleTime" SG_ 798 RRC_Sector_Dist 100;
BA_ "GenSigInvalidValue" SG_ 798 RRC_Sector_Dist "127";
BA_ "GenSigCycleTime" SG_ 798 LRC_Sector_Dist 100;
BA_ "GenSigInvalidValue" SG_ 798 LRC_Sector_Dist "127";
BA_ "GenSigCycleTime" SG_ 798 RRM_Sector_Dist 100;
BA_ "GenSigInvalidValue" SG_ 798 RRM_Sector_Dist "255";
BA_ "GenSigCycleTime" SG_ 798 LRM_Sector_Dist 100;
BA_ "GenSigInvalidValue" SG_ 798 LRM_Sector_Dist "255";
BA_ "GenSigCycleTime" SG_ 798 RRF_Sector_Dist 100;
BA_ "GenSigInvalidValue" SG_ 798 RRF_Sector_Dist "127";
BA_ "GenSigCycleTime" SG_ 798 LRF_Sector_Dist 100;
BA_ "GenSigInvalidValue" SG_ 798 LRF_Sector_Dist "127";
BA_ "GenSigCycleTime" SG_ 798 RFF_Sector_Dist 100;
BA_ "GenSigInvalidValue" SG_ 798 RFF_Sector_Dist "127";
BA_ "GenSigCycleTime" SG_ 798 LFF_Sector_Dist 100;
BA_ "GenSigInvalidValue" SG_ 798 LFF_Sector_Dist "127";
BA_ "GenSigCycleTime" SG_ 798 RRS_FrontRadarActiveStatus 100;
BA_ "GenSigInvalidValue" SG_ 798 RRS_FrontRadarActiveStatus "0";
BA_ "GenSigCycleTime" SG_ 798 RRS_SwitchIndicatorError 100;
BA_ "GenSigInvalidValue" SG_ 798 RRS_SwitchIndicatorError "0";
BA_ "GenSigCycleTime" SG_ 798 RRS_ButtonPress 100;
BA_ "GenSigInvalidValue" SG_ 798 RRS_ButtonPress "0";
BA_ "GenSigCycleTime" SG_ 798 RRS_WarningType 100;
BA_ "GenSigInvalidValue" SG_ 798 RRS_WarningType "0";
BA_ "GenSigCycleTime" SG_ 798 RRS_WarningFrequency 100;
BA_ "GenSigInvalidValue" SG_ 798 RRS_WarningFrequency "0";
BA_ "GenSigCycleTime" SG_ 798 RRS_LFSDistance 100;
BA_ "GenSigInvalidValue" SG_ 798 RRS_LFSDistance "7";
BA_ "GenSigCycleTime" SG_ 798 RRS_LRSDistance 100;
BA_ "GenSigInvalidValue" SG_ 798 RRS_LRSDistance "7";
BA_ "GenSigCycleTime" SG_ 798 RRS_RFSDistance 100;
BA_ "GenSigInvalidValue" SG_ 798 RRS_RFSDistance "7";
BA_ "GenSigCycleTime" SG_ 798 RRS_SideZoneStatus_Rear 100;
BA_ "GenSigInvalidValue" SG_ 798 RRS_SideZoneStatus_Rear "0";
BA_ "GenSigCycleTime" SG_ 798 RRS_SideZoneStatus_Front 100;
BA_ "GenSigInvalidValue" SG_ 798 RRS_SideZoneStatus_Front "0";
BA_ "GenSigCycleTime" SG_ 798 RRS_RRSDistance 100;
BA_ "GenSigInvalidValue" SG_ 798 RRS_RRSDistance "0";
BA_ "GenSigCycleTime" SG_ 798 RRS_MODE 100;
BA_ "GenSigInvalidValue" SG_ 798 RRS_MODE "7";
BA_ "GenSigCycleTime" SG_ 798 RRS_LFMDistance 100;
BA_ "GenSigInvalidValue" SG_ 798 RRS_LFMDistance "15";
BA_ "GenSigCycleTime" SG_ 798 RRS_RFMDistance 100;
BA_ "GenSigInvalidValue" SG_ 798 RRS_RFMDistance "15";
BA_ "GenSigCycleTime" SG_ 798 RRS_RFCDistance 100;
BA_ "GenSigInvalidValue" SG_ 798 RRS_RFCDistance "15";
BA_ "GenSigCycleTime" SG_ 798 RRS_LFCDistance 100;
BA_ "GenSigInvalidValue" SG_ 798 RRS_LFCDistance "15";
BA_ "GenSigCycleTime" SG_ 798 RRS_RRCDistance 100;
BA_ "GenSigInvalidValue" SG_ 798 RRS_RRCDistance "15";
BA_ "GenSigCycleTime" SG_ 798 RRS_LRCDistance 100;
BA_ "GenSigInvalidValue" SG_ 798 RRS_LRCDistance "15";
BA_ "GenSigCycleTime" SG_ 798 RRS_RRMDistance 100;
BA_ "GenSigInvalidValue" SG_ 798 RRS_RRMDistance "15";
BA_ "GenSigCycleTime" SG_ 798 RRS_LRMDistance 100;
BA_ "GenSigInvalidValue" SG_ 798 RRS_LRMDistance "15";
BA_ "GenSigCycleTime" SG_ 833 PCU_PwrTqWhMinVld 100;
BA_ "GenSigCycleTime" SG_ 833 PCU_PwrTqWhMinTotal 100;
BA_ "GenSigCycleTime" SG_ 833 PCU_PwrTqWhMaxVld 100;
BA_ "GenSigCycleTime" SG_ 833 PCU_PwrTqWhMaxTotal 100;
BA_ "GenSigCycleTime" SG_ 833 PCU_AccPedShield 100;
BA_ "GenSigCycleTime" SG_ 866 PCU_eDTE 100;
BA_ "GenSigInvalidValue" SG_ 866 PCU_eDTE "511";
BA_ "GenSigCycleTime" SG_ 930 RFBT_ResetFlag_3A2 100;
BA_ "GenSigCycleTime" SG_ 930 RFBT_MesssageCounter_3A2 100;
BA_ "GenSigCycleTime" SG_ 930 RFBT_Authernticator_3A2 100;
BA_ "GenSigCycleTime" SG_ 930 GW_Smartphone_APAmoduleEnable 100;
BA_ "GenSigCycleTime" SG_ 930 GW_RFBT_Verticalforward 100;
BA_ "GenSigCycleTime" SG_ 930 GW_RFBT_Verticalbackward 100;
BA_ "GenSigCycleTime" SG_ 930 GW_RFBT_SlotUserSelected 100;
BA_ "GenSigInvalidValue" SG_ 930 GW_RFBT_SlotUserSelected "7";
BA_ "GenSigCycleTime" SG_ 930 GW_RFBT_RPASwitch 100;
BA_ "GenSigInvalidValue" SG_ 930 GW_RFBT_RPASwitch "0";
BA_ "GenSigCycleTime" SG_ 930 GW_RFBT_APAPOCModeSelect 100;
BA_ "GenSigInvalidValue" SG_ 930 GW_RFBT_APAPOCModeSelect "7";
BA_ "GenSigCycleTime" SG_ 930 GW_RFBT_APAManeuverSuspend 100;
BA_ "GenSigInvalidValue" SG_ 930 GW_RFBT_APAManeuverSuspend "0";
BA_ "GenSigCycleTime" SG_ 930 GW_RFBT_APAManeuverStart 100;
BA_ "GenSigInvalidValue" SG_ 930 GW_RFBT_APAManeuverStart "0";
BA_ "GenSigCycleTime" SG_ 930 GW_RFBT_APAManeuverCancel 100;
BA_ "GenSigInvalidValue" SG_ 930 GW_RFBT_APAManeuverCancel "0";
BA_ "GenSigCycleTime" SG_ 951 AVM_RightCameraSts 100;
BA_ "GenSigCycleTime" SG_ 951 AVM_LeftCameraSts 100;
BA_ "GenSigCycleTime" SG_ 951 AVM_RearCameraSts 100;
BA_ "GenSigCycleTime" SG_ 951 AVM_FrontCameraSts 100;
BA_ "GenSigCycleTime" SG_ 982 SLCM_RRWindowStatus 100;
BA_ "GenSigInvalidValue" SG_ 982 SLCM_RRWindowStatus "255";
BA_ "GenSigCycleTime" SG_ 982 SLCM_PassengerWindowStatus 100;
BA_ "GenSigInvalidValue" SG_ 982 SLCM_PassengerWindowStatus "255";
BA_ "GenSigCycleTime" SG_ 984 SLCM_RLWindowStatus 100;
BA_ "GenSigInvalidValue" SG_ 984 SLCM_RLWindowStatus "255";
BA_ "GenSigCycleTime" SG_ 984 SLCM_DriverWindowStatus 100;
BA_ "GenSigInvalidValue" SG_ 984 SLCM_DriverWindowStatus "255";
BA_ "GenSigCycleTime" SG_ 1006 RFBT_BLEConnectSts 100;
BA_ "GenSigInvalidValue" SG_ 1006 RFBT_BLEConnectSts "7";
BA_ "GenSigCycleTime" SG_ 1295 ACC_ResetSts 200;
BA_ "GenSigInvalidValue" SG_ 1295 ACC_ResetSts "7";
BA_ "GenSigCycleTime" SG_ 1295 LCDAR_ResetSts 200;
BA_ "GenSigInvalidValue" SG_ 1295 LCDAR_ResetSts "7";
BA_ "GenSigCycleTime" SG_ 1295 LCDAL_ResetSts 200;
BA_ "GenSigInvalidValue" SG_ 1295 LCDAL_ResetSts "7";
BA_ "GenSigCycleTime" SG_ 1295 FRR_ResetSts 200;
BA_ "GenSigInvalidValue" SG_ 1295 FRR_ResetSts "7";
BA_ "GenSigCycleTime" SG_ 1295 FLR_ResetSts 200;
BA_ "GenSigInvalidValue" SG_ 1295 FLR_ResetSts "7";
BA_ "GenSigCycleTime" SG_ 1295 APA_Coordinate_Angle 200;
BA_ "GenSigInvalidValue" SG_ 1295 APA_Coordinate_Angle "511";
BA_ "GenSigStartValue" SG_ 1295 APA_Coordinate_Angle 511;
BA_ "GenSigCycleTime" SG_ 1295 APA_Coordinate_Y 200;
BA_ "GenSigInvalidValue" SG_ 1295 APA_Coordinate_Y "4095";
BA_ "GenSigStartValue" SG_ 1295 APA_Coordinate_Y 4095;
BA_ "GenSigCycleTime" SG_ 1295 APA_Coordinate_X 200;
BA_ "GenSigInvalidValue" SG_ 1295 APA_Coordinate_X "2047";
BA_ "GenSigStartValue" SG_ 1295 APA_Coordinate_X 2047;
BA_ "GenSigCycleTime" SG_ 723 ACC_AEBTargetLatRelSpeed_for_SRS 40;
BA_ "GenSigCycleTime" SG_ 723 ACC_AEBTargetLatRange_for_SRS 40;
BA_ "GenSigStartValue" SG_ 723 ACC_AEBTargetLatRange_for_SRS 500;
BA_ "GenSigCycleTime" SG_ 723 ACC_CRCCheckr_282 40;
BA_ "GenSigCycleTime" SG_ 723 ACC_RollingCounter_282 40;
BA_ "GenSigCycleTime" SG_ 723 ACC_AEBTargetProb_for_SRS 40;
BA_ "GenSigCycleTime" SG_ 723 ACC_AEBTargetType_for_SRS 40;
BA_ "GenSigStartValue" SG_ 723 ACC_AEBTargetType_for_SRS 15;
BA_ "GenSigCycleTime" SG_ 723 ACC_AEBTargetTTC_for_SRS 40;
BA_ "GenSigInvalidValue" SG_ 723 ACC_AEBTargetTTC_for_SRS "254";
BA_ "GenSigStartValue" SG_ 723 ACC_AEBTargetTTC_for_SRS 251;
BA_ "GenSigCycleTime" SG_ 723 ACC_AEBTargetRelSpeed_for_SRS 40;
BA_ "GenSigStartValue" SG_ 723 ACC_AEBTargetRelSpeed_for_SRS 250;
BA_ "GenSigCycleTime" SG_ 723 ACC_AEBTargetLngRange_for_SRS 40;
BA_ "GenSigStartValue" SG_ 723 ACC_AEBTargetLngRange_for_SRS 500;
BA_ "GenSigCycleTime" SG_ 723 ACC_AEBActive_for_SRS 40;
BA_ "GenSigCycleTime" SG_ 723 ACC_AEBStatus_for_SRS 40;
BA_ "GenSigInvalidValue" SG_ 723 ACC_AEBStatus_for_SRS "3";
BA_ "GenSigCycleTime" SG_ 713 HU_Ylevel 40;
BA_ "GenSigInvalidValue" SG_ 713 HU_Ylevel "65535";
BA_ "GenSigCycleTime" SG_ 713 HU_Xlevel 40;
BA_ "GenSigInvalidValue" SG_ 713 HU_Xlevel "65535";
BA_ "GenSigCycleTime" SG_ 881 PCU_DrvMod2 100;
BA_ "GenSigCycleTime" SG_ 796 PCU_eDTEDisp 100;
BA_ "GenSigInvalidValue" SG_ 796 PCU_eDTEDisp "2047";
BA_ "GenSigCycleTime" SG_ 796 PCU_VcuRdySts 100;
BA_ "GenSigInvalidValue" SG_ 796 PCU_VcuRdySts "NA";
BA_ "GenSigCycleTime" SG_ 266 EPB_ClampForce_Secondary 10;
BA_ "GenSigInvalidValue" SG_ 266 EPB_ClampForce_Secondary "31";
BA_ "GenSigStartValue" SG_ 266 EPB_ClampForce_Secondary 29;
BA_ "GenSigCycleTime" SG_ 266 EPB_EAR_Available 10;
BA_ "GenSigInvalidValue" SG_ 266 EPB_EAR_Available "NA";
BA_ "GenSigCycleTime" SG_ 266 EPB_RollingCounter_10A 10;
BA_ "GenSigCycleTime" SG_ 266 EPB_CRCCheck_10A 10;
BA_ "GenSigCycleTime" SG_ 266 EPB_SwitchPositionValid 10;
BA_ "GenSigInvalidValue" SG_ 266 EPB_SwitchPositionValid "1";
BA_ "GenSigStartValue" SG_ 266 EPB_SwitchPositionValid 1;
BA_ "GenSigCycleTime" SG_ 266 EPB_SwitchPosition 10;
BA_ "GenSigInvalidValue" SG_ 266 EPB_SwitchPosition "3";
BA_ "GenSigCycleTime" SG_ 266 EPB_Status 10;
BA_ "GenSigCycleTime" SG_ 266 EPB_FailStatus 10;
BA_ "GenSigCycleTime" SG_ 266 EPB_APArequest_Available 10;
BA_ "GenSigCycleTime" SG_ 266 EPB_AchievedClampForce 10;
BA_ "GenSigInvalidValue" SG_ 266 EPB_AchievedClampForce "31";
BA_ "GenSigStartValue" SG_ 266 EPB_AchievedClampForce 29;
BA_ "GenSigCycleTime" SG_ 81 SRS_CrashOut_Cedr 500;
BA_ "GenSigCycleTime" SG_ 81 SRS_CrashOut_Micro 500;
BA_ "GenSigCycleTime" SG_ 81 SRS_CrashOut_Rear 500;
BA_ "GenSigCycleTime" SG_ 81 SRS_CrashOut_Right 500;
BA_ "GenSigCycleTime" SG_ 81 SRS_CrashOut_Left 500;
BA_ "GenSigCycleTime" SG_ 81 SRS_CrashOut_Front 500;
BA_ "GenSigCycleTime" SG_ 849 AMB_Brightness 100;
BA_ "GenSigCycleTime" SG_ 849 FW_Brightness 100;
BA_ "GenSigCycleTime" SG_ 380 EMS_RollingCounter_1B7 10;
BA_ "GenSigCycleTime" SG_ 380 EMS_RngMod_trqCrSSetMinAvl 10;
BA_ "GenSigCycleTime" SG_ 380 EMS_RngMod_trqCrSSetMaxAvl 10;
BA_ "GenSigCycleTime" SG_ 380 EMS_RngMod_trqCrSLeadMinAvl 10;
BA_ "GenSigCycleTime" SG_ 380 EMS_RngMod_trqCrSLeadMaxAvl 10;
BA_ "GenSigCycleTime" SG_ 380 EMS_EngIdleTqFlywhMin 10;
BA_ "GenSigCycleTime" SG_ 380 EMS_CRCCheck_1B7 10;
BA_ "GenSigCycleTime" SG_ 380 EMS_RollingCounter_194 10;
BA_ "GenSigCycleTime" SG_ 380 EMS_IGNKL15Posn 10;
BA_ "GenSigCycleTime" SG_ 380 EMS_IdleCtrlSts 10;
BA_ "GenSigCycleTime" SG_ 380 EMS_EngTqFlywhFailr 10;
BA_ "GenSigCycleTime" SG_ 380 EMS_EngTqFlywh 10;
BA_ "GenSigInvalidValue" SG_ 380 EMS_EngTqFlywh "65535";
BA_ "GenSigStartValue" SG_ 380 EMS_EngTqFlywh 17500;
BA_ "GenSigCycleTime" SG_ 380 EMS_EngSts 10;
BA_ "GenSigCycleTime" SG_ 380 EMS_EngStrtSuccess 10;
BA_ "GenSigCycleTime" SG_ 380 EMS_EngStopInhb 10;
BA_ "GenSigCycleTime" SG_ 380 EMS_EngSpdErr 10;
BA_ "GenSigCycleTime" SG_ 380 EMS_EngSpd 10;
BA_ "GenSigInvalidValue" SG_ 380 EMS_EngSpd "65535";
BA_ "GenSigCycleTime" SG_ 380 EMS_EngRunReq 10;
BA_ "GenSigCycleTime" SG_ 380 EMS_EngFuPumpSts 10;
BA_ "GenSigCycleTime" SG_ 380 EMS_EngFuCutOff 10;
BA_ "GenSigCycleTime" SG_ 380 EMS_CRCCheck_194 10;
BA_ "GenSigCycleTime" SG_ 380 EMS_RollingCounter_186 10;
BA_ "GenSigCycleTime" SG_ 380 EMS_RngMod_trqCrSLimtSts 10;
BA_ "GenSigCycleTime" SG_ 380 EMS_RngMod_trqCrSLeadMin 10;
BA_ "GenSigCycleTime" SG_ 380 EMS_InterCoolerMotLopPumpSpdReq 10;
BA_ "GenSigCycleTime" SG_ 380 EMS_IdleSpdRef 10;
BA_ "GenSigStartValue" SG_ 380 EMS_IdleSpdRef 800;
BA_ "GenSigCycleTime" SG_ 380 EMS_EngTqFric 10;
BA_ "GenSigCycleTime" SG_ 380 EMS_EngIdleTqFlywh 10;
BA_ "GenSigCycleTime" SG_ 380 EMS_CRCCheck_186 10;
BA_ "GenSigCycleTime" SG_ 378 IBCU_TankTurn_Status 10;
BA_ "GenSigCycleTime" SG_ 378 ESP_VehicleSpeedValid 10;
BA_ "GenSigInvalidValue" SG_ 378 ESP_VehicleSpeedValid "1";
BA_ "GenSigCycleTime" SG_ 378 ESP_VehicleSpeed 10;
BA_ "GenSigInvalidValue" SG_ 378 ESP_VehicleSpeed "8191";
BA_ "GenSigCycleTime" SG_ 378 ESP_TCSFailStatus 10;
BA_ "GenSigCycleTime" SG_ 378 ESP_RollingCounter_1DF 10;
BA_ "GenSigCycleTime" SG_ 378 ESP_RollingCounter_187 10;
BA_ "GenSigCycleTime" SG_ 378 ESP_pMcVirtual_Q 10;
BA_ "GenSigCycleTime" SG_ 378 ESP_pMcVirtual 10;
BA_ "GenSigCycleTime" SG_ 378 ESP_MbRegenTarWhlRearQlfr 10;
BA_ "GenSigCycleTime" SG_ 378 ESP_MbRegenTarWhlRear 10;
BA_ "GenSigCycleTime" SG_ 378 ESP_MbRegenTarWhlFrontQlfr 10;
BA_ "GenSigCycleTime" SG_ 378 ESP_MbRegenTarWhlFront 10;
BA_ "GenSigCycleTime" SG_ 378 ESP_ESPFunctionStatus 10;
BA_ "GenSigStartValue" SG_ 378 ESP_ESPFunctionStatus 1;
BA_ "GenSigCycleTime" SG_ 378 ESP_ESPActiveStatus 10;
BA_ "GenSigCycleTime" SG_ 378 ESP_EngTorqIncRearActive 10;
BA_ "GenSigCycleTime" SG_ 378 ESP_EngTorqIncFrontActive 10;
BA_ "GenSigCycleTime" SG_ 378 ESP_EngTorqDecActive 10;
BA_ "GenSigCycleTime" SG_ 378 ESP_CRCCheck_1DF 10;
BA_ "GenSigCycleTime" SG_ 378 ESP_CRCCheck_187 10;
BA_ "GenSigCycleTime" SG_ 378 ESP_ABSFailStatus 10;
BA_ "GenSigCycleTime" SG_ 378 ESP_ABSActiveStatus 10;
BA_ "GenSigCycleTime" SG_ 670 LCDAL_RCWVideoEnableStatus 50;
BA_ "GenSigCycleTime" SG_ 670 ADS_FRC_FCTBStatus 50;
BA_ "GenSigInvalidValue" SG_ 670 ADS_FRC_FCTBStatus "3";
BA_ "GenSigCycleTime" SG_ 670 ADS_FRC_FCTAEnable 50;
BA_ "GenSigStartValue" SG_ 670 ADS_FRC_FCTAEnable 1;
BA_ "GenSigCycleTime" SG_ 670 LCDAR_RollingCounter_29E 50;
BA_ "GenSigCycleTime" SG_ 670 ADS_FRC_SystemStatus 50;
BA_ "GenSigInvalidValue" SG_ 670 ADS_FRC_SystemStatus "7";
BA_ "GenSigStartValue" SG_ 670 ADS_FRC_SystemStatus 1;
BA_ "GenSigCycleTime" SG_ 670 ADS_FLC_SystemStatus 50;
BA_ "GenSigInvalidValue" SG_ 670 ADS_FLC_SystemStatus "7";
BA_ "GenSigStartValue" SG_ 670 ADS_FLC_SystemStatus 1;
BA_ "GenSigCycleTime" SG_ 670 ADS_FRC_FCTARStatus 50;
BA_ "GenSigInvalidValue" SG_ 670 ADS_FRC_FCTARStatus "3";
BA_ "GenSigCycleTime" SG_ 670 ADS_FRC_Right_FCTARAlert 50;
BA_ "GenSigCycleTime" SG_ 670 ADS_FRC_Left_FCTALAlert 50;
BA_ "GenSigCycleTime" SG_ 670 ADS_FRC_FCTBActive 50;
BA_ "GenSigInvalidValue" SG_ 670 ADS_FRC_FCTBActive "0";
BA_ "GenSigCycleTime" SG_ 670 ADS_FRC_FCTBTargetDeceleration 50;
BA_ "GenSigStartValue" SG_ 670 ADS_FRC_FCTBTargetDeceleration 32000;
BA_ "GenSigCycleTime" SG_ 670 ADS_FRC_FCTBEnable 50;
BA_ "GenSigStartValue" SG_ 670 ADS_FRC_FCTBEnable 1;
BA_ "GenSigCycleTime" SG_ 685 LCDAL_CRCCheck_2AD 50;
BA_ "GenSigCycleTime" SG_ 685 LCDAL_RollingCounter_2AD 50;
BA_ "GenSigCycleTime" SG_ 685 LCDAL_CRCCheck_300 50;
BA_ "GenSigCycleTime" SG_ 685 LCDAL_RollingCounter_300 50;
BA_ "GenSigCycleTime" SG_ 685 LCDAL_CRCCheck_2F7 50;
BA_ "GenSigCycleTime" SG_ 685 LCDAL_RollingCounter_2F7 50;
BA_ "GenSigCycleTime" SG_ 685 LCDAL_CRCCheck_2EF 50;
BA_ "GenSigCycleTime" SG_ 685 LCDAL_RollingCounter_2EF 50;
BA_ "GenSigCycleTime" SG_ 685 LCDAL_CRCCheck_2AE 50;
BA_ "GenSigCycleTime" SG_ 685 LCDAL_RollingCounter_2AE 50;
BA_ "GenSigCycleTime" SG_ 685 LCDAL_Right_SEAAlert 50;
BA_ "GenSigCycleTime" SG_ 685 LCDAL_Right_RCWAlert 50;
BA_ "GenSigCycleTime" SG_ 685 LCDAL_SEAStatus 50;
BA_ "GenSigInvalidValue" SG_ 685 LCDAL_SEAStatus "3";
BA_ "GenSigCycleTime" SG_ 685 LCDAL_SEAAlert 50;
BA_ "GenSigCycleTime" SG_ 685 LCDAL_SEAEnableStatus 50;
BA_ "GenSigCycleTime" SG_ 685 LCDAL_RCWStatus 50;
BA_ "GenSigInvalidValue" SG_ 685 LCDAL_RCWStatus "3";
BA_ "GenSigCycleTime" SG_ 685 LCDAL_RCWAlert 50;
BA_ "GenSigCycleTime" SG_ 685 LCDAL_RCWEnableStatus 50;
BA_ "GenSigCycleTime" SG_ 685 LCDAL_SystemStatus 50;
BA_ "GenSigInvalidValue" SG_ 685 LCDAL_SystemStatus "7";
BA_ "GenSigStartValue" SG_ 685 LCDAL_SystemStatus 1;
BA_ "GenSigCycleTime" SG_ 879 ADS_NDAStatus 100;
BA_ "GenSigCycleTime" SG_ 879 ADS_NDATextInfo 100;
BA_ "GenSigCycleTime" SG_ 879 ADS_NIDOutDis 100;
BA_ "GenSigInvalidValue" SG_ 879 ADS_NIDOutDis "255";
BA_ "GenSigStartValue" SG_ 879 ADS_NIDOutDis 255;
BA_ "GenSigCycleTime" SG_ 879 LAS_OverspeedWarningRatioOffset_ 100;
BA_ "GenSigStartValue" SG_ 879 LAS_OverspeedWarningRatioOffset_ 47;
BA_ "SystemSignalLongSymbol" SG_ 879 LAS_OverspeedWarningRatioOffset_ "LAS_OverspeedWarningRatioOffset_EU";
BA_ "GenSigCycleTime" SG_ 879 LAS_TSRSpeedLimitChangeSoundEnSt 100;
BA_ "GenSigInvalidValue" SG_ 879 LAS_TSRSpeedLimitChangeSoundEnSt "0";
BA_ "GenSigCycleTime" SG_ 879 LAS_TSRSpeedLimitStatus 100;
BA_ "GenSigCycleTime" SG_ 879 LAS_TSRNavCountryCode 100;
BA_ "GenSigInvalidValue" SG_ 879 LAS_TSRNavCountryCode "0";
BA_ "GenSigCycleTime" SG_ 879 RADS_DynamicButton 100;
BA_ "GenSigCycleTime" SG_ 879 LAS_OverspeedWarningRatioOffset 100;
BA_ "GenSigStartValue" SG_ 879 LAS_OverspeedWarningRatioOffset 10;
BA_ "GenSigCycleTime" SG_ 879 APA_RPA_Notice 100;
BA_ "GenSigCycleTime" SG_ 879 APA_FunRecomReq 100;
BA_ "GenSigCycleTime" SG_ 879 ADS_RoadLngRange 100;
BA_ "GenSigCycleTime" SG_ 879 ACC_RollingCounter_36F 100;
BA_ "GenSigCycleTime" SG_ 879 ACC_CRCCheck_36F 100;
BA_ "GenSigCycleTime" SG_ 879 ADS_TunnelStatus 100;
BA_ "GenSigCycleTime" SG_ 879 ADS_TunnelDis 100;
BA_ "GenSigCycleTime" SG_ 879 ADS_RampStatus 100;
BA_ "GenSigCycleTime" SG_ 879 ADS_PathThroughRamp 100;
BA_ "GenSigCycleTime" SG_ 879 ADS_RampSide 100;
BA_ "GenSigCycleTime" SG_ 879 ADS_DisToRamp 100;
BA_ "GenSigCycleTime" SG_ 879 ADS_PathShowLngRange 100;
BA_ "GenSigCycleTime" SG_ 879 ADS_RoadMergeLatRange 100;
BA_ "GenSigCycleTime" SG_ 879 ADS_AutoDriveStateDisplay 100;
BA_ "GenSigCycleTime" SG_ 879 ADS_PathShow_Status 100;
BA_ "GenSigCycleTime" SG_ 879 ADS_PathShow_C3 100;
BA_ "GenSigCycleTime" SG_ 879 ADS_PathShow_C2 100;
BA_ "GenSigCycleTime" SG_ 879 ADS_PathShow_C1 100;
BA_ "GenSigCycleTime" SG_ 879 ACC_TakeoverReqAtIPFail 100;
BA_ "GenSigCycleTime" SG_ 879 ADS_TSRHostNextSpdLimitDist 100;
BA_ "GenSigCycleTime" SG_ 879 ADS_TSRHostNextSpdLimit 100;
BA_ "GenSigCycleTime" SG_ 1535 BCM_RemoteReadyReq 100;
BA_ "GenSigInvalidValue" SG_ 1535 BCM_RemoteReadyReq "3";
BA_ "GenSigCycleTime" SG_ 1785 ADS_DTC2_Status 500;
BA_ "GenSigCycleTime" SG_ 1785 ADS_DTC2_LowByte 500;
BA_ "GenSigCycleTime" SG_ 1785 ADS_DTC2_MiddByte 500;
BA_ "GenSigCycleTime" SG_ 1785 ADS_DTC2_HighByte 500;
BA_ "GenSigCycleTime" SG_ 1785 ADS_DTC1_Status 500;
BA_ "GenSigCycleTime" SG_ 1785 ADS_DTC1_LowByte 500;
BA_ "GenSigCycleTime" SG_ 1785 ADS_DTC1_MiddByte 500;
BA_ "GenSigCycleTime" SG_ 1785 ADS_DTC1_HighByte 500;
BA_ "GenSigCycleTime" SG_ 349 ESP_IMUCalibrated 20;
BA_ "GenSigCycleTime" SG_ 349 ESP_YawRateValid 20;
BA_ "GenSigCycleTime" SG_ 349 ESP_LatAccelValid 20;
BA_ "GenSigCycleTime" SG_ 349 ESP_LongAccelValid 20;
BA_ "GenSigCycleTime" SG_ 349 ESP_YawRate 20;
BA_ "GenSigInvalidValue" SG_ 349 ESP_YawRate "16383";
BA_ "GenSigCycleTime" SG_ 349 ESP_RollingCounter_278 20;
BA_ "GenSigCycleTime" SG_ 349 ESP_LongAccel 20;
BA_ "GenSigInvalidValue" SG_ 349 ESP_LongAccel "1023";
BA_ "GenSigCycleTime" SG_ 349 ESP_LatAccel 20;
BA_ "GenSigInvalidValue" SG_ 349 ESP_LatAccel "255";
BA_ "GenSigCycleTime" SG_ 349 ESP_CRCCheck_278 20;
BA_ "GenSigCycleTime" SG_ 271 IBCU_RollingCounter_1CB 20;
BA_ "GenSigCycleTime" SG_ 271 IBCU_sOutputRodAct_Q 20;
BA_ "GenSigCycleTime" SG_ 271 IBCU_sOutputRodAct 20;
VAL_ 947 BCM_RightRearDoorHandleStatus 0 "无效" 1 "展开位置" 2 "收回位置" 3 "预留" ;
VAL_ 947 BCM_PassengeDoorHandleStatus 0 "无效" 1 "展开位置" 2 "收回位置" 3 "预留" ;
VAL_ 947 LCM_ReverseLightSts 0 "OFF" 1 "ON" 2 "Not used" 3 "Error" ;
VAL_ 947 BCM_ReverseLampError 0 "无故障" 1 "有故障" ;
VAL_ 947 BCM_CHMLampError 0 "无故障" 1 "有故障" ;
VAL_ 947 BCM_BrakeLampError 0 "无故障" 1 "有故障" ;
VAL_ 947 BCM_RightRearFoglampError 0 "无故障" 1 "有故障" ;
VAL_ 947 BCM_LeftRearFoglampError 0 "无故障" 1 "有故障" ;
VAL_ 947 BCM_RearPositionLampError 0 "无故障" 1 "有故障" ;
VAL_ 947 BCM_RearFoglampStatus 0 "OFF" 1 "ON" 2 "Not used" 3 "Error" ;
VAL_ 957 HU_Llong_Tunnel_Len 0 " 0~20000m" 2001 "Out of Range" 2002 "reserved" 2047 "unknown" ;
VAL_ 957 HU_Long_Ramp_Side 0 "Unknown" 1 "道路左边" 2 "道路右边" 3 "无效" ;
VAL_ 957 HU_Long_Ramp_Dis 0 " 0~20000m" 2001 "Out of Range" 2002 "reserved" 2047 "unknown" ;
VAL_ 957 HU_ParallelRoadSide 0 "Unknown" 1 "道路左边" 2 "道路右边" 3 "Invalid" ;
VAL_ 957 HU_ParallelRoadInfo 0 "Unknown" 1 "本车经过平行路" 2 "本车不经过平行路" 3 "Invalid" ;
VAL_ 957 HU_EnterParallelRoadInfo 0 "Unknown" 1 "平行路进口" 2 "平行路中" 3 "平行路出口" ;
VAL_ 957 HU_ParallelRoadDistance 0 " 0~2000m" 201 "Out of Range" 202 "reserved" 255 "unknown" ;
VAL_ 957 HU_AsistantSysteSwitch 0 " inactive " 1 "关闭" 2 "开启" ;
VAL_ 957 HU_ALCModeSelection 0 "Inactive
0x1=ALC
0x2=IRLC
0x3==UDLC" ;
VAL_ 957 HU_SlotUserSelected 0 "No selected" 1 "Left Slot 1" 2 "Left Slot 2" 3 "Right Slot 1" 4 "Right Slot 2" 5 "Left Park Out" 6 "Right ParkOut" 7 "Left Slot 3" 8 "Left Slot 4" 9 "Right Slot 3" 10 "Right Slot 4" 11 "Reserved" ;
VAL_ 957 HU_SentryModeSt 0 "off" 1 "哨兵模式准备" 2 "哨兵模式开启中" 3 "主动哨兵模式开启" 4 "主动哨兵模式激活" 5 "充电哨兵模式激活" ;
VAL_ 957 HU_AutoHeadLiSet 0 "inactive" 1 "off
0x2=位置灯
0x3=近光灯
0x4=自动大灯
0x5~0x7=Reserve" ;
VAL_ 957 HU_RADSSwitch 0 "Invalid" 1 "On" 2 "Off" 3 "Suspend" ;
VAL_ 957 HU_LaneChangeReq 0 "NoRequest" 1 "LaneChangeToLeft" 2 " LaneChangeToRight" 3 "Reserved" ;
VAL_ 957 HU_UDLCEnable 0 "Inactive" 1 "OFF" 2 "ON" 3 "Reserved" ;
VAL_ 957 HU_ESSEnable 0 "Inactive" 1 "OFF" 2 "ON" 3 "Reserved" ;
VAL_ 957 HU_ELKEnable 0 "Inactive" 1 "OFF" 2 "ON" 3 "Reserved" ;
VAL_ 957 HU_TLAEnable 0 "Inactive" 1 "OFF" 2 "ON" 3 "Reserved" ;
VAL_ 957 HU_LAEBEnable 0 "Inactive" 1 "Off" 2 "On" 3 "Reserved" ;
VAL_ 957 HU_APAModeSelect 0 "Parallel Mode（平行）" 1 "Cross Mode（垂直）" 2 " POC Mode （泊出）" 3 "Invalid" 4 "Echelon Mode（斜列式）" 5 "function  off" 6 "default" 7 "No selection" ;
VAL_ 964 HU_Indication_BusLane_Dis 0 " 0~2000m" 201 "Out of Range" 202 "reserved" 255 "unknown" ;
VAL_ 964 HU_Indication_PedestrianCro_Dis 0 " 0~2000m" 201 "Out of Range" 202 "reserved" 255 "unknown" ;
VAL_ 964 HU_Indication_MainRoadPri_Dis 0 " 0~2000m" 201 "Out of Range" 202 "reserved" 255 "unknown" ;
VAL_ 964 HU_Indication_Walk_Dis 0 " 0~2000m" 201 "Out of Range" 202 "reserved" 255 "unknown" ;
VAL_ 964 HU_Indication_OneWay_Dis 0 " 0~2000m" 201 "Out of Range" 202 "reserved" 255 "unknown" ;
VAL_ 964 HU_Prohibitory_GiveWayOncom_Dis 0 " 0~2000m" 201 "Out of Range" 202 "reserved" 255 "unknown" ;
VAL_ 964 HU_Prohibitory_Honking_Dis 0 " 0~2000m" 201 "Out of Range" 202 "reserved" 255 "unknown" ;
VAL_ 964 HU_Prohibitory_Enter_Dis 0 " 0~2000m" 201 "Out of Range" 202 "reserved" 255 "unknown" ;
VAL_ 964 HU_Prohibitory_StopToGiveWay_Dis 0 " 0~2000m" 201 "Out of Range" 202 "reserved" 255 "unknown" ;
VAL_ 964 HU_Indication_BusLane 0 "Valid" 1 "invalid" ;
VAL_ 964 HU_Indication_PedestrianCrossing 0 "Valid" 1 "invalid" ;
VAL_ 964 HU_Indication_MainRoadPriority 0 "Valid" 1 "invalid" ;
VAL_ 964 HU_Indication_Walk 0 "Valid" 1 "invalid" ;
VAL_ 964 HU_Indication_OneWay 0 "Valid" 1 "invalid" ;
VAL_ 964 HU_Prohibitory_GiveWayToOncoming 0 "Valid" 1 "invalid" ;
VAL_ 964 HU_Prohibitory_Honking 0 "Valid" 1 "invalid" ;
VAL_ 964 HU_Prohibitory_Enter 0 "Valid" 1 "invalid" ;
VAL_ 964 HU_Prohibitory_StopToGiveWay 0 "Valid" 1 "invalid" ;
VAL_ 964 HU_Prohibitory_SpeedLimit 0 "Valid" 1 "invalid" ;
VAL_ 964 HU_Prohibitory_VehParkLongTime 0 "Valid" 1 "invalid" ;
VAL_ 964 HU_Prohibitory_VehicleParking 0 "Valid" 1 "invalid" ;
VAL_ 964 HU_Prohibitory_Overtake 0 "Valid" 1 "invalid" ;
VAL_ 964 HU_Prohibitory_Uturn 0 "Valid" 1 "invalid" ;
VAL_ 964 HU_Prohibitory_Straight 0 "Valid" 1 "invalid" ;
VAL_ 964 HU_Prohibitory_TurnRight 0 "Valid" 1 "invalid" ;
VAL_ 964 HU_Prohibitory_MotorVehicles 0 "Valid" 1 "invalid" ;
VAL_ 964 HU_Prohibitory_DriveInto 0 "Valid" 1 "invalid" ;
VAL_ 964 HU_Warning_RoadWorks 0 "Valid" 1 "invalid" ;
VAL_ 964 HU_Warning_Slow 0 "Valid" 1 "invalid" ;
VAL_ 964 HU_Warning_Tunnel 0 "Valid" 1 "invalid" ;
VAL_ 964 HU_Warning_Slip 0 "Valid" 1 "invalid" ;
VAL_ 964 HU_Warning_Pedestrian 0 "Valid" 1 "invalid" ;
VAL_ 964 HU_Warning_ContinuousDetours 0 "Valid" 1 "invalid" ;
VAL_ 964 HU_Warning_ReverseCurve 0 "Valid(存在标志)
0x1=invalid(不存在标志)" ;
VAL_ 964 HU_BSDLCAMode 0 "inactive" 1 "Light" 2 "Light+Vibration" 3 "Light+Voice" 4 "OFF" 5 "Reserved" 6 "Reserved" 7 "Invalid" ;
VAL_ 964 HU_CrossingAngle4 0 "0°" 1 "1.417°" 2 "2*1.417°" 126 "126*1.417°" 127 " -0°" 128 "-126*1.417°" 129 "-125*1.417°" 253 "-1.417°" 254 "Unknown" 255 "reserved" ;
VAL_ 964 HU_CrossingAngle3 0 "0°" 1 "1.417°" 2 "2*1.417°" 126 "126*1.417°" 127 " -0°" 128 "-126*1.417°" 129 "-125*1.417°" 253 "-1.417°" 254 "Unknown" 255 "reserved" ;
VAL_ 964 HU_CrossingAngle2 0 "0°" 1 "1.417°" 2 "2*1.417°" 126 "126*1.417°" 127 " -0°" 128 "-126*1.417°" 129 "-125*1.417°" 253 "-1.417°" 254 "Unknown" 255 "reserved" ;
VAL_ 964 HU_CrossingAngle1 0 "0°" 1 "1.417°" 2 "2*1.417°" 126 "126*1.417°" 127 " -0°" 128 "-126*1.417°" 129 "-125*1.417°" 253 "-1.417°" 254 "Unknown" 255 "reserved" ;
VAL_ 964 HU_EnterRoundaboutInfo 0 "Unknown" 1 "环岛进口" 2 "环岛中" 3 "环岛出口" ;
VAL_ 964 HU_RoundaboutDistance 0 " 0~500m" 51 "Out of Range" 52 "reserved" 63 "unknown" ;
VAL_ 964 HU_EnterCrossingInfo 0 "Unknown" 1 "路口进口" 2 "reserved" 3 "reserved" ;
VAL_ 964 HU_CrossingDistance 0 " 0~500m" 51 "Out of Range" 52 "reserved" 63 "unknown" ;
VAL_ 964 HU_MapMatchStatus 0 "Successl" 1 "Fail" 2 "保留" 3 "无效" ;
VAL_ 964 HU_MapDataUpdateStatus 0 "未更新" 1 "1个月内更新" 2 "3个月内更新" 3 "6个月内更新" 4 "1年内更新" 5 " reserved" 7 "Invalid" ;
VAL_ 964 HU_SlopeGradient_300m 1023 " unknown" ;
VAL_ 964 HU_RoadCurvature_600m 0 " -0.16192 ~ -0.00001，负数代表向左的弯道曲率" 8191 " 0，代表曲率为0的直道" 512 " 0.00001 ~ 0.16192，正数代表向右的弯道曲率" 5631 " unknown" ;
VAL_ 964 HU_RoadCurvature_400m 0 " -0.16192 ~ -0.00001，负数代表向左的弯道曲率" 8191 " 0，代表曲率为0的直道" 512 " 0.00001 ~ 0.16192，正数代表向右的弯道曲率" 5375 " unknown" ;
VAL_ 964 HU_RoadCurvature_300m 0 " -0.16192 ~ -0.00001，负数代表向左的弯道曲率" 8191 " 0，代表曲率为0的直道" 512 " 0.00001 ~ 0.16192，正数代表向右的弯道曲率" 5119 " unknown" ;
VAL_ 964 HU_RoadCurvature_100m 0 " -0.16192 ~ -0.00001，负数代表向左的弯道曲率" 8191 " 0，代表曲率为0的直道" 512 " 0.00001 ~ 0.16192，正数代表向右的弯道曲率" 4863 " unknown" ;
VAL_ 964 HU_RoadCurvature_90m 0 " -0.16192 ~ -0.00001，负数代表向左的弯道曲率" 8191 " 0，代表曲率为0的直道" 512 " 0.00001 ~ 0.16192，正数代表向右的弯道曲率" 4607 " unknown" ;
VAL_ 964 HU_RoadCurvature_80m 0 " -0.16192 ~ -0.00001，负数代表向左的弯道曲率" 8191 " 0，代表曲率为0的直道" 512 " 0.00001 ~ 0.16192，正数代表向右的弯道曲率" 4351 " unknown" ;
VAL_ 964 HU_RoadCurvature_70m 0 " -0.16192 ~ -0.00001，负数代表向左的弯道曲率" 8191 " 0，代表曲率为0的直道" 512 " 0.00001 ~ 0.16192，正数代表向右的弯道曲率" 2559 " unknown" ;
VAL_ 964 HU_RoadCurvature_60m 0 " -0.16192 ~ -0.00001，负数代表向左的弯道曲率" 8191 " 0，代表曲率为0的直道" 512 " 0.00001 ~ 0.16192，正数代表向右的弯道曲率" 2303 " unknown" ;
VAL_ 964 HU_RoadCurvature_50m 0 " -0.16192 ~ -0.00001，负数代表向左的弯道曲率" 8191 " 0，代表曲率为0的直道" 512 " 0.00001 ~ 0.16192，正数代表向右的弯道曲率" 2047 " unknown" ;
VAL_ 964 HU_RoadCurvature_40m 0 " -0.16192 ~ -0.00001，负数代表向左的弯道曲率" 8191 " 0，代表曲率为0的直道" 512 " 0.00001 ~ 0.16192，正数代表向右的弯道曲率" 1791 " unknown" ;
VAL_ 964 HU_RoadCurvature_30m 0 " -0.16192 ~ -0.00001，负数代表向左的弯道曲率" 8191 " 0，代表曲率为0的直道" 512 " 0.00001 ~ 0.16192，正数代表向右的弯道曲率" 1535 " unknown" ;
VAL_ 964 HU_RoadCurvature_20m 0 " -0.16192 ~ -0.00001，负数代表向左的弯道曲率" 8191 " 0，代表曲率为0的直道" 512 " 0.00001 ~ 0.16192，正数代表向右的弯道曲率" 1279 " unknown" ;
VAL_ 964 HU_RoadCurvature_10m 0 " -0.16192 ~ -0.00001，负数代表向左的弯道曲率" 8191 " 0，代表曲率为0的直道" 512 " 0.00001 ~ 0.16192，正数代表向右的弯道曲率" 1023 " unknown" ;
VAL_ 964 HU_Road_TrafficFlow 0 "unknown" 1 "畅通" 2 "缓行" 3 " 拥堵，0x4=严重拥堵，0x5=无交通流,0x6=reserved.0x7=invalid" ;
VAL_ 964 HU_Lane_Changtype 0 "NO change，0x1=Merge" 2 "Separate，
0x3=invalid" ;
VAL_ 964 HU_To_NumchangeOfLanes_Dist 0 " 0~600m" 61 "Out of Range" 62 "reserved" 63 "unknown" ;
VAL_ 964 HU_To_Branch_Dis 0 " 0~600m" 61 "Out of Range" 62 "reserved" 63 "unknown" ;
VAL_ 964 HU_To_TrafficAccident_Dis 0 " 0~600m" 61 "Out of Range" 62 "reserved" 63 "unknown" ;
VAL_ 964 HU_TrafficAccident_Info 0 "无交通事故" 1 "有交通事故
0x2=预留
0x3=invalid" ;
VAL_ 964 HU_To_Construction_Dis 0 " 0~600m" 61 "Out of Range" 62 "reserved" 63 "unknown" ;
VAL_ 964 HU_Construction_Info 0 "路径无施工区" 1 "路径有施工区" 2 "预留
0x3=invalid" ;
VAL_ 964 HU_TollDis 0 " 0~600m" 61 "Out of Range" 62 "reserved" 63 "unknown" ;
VAL_ 964 HU_TollInfo 0 "=路径无收费站" 1 "路径有收费站" 2 "预留" 3 "invalid" ;
VAL_ 964 HU_FallingRockDi 0 " 0~600m" 61 "Out of Range" 62 "reserved" 63 "unknown" ;
VAL_ 964 HU_FallingRockInfo 0 "=路径无落石" 1 "路径有落石" 2 "预留" 3 "invalid" ;
VAL_ 964 HU_LaneCnt 0 "unknown,0x1-0x5=当前道路车道数量，0x6=大于等于6,,0x7=当前道路单项行驶且车辆逆行" ;
VAL_ 964 HU_ForwardRoadType 0 "
0x0=Road Type Unknown= Small road, Walking Street" 1 "Road Type Class 1= Secondary Roads" 2 "Road Type Class 2= Mainly Road in City" 3 "Road Type Class 3= Mainly Road in City, Normal Province Road, Mainly street" 4 "Road Type Class 4= Province Road, Mainly Road " 5 "Road Type Class 5= Highway, National Road, Speed road" 6 "Reserved

2.搭载ADAS=
0x0=未知" 1 "城市主要道路" 2 "城市快速路" 3 "省道，县道" 4 "国道" 5 "高速路" 6 "次要道路，普通道路，乡公路，县乡内部路" 7 "预留" ;
VAL_ 964 HU_RampSide 0 "Unknown" 1 "道路左边" 2 "道路右边" 3 "直线匝道" ;
VAL_ 964 HU_NavGuiganceStatus 0 "没有导航引导路径" 1 "有导航引导路径" 2 "导航重算中" 3 "无效" ;
VAL_ 964 HU_SlopeDistance 0 " 0~600m" 61 "Out of Range" 62 "reserved" 63 "unknown" ;
VAL_ 964 HU_TunnelLength 0 " 0~600m" 61 "Out of Range" 62 "reserved" 63 "unknown" ;
VAL_ 964 HU_RoadCurvatureFar 0 " -0.16192 ~ -0.00001，负数代表向左的弯道曲率" 8191 " 0，代表曲率为0的直道" 512 " 0.00001 ~ 0.16192，正数代表向右的弯道曲率" 1023 " unknown" ;
VAL_ 964 HU_TunnelDistance 0 " 0~600m" 61 "Out of Range" 62 "reserved" 63 "unknown" ;
VAL_ 964 HU_RoadCurvature 0 " -0.16192 ~ -0.00001，负数代表向左的弯道曲率" 8191 " 0，代表曲率为0的直道" 512 " 0.00001 ~ 0.16192，正数代表向右的弯道曲率" 1023 " unknown" ;
VAL_ 964 HU_EnterSlopeInfo 0 "unknown" 1 "坡道入口" 2 "坡道中" 3 "坡道出口" ;
VAL_ 964 HU_EnterTunnelInfo 0 " unknown" 1 "隧道入口" 2 "隧道中" 3 "隧道出口" ;
VAL_ 1021 BCM_AutHeadLiSts 0 "inactive" 1 "off
0x2=位置灯
0x3=近光灯
0x4=自动大灯
0x5~0x7=Reserve" ;
VAL_ 1021 BCM_FrontWindshieldWarmStatus 0 "inactive" 1 "on" 2 "off " 3 "reserved" ;
VAL_ 1021 BCM_DriveMode 0 "Normal" 1 "Eco" 2 "Sport  " 3 "Snow" 4 "Sport+" 5 "Smart" 6 "Race" 7 "Reserved" 15 "Invalid" ;
VAL_ 1021 BCM_PowerManageLevel 0 "Valid" 1 "Level1" 2 " Level2" 3 " Level3" 4 " Level4" 5 "Reserve" 7 "Invalid" ;
VAL_ 1023 BCM_TurnIndicatorRightError 0 "无故障" 1 "有故障" ;
VAL_ 1023 BCM_TurnIndicatorLeftError 0 "无故障" 1 "有故障" ;
VAL_ 1023 BCM_RightFrontFoglampError 0 "无故障" 1 "有故障" ;
VAL_ 1023 BCM_LeftFrontFoglampError 0 "无故障" 1 "有故障" ;
VAL_ 1023 BCM_RightLowBeamError 0 "无故障" 1 "有故障" ;
VAL_ 1023 BCM_LeftLowBeamError 0 "无故障" 1 "有故障" ;
VAL_ 1023 BCM_HighBeamLampError 0 "No error" 1 " error" ;
VAL_ 1023 BCM_AutoHeadlightSts 0 "Not Actived" 1 "Actived" ;
VAL_ 1023 BCM_FrontFoglampStatus 0 "OFF" 1 "ON" 2 "Not used" 3 "Reserved" ;
VAL_ 652 GW_MFS_APA_switch 0 "按键未按下" 1 "按键按下" 2 "假按键" 3 "Error" ;
VAL_ 652 GW_MFS_HODCalibratedStatus 0 "Not Calibrated" 1 "Calibrated" ;
VAL_ 652 GW_MFS_HODLinStatus 0 "no fault" 1 "fault" ;
VAL_ 652 GW_MFS_HODAppStatus 0 "no fault" 1 "fault" ;
VAL_ 652 GW_MFS_HODSenserStatus 0 "no fault" 1 "fault" ;
VAL_ 652 GW_MFS_HODSystemStatus 0 "no fault" 1 "fault" 2 "block" 3 "reserved" ;
VAL_ 652 GW_MFS_handsoffAbilityDetect 0 " hands off" 1 " hands on without takeover ability" 2 " hands on with takeover ability" 3 " unkown" 4 "reserved" ;
VAL_ 652 GW_MFS_handsoffDetectResult 0 "no Touch" 1 "touch" 2 " Grip" 3 "reserved" ;
VAL_ 652 GW_MFS_DiagInfoSW_28C 0 "复位" 1 "变种信息错误" 2 "电源高于16V" 3 "电源低于9V" 4 "reversed" 7 "invalid" ;
VAL_ 652 GW_MFS_IACCenable_switch_signal 0 "按键未按下" 1 "按键按下" 2 "假按键" 3 "Error" ;
VAL_ 652 GW_MFS_LIM_switch_signal 0 "按键未按下" 1 "按键按下" 2 "假按键" 3 "Error" ;
VAL_ 652 GW_MFS_DIST_switch_signal 0 "按键未按下" 1 "按键按下" 2 "假按键" 3 "Error" ;
VAL_ 652 GW_MFS_SETReduce_switch_signal 0 "按键未按下" 1 "按键按下" 2 "假按键" 3 "Error" ;
VAL_ 652 GW_MFS_RESPlus_switch_signal 0 "按键未按下" 1 "按键按下" 2 "假按键" 3 "Error" ;
VAL_ 652 GW_MFS_Cancle_switch_signal 0 "按键未按下" 1 "按键按下" 2 "假按键" 3 "Error" ;
VAL_ 652 GW_MFS_Crusie_switch_signal 0 "按键未按下" 1 "按键按下" 2 "假按键" 3 "Error" ;
VAL_ 652 GW_MFS_DISTReduce_switch_signal 0 "按键未按下" 1 "按键按下" 2 "假按键" 3 "Error" ;
VAL_ 652 GW_MFS_DISTPlus_switch_signal 0 "按键未按下" 1 "按键按下" 2 "假按键" 3 "Error" ;
VAL_ 372 APA_ReqSYNMSG 0 "NoRequest" 1 "请求25C同步报文加1发送" 2 "Reserved" ;
VAL_ 431 TCU_ShiftPostionValid 0 "valid" 1 "invalid" ;
VAL_ 431 TCU_GearShiftPosition 0 "Parking" 1 "Reverse" 2 "Neutral" 3 "D" 4 "D3" 5 "D2" 6 "L" 7 "M/S" 8 "Reserved" 13 " Initial value" 14 " Unreliable" 15 " Invalid" ;
VAL_ 431 TCU_ActualDrivingGearValid 0 "valid" 1 "invalid" ;
VAL_ 431 TCU_ActualDrivingGear 0 "Neutral" 1 "1st gear" 2 "2nd gear" 3 "3rd gear" 4 "4th gear" 5 "5th gear" 6 "6th gear" 7 "7th gear" 8 "8th gear" 9 "Reverse" 10 "Parking" 11 "Reserved" 13 "Reserved" 14 "Reserved" 15 "Invalid" ;
VAL_ 800 GW_ADSSecOCVerifyFailureFlag 0 "Not Failure" 1 "Failure" ;
VAL_ 800 GW_DCANDiagSts 0 "DCAN无诊断报文" 1 "DCAN有诊断报文" ;
VAL_ 800 GW_GatewayFailureFlag 0 "Not Failure" 1 "Failure" ;
VAL_ 800 GW_OTAmode 0 "OTAinactive" 1 "OTAmode1-车内升级安全执行中" 2 " OTAmode2-车外升级安全执行中" 3 "OTAmode3-Reserved" 4 "OTAmode4-车内升级非安全执行中" 5 "OTAmode5-车外升级非安全执行中" 6 "OTAmode6-车内升级条件检测中" 7 "OTAmode7-车外升级条件检测中" 8 "Reserved" ;
VAL_ 800 GW_ResetReq 0 "Valid" 1 "THU" 2 " AMP" 3 "ADS/ADC" 4 " FC/LAS" 5 "FR/ACC" 6 "FLR" 7 "FRR" 8 "RLR/LCDAL" 9 "RRR/LCDAR" 10 "LVSM" 11 "INS" 12 "APA" 13 "BCML/BCM" 14 "GW/BCMR" 15 "EMS" 16 "PCU" 17 "BMS" 18 "PEU" 19 "OBC" 20 "TCU" 21 "IPUMP" 22 "ACM" 23 "ESL" 24 "PTS" 25 "ESCL" 26 "TMS/AC" 27 "DKC/RFBT/BLEM" 28 "WLCM" 29 "EPBI" 30 "IBCU" 31 "RBM" 32 "EPS" 33 "EPS2" 34 "DSM" 35 "IP" 36 "SLCM" 37 "HUD" 38 "GPEU" 39 "PDU" 40 "RPEU" 41 "VMC" 43 "DPEU" 44 "NFC-Enter" 45 "PATC" 46 "VMC2" 47 "RCCS" 48 "TRM" 49 "PDCU" 50 "BDCR" 51 "mADC" 52 "EPB" 53 "EVCC" 54 "HLM" 55 "CTMU" 56 "HRM" 57 "RLM" 64 "PSM" 65 "TBOX" 66 "DCDC" 67 "CMS" 68 "ICRF" 69 "ICRR" 70 "EPBi2" 71 "APEU" 72 "C3B" 73 "Reserve" 127 "Invalid" ;
VAL_ 922 LAS_RoadFeature 0 " No Object (无目标)" 1 " Speed Bump  (减速带)" 2 "  Reserved" 3 "  Reserved" 4 "  Reserved" 5 "  Reserved" 6 "  Reserved" 15 " Invalid" ;
VAL_ 922 LAS_RD4LongDistence 0 "0-250m" 251 "Reserved" 255 "Out of Range" ;
VAL_ 922 LAS_RD3LongDistence 0 "0-250m" 251 "Reserved" 255 "Out of Range" ;
VAL_ 922 LAS_RD2LongDistence 0 "0-250m" 251 "Reserved" 255 "Out of Range" ;
VAL_ 922 LAS_RD1LongDistence 0 "0-250m" 251 "Reserved" 255 "Out of Range" ;
VAL_ 922 LAS_RD4RoadInforAvailable 0 " Not Available" 1 " Available Measured" 2 " Predicted" 3 " Predicted close-range outside FOV" ;
VAL_ 922 LAS_RD3RoadInforAvailable 0 " Not Available" 1 " Available Measured" 2 " Predicted" 3 " Predicted close-range outside FOV" ;
VAL_ 922 LAS_RD2RoadInforAvailable 0 " Not Available" 1 " Available Measured" 2 " Predicted" 3 " Predicted close-range outside FOV" ;
VAL_ 922 LAS_RD1RoadInforAvailable 0 " Not Available" 1 " Available Measured" 2 " Predicted" 3 " Predicted close-range outside FOV" ;
VAL_ 922 LAS_TSRRightLaneStatus 0 " off" 1 " fusion mode" 2 " vision only mode" 3 " navigation only mode" 4 " reserved" 5 " reserved" 6 " reserved" 7 " Invalid" ;
VAL_ 922 LAS_TSRLeftLaneStatus 0 " off" 1 " fusion mode" 2 " vision only mode" 3 " navigation only mode" 4 " reserved" 5 " reserved" 6 " reserved" 7 " Invalid" ;
VAL_ 922 LAS_TSRRightLaneSpdLimit 0 "no speed limit detected" 1 "SL5" 2 "SL10" 3 "SL15" 4 "SL20" 5 "SL25" 6 "SL30" 7 "SL35" 8 "SL40" 9 "SL45" 10 "SL50" 11 "SL55" 12 "SL60" 13 "SL65" 14 "SL70" 15 "SL75" 16 "SL80" 17 "SL85" 18 "SL90" 19 "SL95" 20 "SL100" 21 "SL105" 22 "SL110" 23 "SL115" 24 "SL120" 25 "SL125" 26 "SL130" 27 "SL135" 28 "SL140" 29 "SL145" 30 "SL150" 31 "SL155" 32 "SL160" 33 " Reserved" 254 " Unlimited" 255 " SLEND" ;
VAL_ 922 LAS_TSRLeftLaneSpdLimit 0 "no speed limit detected" 1 "SL5" 2 "SL10" 3 "SL15" 4 "SL20" 5 "SL25" 6 "SL30" 7 "SL35" 8 "SL40" 9 "SL45" 10 "SL50" 11 "SL55" 12 "SL60" 13 "SL65" 14 "SL70" 15 "SL75" 16 "SL80" 17 "SL85" 18 "SL90" 19 "SL95" 20 "SL100" 21 "SL105" 22 "SL110" 23 "SL115" 24 "SL120" 25 "SL125" 26 "SL130" 27 "SL135" 28 "SL140" 29 "SL145" 30 "SL150" 31 "SL155" 32 "SL160" 33 " Reserved" 254 " Unlimited" 255 " SLEND" ;
VAL_ 922 LAS_TLAStopLine_HostLane 0 "0-250m" 251 "Reserved" 255 "Out of Range" ;
VAL_ 922 LAS_TLADistance_HostLane 0 "0-250m" 251 "Reserved" 255 "Out of Range" ;
VAL_ 922 LAS_TLACountDownTime_HostLane 0 "no display" 1 "1-120s倒计时" 121 "reserved" 127 "out of range" ;
VAL_ 922 LAS_TSRMandatorySign 0 "no display" 1 "单行路(直行)" 2 "步行" 3 "干路先行" 4 "会车先行" 5 "人行横道" 6 "公交线路专用车道" 7 "机动车行驶" 8 "非机动扯行驶" 9 "靠右侧道路行驶" 10 "reserved" ;
VAL_ 922 LAS_TSRWarningSign 0 "no display" 1 "反向弯路" 2 "连续弯路" 3 "注意行人" 4 "注意儿童" 5 "易滑" 6 "隧道" 7 "慢行" 8 "施工" 9 "向左急转弯" 10 "向右急转弯" 11 "十字交叉路口" 12 "T形交叉右" 13 "T形交叉左" 15 "事故易发生路段" 16 "reserved" ;
VAL_ 922 LAS_TSRProhibitionSign 0 "no display" 1 "禁止通行" 2 "禁止驶入" 3 "禁止机动车通行" 4 "禁止向左转弯" 5 "禁止向右转弯" 6 "禁止直行" 7 "禁止掉头" 8 "禁止超车" 9 "解除禁止超车" 10 "禁止车辆临时或长时停放" 11 "禁止车辆长时停放" 12 "禁止鸣喇叭" 13 "停车让行" 14 "减速让行" 15 "会车让行" 16 "reserved" ;
VAL_ 922 LAS_OverspeedSoundWarningEnSt 0 "Off" 1 "On" ;
VAL_ 922 LAS_TSREnable 0 "off" 1 "on" ;
VAL_ 922 LAS_HMAEnableStatus 0 "off" 1 "on" ;
VAL_ 922 LAS_HMALightDistribution 0 " High beam not recommended" 1 " High beam recommended" ;
VAL_ 922 LAS_HMAStatus 0 " Off" 1 " Standby" 2 " Active" 3 " Failure" ;
VAL_ 922 LAS_TSRHostSpdLimitUnits 0 "no display" 1 "unit kph" 2 "unit mph" 3 "reserved" ;
VAL_ 922 LAS_TSRHostSpdLimit 0 "no speed limit detected" 1 "SL5" 2 "SL10" 3 "SL15" 4 "SL20" 5 "SL25" 6 "SL30" 7 "SL35" 8 "SL40" 9 "SL45" 10 "SL50" 11 "SL55" 12 "SL60" 13 "SL65" 14 "SL70" 15 "SL75" 16 "SL80" 17 "SL85" 18 "SL90" 19 "SL95" 20 "SL100" 21 "SL105" 22 "SL110" 23 "SL115" 24 "SL120" 25 "SL125" 26 "SL130" 27 "SL135" 28 "SL140" 29 "SL145" 30 "SL150" 31 "SL155" 32 "SL160" 33 " SL165" 34 " SL170" 35 " SL175" 36 " SL180" 37 "Reserved" 38 "Reserved" 39 "Reserved" 40 "Reserved" 41 "Reserved" 42 " Reserved" 43 " Slend-5" 44 " Slend-15" 45 " Slend-20" 46 " Slend-25" 47 " Slend-30" 48 " Slend-35" 49 " Slend-40" 50 " Slend-45" 51 " Slend-50" 52 " Slend-55" 53 " Slend-60" 54 " Slend-65" 55 " Slend-70" 56 " Slend-75" 57 " Slend-80" 58 " Slend-85" 59 " Slend-90" 60 " Slend-95" 61 " Slend-100" 62 " Slend-105" 63 " Slend-110" 64 " Slend-115" 65 " Slend-120" 66 " Slend-125" 67 " Slend-130" 68 " Slend-135" 69 " Slend-140" 70 " Slend-145" 71 " Slend-150" 72 " Slend-155" 73 " Slend-160" 74 " Slend-165" 75 " Slend-170" 76 " Slend-175" 77 " Slend-180" 78 "Reserved" 254 "Unlimited" 255 "SLEND" ;
VAL_ 922 LAS_TSRStatus 0 "off" 1 "fusion mode" 2 "vision only mode" 3 "navigation only mode" 4 "Failure" 5 "reserved" 6 "reserved" 7 "Invalid" ;
VAL_ 922 LAS_FrontCameraCalibrationStatus 0 "Calibration is ok" 1 "Calibration In Process" 2 "Calibration never done" 3 "Calibration Failed" ;
VAL_ 922 LAS_FrontCameraFailureStatus 0 "No Error" 1 "camera blocked" 2 "temporary failure" 3 "permanent failure" ;
VAL_ 922 LAS_OverspeedWarningOffset 0 "-10~20km/h" 31 "Reserved" 47 "Invalid" ;
VAL_ 922 LAS_OverspeedWarningEnableStatus 0 "OFF" 1 "ON" ;
VAL_ 922 LAS_OverspeedSoundWarning 0 " No Warning" 1 " Warning" ;
VAL_ 922 LAS_OverspeedVisualWarning 0 " No Warning" 1 " Warning" ;
VAL_ 922 LAS_TLAArrowDirection_RightLane 0 "no display" 1 "Forward" 2 "Left" 3 " Forward +Left" 4 "Right" 5 " Forward +Right" 6 "Right+Left" 7 "Left+ Forward +Right" ;
VAL_ 922 LAS_TLAObjectType_RightLane 0 "no display" 1 "Round" 2 "Arrow" 3 "Turn Round" 4 "X-type" 5 "Arrow+Trun
0x6-0x7=reserved" ;
VAL_ 922 LAS_TLAObjectStatus_RightLane 0 "no display" 1 "Lighting" 2 "Flashing" 3 " Disappear" ;
VAL_ 922 LAS_TLAObjectColour_RightLane 0 "no display" 1 "Red" 2 "Yellow" 3 "Green" ;
VAL_ 922 LAS_TLAObjectDetection_RightLane 0 "Not Detected" 1 "Detected" ;
VAL_ 922 LAS_TLAArrowDirection_LeftLane 0 "no display" 1 "Forward" 2 "Left" 3 " Forward +Left" 4 "Right" 5 " Forward +Right" 6 "Right+Left" 7 "Left+ Forward +Right" ;
VAL_ 922 LAS_TLAObjectType_LeftLane 0 "no display" 1 "Round" 2 "Arrow" 3 "Turn Round" 4 "X-type" 5 "Arrow+Trun
0x6-0x7=reserved" ;
VAL_ 922 LAS_TLAObjectStatus_LeftLane 0 "no display" 1 "Lighting" 2 "Flashing" 3 " Disappear" ;
VAL_ 922 LAS_TLAObjectColour_LeftLane 0 "no display" 1 "Red" 2 "Yellow" 3 "Green" ;
VAL_ 922 LAS_TLAObjectDetection_LeftLane 0 "Not Detected" 1 "Detected" ;
VAL_ 922 LAS_TLAArrowDirection_HostLane 0 "no display" 1 "Forward" 2 "Left" 3 " Forward +Left" 4 "Right" 5 " Forward +Right" 6 "Right+Left" 7 "Left+ Forward +Right" ;
VAL_ 922 LAS_TLAObjectStatus_HostLane 0 "no display" 1 "Lighting" 2 "Flashing" 3 " Disappear" ;
VAL_ 922 LAS_TLAObjectType_HostLane 0 "no display" 1 "Round" 2 "Arrow" 3 "Turn Round" 4 "X-type" 5 "Arrow+Trun" 6 "reserved" ;
VAL_ 922 LAS_TLAObjectColour_HostLane 0 "no display" 1 "Red" 2 "Yellow" 3 "Green" ;
VAL_ 922 LAS_TLAObjectDetection_HostLane 0 "Not Detected" 1 "Detected" ;
VAL_ 922 LAS_TLAWarninglevel 0 " no warning" 1 " warning level 1" 2 " warning level 2" 3 " warning level 3." ;
VAL_ 922 LAS_TLAStatus 0 "OFF" 1 "Standby" 2 "Active" 3 "Failure" ;
VAL_ 922 LAS_TLAEnable 0 "OFF" 1 "ON" ;
VAL_ 922 LAS_RoadSignCenterLatRange_RLane 0 "(-8)+(0.05*X)" 321 "Reserved" ;
VAL_ 922 LAS_RoadSignCenterLngRange_RLane 0 "(0.1*X)m" 501 "Reserved" ;
VAL_ 922 LAS_RoadSignCenterLatRange_LLane 0 "(-8)+(0.05*X)" 321 "Reserved" ;
VAL_ 922 LAS_RoadSignCenterLngRange_LLane 0 "(0.1*X)m" 501 "Reserved" ;
VAL_ 922 LAS_RoadSignCenterLatRange_HLane 0 "(-8)+(0.05*X)" 321 "Reserved" ;
VAL_ 922 LAS_RoadSignCenterLngRange_HLane 0 "(0.1*X)m" 501 "Reserved" ;
VAL_ 922 LAS_CrosswalkLngRange_HLane 0 "0-250m" 251 "Reserved" 255 "Out of Range" ;
VAL_ 922 LAS_RoadSignType_RLane 0 "no detect" 1 "Forward" 2 "Left" 3 "Right" 4 "Turn Round to Left" 5 "Turn Round to Right" 6 "Forward +Left" 7 "Forward +Right" 8 "Forward +TurnRdToLeft" 9 "Forward +TurnRdToRight" 10 "TurnRd To Left or Right" 11 "Left +TurnRd to Left" 12 "Right +TurnRd to Right" 13 "Left +TurnRd to Right" 14 "Right +TurnRd to left" 15 "Left +Forward+Right" 16 "Left +Forward +TurnRd to Right" 17 "Right +Forward +TurnRd to Left" 18 "TurnRd to Rt+Forward +TurnRd to Lt" 19 "Reserved" 31 "invalid" ;
VAL_ 922 LAS_RoadSignType_LLane 0 "no detect" 1 "Forward" 2 "Left" 3 "Right" 4 "Turn Round to Left" 5 "Turn Round to Right" 6 "Forward +Left" 7 "Forward +Right" 8 "Forward +TurnRdToLeft" 9 "Forward +TurnRdToRight" 10 "TurnRd To Left or Right" 11 "Left +TurnRd to Left" 12 "Right +TurnRd to Right" 13 "Left +TurnRd to Right" 14 "Right +TurnRd to left" 15 "Left +Forward+Right" 16 "Left +Forward +TurnRd to Right" 17 "Right +Forward +TurnRd to Left" 18 "TurnRd to Rt+Forward +TurnRd to Lt" 19 "Reserved" 31 "invalid" ;
VAL_ 922 LAS_RoadSignType_HLane 0 "no detect" 1 "Forward" 2 "Left" 3 "Right" 4 "Turn Round to Left" 5 "Turn Round to Right" 6 "Forward +Left" 7 "Forward +Right" 8 "Forward +TurnRdToLeft" 9 "Forward +TurnRdToRight" 10 "TurnRd To Left or Right" 11 "Left +TurnRd to Left" 12 "Right +TurnRd to Right" 13 "Left +TurnRd to Right" 14 "Right +TurnRd to left" 15 "Left +Forward+Right" 16 "Left +Forward +TurnRd to Right" 17 "Right +Forward +TurnRd to Left" 18 "TurnRd to Rt+Forward +TurnRd to Lt" 19 "Reserved" 31 "invalid" ;
VAL_ 906 GW_MFS_Cust_switch 0 "按键未按下" 1 "按键按下" 2 "假按键" 3 "Error" ;
VAL_ 583 APA_SlotNotice_1 0 " IDLE" 1 " Parking in" 2 "L_Per_slot" 3 "R_Per_slot" 4 "L_Par_slot" 5 " R_Par_slot" 6 "L_Fishbone_slot" 7 " R_Fishbone_slot" 8 "L_Parking out indication" 9 "R_Parking out indication" 10 "Rearview" 11 "360 surround view" 12 "Double L//双边泊出有效推荐左" 13 "Double R//双边泊出有效推荐右" 14 "垂直左泊出有效" 15 "垂直右泊出有效" 16 "垂直双边泊出有效推荐左" 17 "垂直双边泊出有效推荐右" 18 "斜列泊出有效左" 19 "斜列泊出有效右" 20 "斜列双边泊出有效推荐左" 21 "斜列双边泊出有效推荐右" ;
VAL_ 583 APA_VCUReadyReq 0 "no request
0x1=request" ;
VAL_ 583 APA_ESP_StandstillRequest 0 "Not request" 1 "Request" ;
VAL_ 583 APA_PtTrqReqValid 0 "Invalid" 1 "Valid" ;
VAL_ 583 APA_LatLongSC 0 "Defalut" 1 "not in control" 2 "in control" 3 "Reserved" ;
VAL_ 583 APA_ESP_BrakeFunctionMode 0 "None" 1 "ReducedFunction" 2 "FullFunction" 3 "Invalid" ;
VAL_ 583 APA_TrqHoldForTCUCl 0 "Off" 1 "On" ;
VAL_ 583 APA_TCUClutchCombinationReq 0 "" 1 "" ;
VAL_ 583 APA_FunctionOnOffSts 0 " Off" 1 " searching" 2 "Remote Vertical In&Out  On" 3 "RemoteByAPP On" 4 "RemoteByOneKey On" 5 "Remote function on" 6 "APAparkin" 7 "APAparkout" 8 "RemoteByAPPVerticalInOutOn" 9 "4G Remote Vertical In&Out On" 10 "4G Remote ParkingOut" 11 "4G Remote function on" 12 "4G ParkHoming" 13 "4G Parking On" 14 "HZPParkin" 15 "HZPParkout" 16 "AVPParkin" 17 "AVPParkout" 18 "Remotefullfunction" 19 "RADS" 20 "RemotebyAPPparkingout" 21 "Custom On" 22 "APA Custom On" 23 "RemotebyVoiceparkingout" 24 "AmenityPark" 25 "RPO ON" ;
VAL_ 583 APA_APAOnOff 0 "OFF" 1 "ON" ;
VAL_ 583 APA_TurnLightsCommand 0 "No Request" 1 "LeftLight On" 2 "RightLight On" 3 "DoubleLights On  " ;
VAL_ 583 APA_IncreasePressureReq 0 "Not request" 1 "Request" ;
VAL_ 583 APA_RemoteOnOff 0 "OFF" 1 "On" 2 "Not used" 3 "Invalid " ;
VAL_ 583 APA_EmergenceBrake 0 "Not request" 1 "Request" ;
VAL_ 583 APA_ErrorStatus 0 "No Error" 1 "Error" ;
VAL_ 583 APA_SteeringAngleReqProtection 0 "No Request" 1 "Request EPS control" 2 "EPS control active" ;
VAL_ 583 APA_HSAHDforbidden 0 "Not request" 1 "Request" ;
VAL_ 583 APA_AccPedShieldReq 0 "Unshield" 1 "Shield" ;
VAL_ 583 APA_SlotNotice 0 " IDLE" 1 " Parking in" 2 "L_Per_slot" 3 "R_Per_slot" 4 "L_Par_slot" 5 " R_Par_slot" 6 "L_Fishbone_slot" 7 " R_Fishbone_slot" 8 "L_Parking out indication" 9 "R_Parking out indication" 10 "Rearview" 11 "360 surround view" 12 "reserved" 15 "Invalid" ;
VAL_ 583 APA_DynamicSlotWarning 0 "No warning" 1 "Warning" ;
VAL_ 583 APA_Activation_Status 0 "APA_Off" 1 "APA_Nonactivated" 2 "APA_Actived" 3 "APA_GuidanceActive" 4 "APA_Completed" 5 "APA_Failure" 6 "APA_Terminated" 7 "APA_Suspend" 8 "APA_PendSuspend" 9 "passive" ;
VAL_ 583 APA_EngineTrqReqEnable 0 "Not Enable" 1 "Enable" ;
VAL_ 583 APA_LSCAction 0 "OFF" 1 "ON" ;
VAL_ 583 APA_TransPRNDShiftEnable 0 "Not Enable" 1 "Enable" ;
VAL_ 583 APA_TransPRNDShiftReqValid 0 "Invalid" 1 "Valid" ;
VAL_ 583 APA_TransPRNDShiftRequest 0 "No Request" 1 "Park " 2 " Reverse " 3 "Neutral" 4 "Drive" 5 " invalid" 6 "reserved" ;
VAL_ 583 APA_TargetAccelerationValid 0 " not enable" 1 " enable" ;
VAL_ 583 APA_EPBrequestValid 0 "Invalid" 1 "Valid" ;
VAL_ 583 APA_EPBrequest 0 "No Request" 1 "RequestBrake" 2 "RequestRelase" ;
VAL_ 610 PEPS_APA_PowerMirrorFoldFeedback 0 "InActive " 1 "Fold" 2 "Open" 3 "Reserved" ;
VAL_ 610 PEPS_APARemoteParkingOff 0 " Not Pressed" 1 " Pressed" ;
VAL_ 610 PEPS_PEPSFailStatus 0 "No Error" 1 "Error" ;
VAL_ 610 PEPS_RemoteStartFeedback 0 " 无反馈" 1 " 启动成功" 2 " 连续启动次数过多" 3 " 整车电量不足" 4 " 车门或引擎盖或行李箱未关闭" 5 " 遥控钥匙在车内" 6 " 防盗激活" 7 " 紧急报警灯光激活" 8 " 整车不在P档" 9 " 车速不为0" 10 " 发动机已经运行" 11 " 电子手刹未夹紧" 12 " 油量不足" 13 " 启动系统故障" 14 " 发动机机油压力过低" 15 " 发动机冷却液温度过高" 16 " 电喷系统故障" 17 " 运行时间到正常熄火" 18 " 环境温度过低" 19 "周边防盗未处于设防状态" 20 "远程/遥控熄火成功" 21 "启动时间已达30min 上限" 22 " Reserved" ;
VAL_ 610 PEPS_APA_CloseWinFeedback 0 "InActive " 1 "Success " 2 "Failed " 3 "Reserved" ;
VAL_ 610 PEPS_RemoteAPADoneKeyOffReq 0 " invalid" 1 " request" 2 " not request" 3 " reserved" ;
VAL_ 610 PEPS_APA_Engine0ffFeedback 0 "InActive " 1 "Success " 2 "Failed " 3 "Reserved" ;
VAL_ 610 PEPS_APA_LockFeedback 0 "InActive " 1 "Success " 2 "Failed " 3 "Reserved" ;
VAL_ 610 PEPS_APARemoteParkingOn 0 " Not Pressed" 1 " Pressed" ;
VAL_ 917 TBOX_APAControlEnable 0 "inactive" 1 "start" 2 "end（reserved）" 3 "cancel" 4 "suspend" 5 "recover（reserved）" 6 "disconnect(reserved)" 7 "TurnLeft Pressed" 8 "TurnRight Pressed" 9 "SteeringReturn" 10 "Verticalbackward Pressed" 11 "Verticalforward Pressed" 12 "Left Park Out" 13 "Right Park Out" 14 "Parking Out（reserved）" 15 "Vertical In&Out（reserved）" 16 "ParkHoming（reserved）" 17 "Slot choose（reserved）" 18 "Reserved" ;
VAL_ 917 TBOX_RemoteStartReq 0 "No Reqeust" 1 "进入可行驶模式" 2 "退出可行驶模式" 3 "Invalid" ;
VAL_ 917 TBOX_APAFunctionReq 0 "inactive" 1 "parkin" 2 "parkout" 3 "rma" 4 "RPO//备车泊出" 5 "reserved" ;
VAL_ 917 TBOX_SignalStrength 0 "No Signal" 1 "1st Level" 2 "2nd Level" 3 "3rd Level" 4 "4th Level" 5 "Reserved" ;
VAL_ 917 TBOX_SignalType 0 "No Signal" 1 "2G" 2 "3G" 3 "4G" 4 "5G" 5 "Reserved" ;
VAL_ 917 TBOX_APA_SignalDelay 0 "Inactive" 1 "Lessthan500ms" 1 "500ms-1s" 2 "1s-1.5s" 3 "1.5s-2s" 4 "2s-2.5s" 5 "2.5s-3s" 6 "3s-3.5s" 7 "3.5s-4s" 8 "4s-4.5s" 9 "4.5s-5s" 10 "Reserved" ;
VAL_ 917 TBOX_APAmoduleEnable 0 "Off" 1 "Inactive" 2 "On" 3 "Reserved" ;
VAL_ 917 TBOX_RemoteDisReq 0 "Inactive" 1 "Active" ;
VAL_ 917 TBOX_VehicleVedioDetectReq 0 " No Request" 1 "Request" 2 " Reserved" 3 "Invalid" ;
VAL_ 917 TBOX_RemoteDetectReq 0 " InActive" 1 "Active" 2 " Reserved" 3 " Invalid" ;
VAL_ 1344 APA_HornRq 0 "Inactive" 1 "关闭" 2 "频率1" 4 "频率2" ;
VAL_ 1344 APA_HighLampRq 0 "Inactive" 1 "关闭" 2 "常亮  " 3 "Reserved" ;
VAL_ 1344 APA_RigtLowLampRq 0 "Inactive" 1 "关闭" 2 "常亮  " 3 "auto档" ;
VAL_ 1344 APA_LeftLowLampRq 0 "Inactive" 1 "关闭" 2 "常亮  " 3 "auto档" ;
VAL_ 1360 APA_RightRearWindowControl 0 "Inactive" 1 "0~100%" 102 "Reserved" ;
VAL_ 1360 APA_LeftRearWindowControl 0 "Inactive" 1 "0~100%" 102 "Reserved" ;
VAL_ 1360 APA_PassengerWindowControl 0 "Inactive" 1 "0~100%" 102 "Reserved" ;
VAL_ 1360 APA_DriverWindowControl 0 "Inactive" 1 "0~100%" 102 "Reserved" ;
VAL_ 1360 APA_MirrorAutoFoldReq 0 "Inactive" 1 "off" 2 "on" 3 "Reserved" ;
VAL_ 1360 APA_DoorLockRq 0 " No Request" 1 " Lock" 2 " Unlock" 3 " Reserved" ;
VAL_ 1360 APA_HiddenHandleControlReq 0 "Inactive" 1 "Back" 2 "Fold" 3 "Reserved" ;
VAL_ 1554 DVR_EmergencyRecordStatus 0 "invalid" 1 "Unsuccessful" 2 "Success" 3 "Saving" ;
VAL_ 394 TCU_APAShiftGearRequestEnable 0 "No Request Received" 1 "Control enabled" 2 "Control disable(预留)" 3 "invalid" ;
VAL_ 394 TCU_APAdriverInterruption 0 "No Interruption" 1 "Interruption" 2 "Reserved" 3 "invalid" ;
VAL_ 586 ESL_DriveModeRequest 0 " Auto" 1 " Manual/Sport" 2 " Reserved" 15 " Invalid" ;
VAL_ 586 ESL_DriverParkButtonFaultStatus 0 "normal" 1 "Fault1" 2 "Fault" 3 "Reserved" ;
VAL_ 586 ESL_DriverParkRequest 0 " Driver Park Not Requested" 1 " Driver Park Requested" 2 "Reserved" 3 "Invalid" ;
VAL_ 586 ESL_ShiftLeverPositionrequest 0 " Center" 1 " Up" 2 " Down" 3 " Up, Up" 4 " Down, Down" 5 " Reserved" 15 " Invalid" ;
VAL_ 586 ESL_ShiftLeverPositionFaultSts 0 "normal" 1 "Degraded" 2 "Limphome" 3 "Fault" ;
VAL_ 710 APA_FunctionOnOffSts 0 " Off" 1 " searching" 2 "Remote Vertical In&Out  On" 3 "RemoteByAPP On" 4 "RemoteByOneKey On" 5 "Remote function on" 6 "APAparkin" 7 "APAparkout" 8 "RemoteByAPPVerticalInOutOn" 9 "4G Remote Vertical In&Out On" 10 "4G Remote ParkingOut" 11 "4G Remote function on" 12 "4G ParkHoming" 13 "4G Parking On" 14 "HZPParkin" 15 "HZPParkout" 16 "AVPParkin" 17 "AVPParkout" 18 "Remotefullfunction" 19 "RADS" 20 "RemotebyAPPparkingout" 21 "Custom On" 22 "APA Custom On" 23 "RemotebyVoiceparkingout" 24 "AmenityPark" 25 "RPO ON" ;
VAL_ 710 APA_ParkingSlot_Width 0 "无" 1 "1.8-5m" 34 "小于1.8m" 35 "大于5m" 36 "预留" ;
VAL_ 710 APA_ParkingSlot_Length 0 "无" 1 "3-10m" 72 "小于3m" 73 "大于10m" 74 "预留" ;
VAL_ 710 APA_ParkingSlot_ExtraFeature 0 "无车位" 1 "左侧有特殊障碍物（柱子、消防栓、墙等）" 2 "右侧有特殊障碍物（柱子、消防栓、墙等）" 3 "左右侧有特殊障碍物（柱子、消防栓、墙等）" 4 "reserved" ;
VAL_ 710 APA_ParkingSlot_Type 0 "无有效车位" 1 "平行" 2 "垂直" 3 "斜列" 4 "障碍物" 5 "车辆" 6 "reserved" ;
VAL_ 710 APA_ActivationSts 0 "inactive" 1 "parkin" 2 "parkout" 3 "RMA" 4 "not in condition" 5 "failure" 6 "RPO" 7 "reserved" ;
VAL_ 710 APA_Condition_Notice 0 "No Problem" 1 "Speed too fast" 2 "Slope too high" 3 "Vehicle not start" 4 "vehicle setup  center" 5 "ACC not closed" 6 "The current area not available" 7 "Dark" 8 "Bad Weather" 9 "Unavailable//智能泊车不可用" 10 "APA on failure for sensor fault//泊车激活失败，传感器故障" 11 "APA on failure for system fault//泊车激活失败，系统故障，请检修" 12 "APA active failure for intervene over time//泊车激活失败，请重试" 13 "Custom failure for no static//请停止车辆后重试" 14 "APA can't be turned on while charging//泊车激活失败，车辆充电中" 15 "Super power mode//超级能耗模式,泊车不可激活" 16 "baterry low//电量低，泊车不可激活" 17 "Uss block//超声波传感器遮挡，请清洗后重试" 18 "Camera block//摄像头遮挡，请清洗后重试" 19 "APA on failure for trailer mode on//泊车激活失败，请退出拖车模式" 20 "APA on failure for trunk open//泊车激活失败，后背门未关" 21 "APACust Unavailable//自定义车位不可用" 22 "APACust on failure for notstandstill //请停止车辆后重试" 23 "APA On failure for Non-Normal driving mode//非普通驾驶模式，智能泊车不可用" 24 "No bluetooth EPAunavailable//未连接蓝牙，离车自动泊入不可用" 25 "EPAunavailable//离车自动泊入不可用" 26 "No network EPAunavailable//车端网络异常，离车自动泊入不可用" 27 "APA on failure for towing mode//当前处于拖挂模式，泊车功能开启受抑制" 28 "APA on failure for air suspension mode improper//空气悬架非正常模式，泊车功能开启受抑制" ;
VAL_ 710 APA_TouchInfOnOffRes 0 "off" 1 "on" 2 "not in condition" 3 "failure" 4 "reserved" ;
VAL_ 710 APA_RADSNotice 0 "IDLE" 1 "No Path" 2 "Slope too high" 3 "Stop the car" 4 "Curve limiting" 5 "Close the door" 6 "Rain too high" 7 "Shift Gear to R" 8 " Brake Please" 9 "Release Steering" 10 "Please seat belt" 11 "insufficient light" 12 "System Runing" 13 "About to arrive at the destination" 14 "Successful System " 15 "System OUT By Switch " 16 "System OUT By Intervene" 17 "System OUT Door Out" 18 "Not wearing seat belt" 19 "Slope too high function cancel" 20 "Curve limit function cancel" 21 "Rain too high function cancel" 22 "SystemFailure function cancel" 23 "System out overtime for slpee too high " 24 "System out overtime for people" 25 "System out overtime for animal" 26 "System out overtime for car" 27 "System out overtime for obstacle" 28 "SystemFailure System OUT" 29 "System out for Engine stop" 30 "System out for brake" 31 "System out for shiftgears 0x20=System out for earlywarning" 34 "System out for light" 35 "PMO chose ELS auto mode" 36 "ACCPedal intervene" 37 "BrakePedal intervene" 38 "GearShifter intervene" 39 "Door intervene system suspend" 40 "System timeout" 41 "suspend resume" 42 "RADS on failure for Non-Normaldriving mode" 43 "" 44 "系统失效，请踩住刹车接管车辆" 44 "Reserved" 63 "invalid" ;
VAL_ 710 APA_PowerMirrorFoldReq 0 "" 1 "" 2 "Open" 3 "Reserved" ;
VAL_ 710 APA_LAEBReq 0 "" 1 "" ;
VAL_ 710 APA_left_fishboneslot_type 0 "Inactive" 1 "Left Forward type" 2 "Left Reverse type" 3 "Reserved" ;
VAL_ 710 APA_right_fishboneslot_type 0 "Inactive" 1 "Rignt Forward type" 2 "Right Reverse type" 3 "Reserved" ;
VAL_ 710 APA_right_slot_4_available_sts 0 "Inactive" 1 "Available" 2 "Not Available" 3 "Reserved" ;
VAL_ 710 APA_right_slot_3_available_sts 0 "Inactive" 1 "Available" 2 "Not Available" 3 "Reserved" ;
VAL_ 710 APA_right_slot_2_available_sts 0 "Inactive" 1 "Available" 2 "Not Available" 3 "Reserved" ;
VAL_ 710 APA_right_slot_1_available_sts 0 "Inactive" 1 "Available" 2 "Not Available" 3 "Reserved" ;
VAL_ 710 APA_left_slot_4_available_sts 0 "Inactive" 1 "Available" 2 "Not Available" 3 "Reserved" ;
VAL_ 710 APA_left_slot_3_available_sts 0 "Inactive" 1 "Available" 2 "Not Available" 3 "Reserved" ;
VAL_ 710 APA_left_slot_2_available_sts 0 "Inactive" 1 "Available" 2 "Not Available" 3 "Reserved" ;
VAL_ 710 APA_left_slot_1_available_sts 0 "Inactive" 1 "Available" 2 "Not Available" 3 "Reserved" ;
VAL_ 710 APA_right_slot_4_type 0 "unvailable " 1 "vertical slot" 2 "parallel slot" 3 "Fishbone slot" ;
VAL_ 710 APA_right_slot_3_type 0 "unvailable " 1 "vertical slot" 2 "parallel slot" 3 "Fishbone slot" ;
VAL_ 710 APA_left_slot_4_type 0 "unvailable " 1 "vertical slot" 2 "parallel slot" 3 "Fishbone slot" ;
VAL_ 710 APA_left_slot_3_type 0 "unvailable " 1 "vertical slot" 2 "parallel slot" 3 "Fishbone slot" ;
VAL_ 710 APA_NumberofParkingSlot 0 "idle" 1 "1" 2 "2" 3 "3" 4 "4" 5 "5" 6 "6" 7 "7" 8 "8" 9 "9" 10 "10" 11 "Reserved" ;
VAL_ 710 APA_BCMHornCommand 0 "No Request" 1 "Request" 2 "Reserved" 3 "Invalid" ;
VAL_ 710 APA_PEPS_EngineOffLockRequest 0 "" 1 "" ;
VAL_ 710 APA_RemoteParkingUsingRemind 0 "No GetOff Request" 1 "GetOff Request" ;
VAL_ 710 APA_BLEConnectionRemind 0 "No Request" 1 "Request " ;
VAL_ 710 APA_ReleasePressureReq 0 " No Request" 1 "Request" ;
VAL_ 710 APA_LAEBNotice 0 "Off" 1 "On" 2 "Reminding" 3 "Braking" 4 "Failure" 4 "Reserve" ;
VAL_ 710 APA_LAEBStatus 0 "Off" 1 "Standby" 2 "Unavailable" 3 "Active" 4 "Brake" 5 "ReFault" 6 "Fault" 7 "Reserve" ;
VAL_ 710 APA_ParkNotice_5 0 " IDLE" 1 " 'Search Slot" 2 "Stop the car" 3 " Parking Modeselection" 4 " Fasten seat belts for driver_park in" 5 " Close the door_parkin" 6 " No Standstill Brake_park in" 7 " PMO chose ELS auto mode" 8 "Brake and Long_Button" 9 " Rele_Bra_Park" 10 " Parking in" 11 " Park insuspend ACC pedal pressed" 12 " Park in suspend Handle Gear shift" 13 "parkin suspend Driver seatbelt unfastened" 14 "Park in suspend Door open" 15 "Park in suspend EPB ON" 16 " Park in suspend resume" 17 "Parking system error" 18 "Successful Park in" 19 "PMO slot too big" 20 "PMO slot too small" 21 "PMO side selection" 22 "PMO suspend Handle Gear Shift" 23 "Fasten seat belts_park out" 24 " Close the door_park out" 25 " PMOchose ELS auto mode" 26 "FP4U button longpressed and braking check" 27 " Start PMO Release Brake" 28 "Parking out" 29 " PMO suspend ACCpadel pressed" 30 " PMO suspend Gear change" 31 " PMO suspend driverseat belt unfastened" 32 " PMO suspend door open" 33 " PMO suspend EPBON" 34 " Park out resume" 35 "Parking canceled" 36 " Park off speed toofast" 37 " successful PMO" 38 " Speed too high please slow down" 39 "Slot search off speed too high" 40 " Remote Parking active" 41 " forwardremote parking" 42 " backward remote parking" 43 " remote Parkingfinish" 44 "EPS  functional limitation" 45 "EMS  functional limitation" 46 "ESP functional limitation" 47 "ESL functional limitation" 48 "Smartphone Remote Parking in active" 49 "Smartphone Remote Parking out on" 50 "Smartphone Remote Parking in on" 51 "smartphone Remote Parking out active" 52 "Slope too high function cancel" 53 "vehicle not standstill" 54 "Gear not P" 55 "EPB not clamp" 56 "Handshake failed" 57 "Remote parking use hints" 58 "Start engine" 59 "Search Slot by rerverse gear" 60 "System Cancel Object Tracked" 61 "Cancle_ACCMode" 62 "Shift Gear to D" 63 "ASP Failed for Over Distance" 64 "ASP Failed for Over Time" 65 "ASP Failed for User Takeover" 66 "Active suspension" 67 "Passive suspension" 68 "Passive suspension renew" 69 "Remote parking start" 70 "Remote parking on" 71 "Remote parking key use hints" 72 "PlsSelectParkingSlot" 73 "RemoteParkingUseRecommend" 74 "System Resume Object Tracked" 75 "System Cancel Insufficient Space" 76 "Key Longpressed Resume" 77 "" 78 "APP Parking Abnormal End" 79 "4G Remote parking on（车辆4G状态OK，且符合近程代客泊车条件）" 80 "APP Remote parking Suspend" 81 "Key Remote parking Suspend" 82 "APP Remote parking Success" 83 "Key Remote parking Success" 84 "APP Remote parking Cancel" 85 "Key Remote parking Cancel" 86 "Illegal interface" 87 "System Cancel Network Delay" 88 "Left Steering" 89 "Right Steering" 90 "SteeringReturn" 91 "FurthestForward" 92 "FurthestBackward" 93 "Maximum Angle of SteeringLeft" 94 "Maximum Angle of SteeringRight" 95 "Not in Geo-fence" 96 "Life in the Car" 97 "Tutorialmodel" 98 "离车遥控泊入" 99 " Beware Of Collision" 100 "RMA function downgrade" 101 " Path planning failure function cancel" 102 "Whether to park in" 103 "CPOC Side Selection" 104 "CPOC BackOut Side Selection" 105 "Furthest ForwardRemoteParking" 106 "Furthest BackwardRemoteParking" 107 "Release the brake" 108 "Parking Cancle DriverInterruption" 109 "Parking Cancle System Timeout" 110 "Parking Suspend Pedestrian tracked" 111 "Parking Suspend Vehicle tracked" 112 "Parking Cancel SteeringInterruption" 113 "Parking Cancel ShifterInterruption" 114 "Dim" 115 "Parking Cancel InterruptionTimes over limit" 116 "CustomslotInvalid" 117 "please modify CustSlot" 118 "CustSlot planningsuccess" 119 "CustSlot planningfailure" 120 "CustSlot planning" 121 "OnlyAPA" 122 "Parking Cancel Non-Normal driving mode" 123 "APA_RPA/EPA//开始泊车+离车泊入" 124 "APA_RPA/EPARecommend//开始泊车+离车泊入（推荐）" 125 "离车自动泊入+离车遥控泊入" 126 "离车自动泊入（置灰）+离车遥控泊入" 127 "提示无感泊车引导教程" ;
VAL_ 710 APA_right_slot_2_type 0 "unvailable" 1 "vertical slot" 2 "parallel slot" 3 "Fishbone slot" ;
VAL_ 710 APA_right_slot_1_type 0 "unvailable" 1 "vertical slot" 2 "parallel slot" 3 "Fishbone slot" ;
VAL_ 710 APA_left_slot_2_type 0 "unvailable" 1 "vertical slot" 2 "parallel slot" 3 "Fishbone slot" ;
VAL_ 710 APA_left_slot_1_type 0 "unvailable" 1 "vertical slot" 2 "parallel slot" 3 "Fishbone slot" ;
VAL_ 798 APA_VoiceTipType 0 "无" 1 "提示音，1声，03_信息提示音" 2 "预警音，1声，07-轻微警告-如门未关" 3 "故障音，1声，02_IACC激活失败" 4 "激活音，1声，09_IACC功能激活" 5 "结束音，1声，05_泊车完成" 6 "reserved" ;
VAL_ 798 APA_ActiveSts 0 "Noactive" 1 "Activate" ;
VAL_ 798 APA_ParkVoiceIntSet 0 "inactive" 1 " On" 2 " Off" 3 "Reserved" ;
VAL_ 798 APA_AVMNotice 0 "IDLE" 1 "Top View" 2 "360 Surroundview" 3 "Frontview" 4 "Rearview" 5 "Left View" 6 "Right View" 7 "Reserved" ;
VAL_ 798 APA_SystemFailureFlag 0 "Not Failure" 1 "Front sersor Failure" 2 "Real sensor Failure" 3 "camera blocked
0x4=Front camera failure" 5 "Rear camera failure" 6 "Left camera failure" 7 "Right camera failure" 8 "system failure" 9 "EPS  functional limitation" 10 "LAEB Failure" 11 "LASP Failure" 12 "SVA Failure" 13 "EMS  functional limitation" 14 "ESP functional limitation" 15 "ESL functional limitation" 16 "iBCM functional limitation" 17 "SRS functional limitation" 18 "RFBT functional limitation" 19 "HU functional limitation" 20 "IP functional limitation" 21 "APA Switch Failure" 22 "DVR Not Available" 23 "Reserved" ;
VAL_ 798 APA_ObstacleSafeDistSetStatus 0 "invalid" 1 "30" 2 "40" 3 "50" 4 "60" 5 "70" 6 "80" 7 "Reserved" ;
VAL_ 798 APA_Uls_FKP_WarningSoundStatus 0 "inactive" 1 "On" 2 "Off" 3 "Reserved" ;
VAL_ 798 APA_CrossParkingModeSetSts 0 "Inactive" 1 "Back In" 2 "Head In" 3 "Reserved" ;
VAL_ 798 ACC_LAEBEnableSts 0 "Inactive" 1 "Off" 2 "On" 3 "Reserved" ;
VAL_ 798 RFS_Sector_Dist 0 "0" 1 "1-126" 127 "invalid" ;
VAL_ 798 LFS_Sector_Dist 0 "0" 1 "1-126" 127 "invalid" ;
VAL_ 798 RFC_Sector_Dist 0 "0" 1 "1-126" 127 "invalid" ;
VAL_ 798 LFC_Sector_Dist 0 "0" 1 "1-126" 127 "invalid" ;
VAL_ 798 RFM_Sector_Dist 0 "0" 1 "1-126" 127 "invalid" ;
VAL_ 798 LFM_Sector_Dist 0 "0" 1 "1-126" 127 "invalid" ;
VAL_ 798 RRS_Sector_Dist 0 "0" 1 "1-126" 127 "invalid" ;
VAL_ 798 LRS_Sector_Dist 0 "0" 1 "1-126" 127 "invalid" ;
VAL_ 798 RRC_Sector_Dist 0 "0" 1 "1-126" 127 "invalid" ;
VAL_ 798 LRC_Sector_Dist 0 "0" 1 "1-126" 127 "invalid" ;
VAL_ 798 RRM_Sector_Dist 0 "0" 1 "1-254" 255 "invalid" ;
VAL_ 798 LRM_Sector_Dist 0 "0" 1 "1-254" 255 "invalid" ;
VAL_ 798 RRF_Sector_Dist 0 "0" 1 "1-126" 127 "invalid" ;
VAL_ 798 LRF_Sector_Dist 0 "0" 1 "1-126" 127 "invalid" ;
VAL_ 798 RFF_Sector_Dist 0 "0" 1 "1-126" 127 "invalid" ;
VAL_ 798 LFF_Sector_Dist 0 "0" 1 "1-126" 127 "invalid" ;
VAL_ 798 RRS_FrontRadarActiveStatus 0 "Invalid" 1 " Activated" 2 " Deactivated" 3 "Reserved" ;
VAL_ 798 RRS_SwitchIndicatorError 0 "No Error" 1 "Error" ;
VAL_ 798 RRS_ButtonPress 0 " PAS button idle" 1 "PAS button pressed" ;
VAL_ 798 RRS_WarningType 0 "不报警" 1 "长鸣区报警" 2 "间歇音1报警（报警75ms，不报警175ms）" 3 "间歇音2报警（报警75ms，不报警425ms）" 4 "间歇音3报警（预留）" 5 "长鸣区前后同时报警（前角报警0.5s，后角报警0.5s）" 6 "错误3S报警（长鸣3s）" 7 "系统无错误提示（鸣叫0.5s）" 8 "Not Used" ;
VAL_ 798 RRS_WarningFrequency 0 "不报警" 1 "前角（940Hz）" 2 "后角（750Hz）" 3 "错误报警（1500Hz）   " ;
VAL_ 798 RRS_LFSDistance 0 "No Obstacle Detected" 1 "distance of RRM is less than 40cm " 2 "distance range of RRM is from 40cm to 60cm" 3 " reserved" ;
VAL_ 798 RRS_LRSDistance 0 "No Obstacle Detected" 1 "distance of RRM is less than 40cm" 2 "distance range of RRM is from 40cm to 60cm" 3 "reserved" ;
VAL_ 798 RRS_RFSDistance 0 "No Obstacle Detected" 1 "distance of RRM is less than 40cm " 2 "distance range of RRM is from 40cm to 60cm" 3 " reserved" ;
VAL_ 798 RRS_SideZoneStatus_Rear 0 "None" 1 " Left" 2 "Right" 3 "Left and Right" ;
VAL_ 798 RRS_SideZoneStatus_Front 0 "None" 1 " Left" 2 "Right" 3 "Left and Right" ;
VAL_ 798 RRS_RRSDistance 0 " No Obstacle Detected" 1 "distance of RRM is less than 40cm" 2 "distance range of RRM is from 40cm to 60cm" 3 "reserved" ;
VAL_ 798 RRS_MODE 0 "Off" 1 "Standby" 2 "=Front Rear Active" 3 "Front Active" 4 "Rear Active" 5 "=System Failure" 6 "Reserved" 7 "Invalid(not used)" ;
VAL_ 798 RRS_LFMDistance 0 "No Obstacle Detected" 1 "distance of RRM is less than 40cm" 2 "distance range of RRM is from 40cm to 100cm" 3 "distance range of RRM is from 100cm to 150cm" 4 "reserved" ;
VAL_ 798 RRS_RFMDistance 0 "No Obstacle Detected" 1 "distance of RRM is less than 40cm" 2 "distance range of RRM is from 40cm to 100cm" 3 "distance range of RRM is from 100cm to 150cm" 4 "reserved" ;
VAL_ 798 RRS_RFCDistance 0 "No Obstacle Detected" 1 "distance of RRC is less than 40cm" 2 "distance range of RRC is from40cm to60cm" 3 "invalid" ;
VAL_ 798 RRS_LFCDistance 0 "No Obstacle Detected" 1 "distance of RRC is less than 40cm" 2 "distance range of RRC is from40cm to60cm" 3 "invalid" ;
VAL_ 798 RRS_RRCDistance 0 "No Obstacle Detected" 1 "distance of RRC is less than 40cm" 2 "distance range of RRC is from40cm to60cm" 3 "invalid" ;
VAL_ 798 RRS_LRCDistance 0 "No Obstacle Detected" 1 "distance of RRC is less than 40cm" 2 "distance range of RRC is from40cm to60cm" 3 "invalid" ;
VAL_ 798 RRS_RRMDistance 0 "No Obstacle Detected" 1 "distance of RRM is less than 40cm" 2 "distance range of RRM is from 40cm to 100cm" 3 "distance range of RRM is from 100cm to 150cm" 4 "reserved" ;
VAL_ 798 RRS_LRMDistance 0 "No Obstacle Detected" 1 "distance of RRM is less than 40cm" 2 "distance range of RRM is from 40cm to 100cm" 3 "distance range of RRM is from 100cm to 150cm" 4 "reserved" ;
VAL_ 833 PCU_PwrTqWhMinVld 0 "invalid" 1 "valid" ;
VAL_ 833 PCU_PwrTqWhMaxVld 0 "invalid" 1 "valid" ;
VAL_ 833 PCU_AccPedShield 0 "Not Shield" 1 "Shield" ;
VAL_ 930 GW_Smartphone_APAmoduleEnable 0 "OFF" 1 "Inactive（后台模式） " 2 "ON" 3 "Reserved" ;
VAL_ 930 GW_RFBT_Verticalforward 0 "Not Pressed" 1 "Pressed" ;
VAL_ 930 GW_RFBT_Verticalbackward 0 "Not Pressed" 1 "Pressed" ;
VAL_ 930 GW_RFBT_SlotUserSelected 0 "No selected" 1 "Left Slot 1" 2 "Left Slot 2" 3 "Right Slot 1" 4 "Right Slot 2" 5 "Reserved" 7 "Invalid" ;
VAL_ 930 GW_RFBT_RPASwitch 0 "Not Available" 1 "Not Pressed" 2 "Pressed" 3 "Reserved" ;
VAL_ 930 GW_RFBT_APAPOCModeSelect 0 "No Request" 1 "Left Park Out" 2 "Right Park Out" 3 "No Slot Available" 4 "Reserved" 7 "Invalid" ;
VAL_ 930 GW_RFBT_APAManeuverSuspend 0 "Not Pressed" 1 "Pressed" ;
VAL_ 930 GW_RFBT_APAManeuverStart 0 "Not Pressed" 1 "Pressed" ;
VAL_ 930 GW_RFBT_APAManeuverCancel 0 "Not Pressed" 1 "Pressed" ;
VAL_ 951 AVM_RightCameraSts 0 "No Error" 1 "Error" 2 "reserved" ;
VAL_ 951 AVM_LeftCameraSts 0 "No Error" 1 "Error" 2 "reserved" ;
VAL_ 951 AVM_RearCameraSts 0 "No Error" 1 "Error" 2 "reserved" ;
VAL_ 951 AVM_FrontCameraSts 0 "No Error" 1 "Error" 2 "reserved" ;
VAL_ 982 SLCM_RRWindowStatus 255 "Invalid" ;
VAL_ 982 SLCM_PassengerWindowStatus 255 "Invalid" ;
VAL_ 984 SLCM_RLWindowStatus 255 "Invalid" ;
VAL_ 984 SLCM_DriverWindowStatus 255 "Invalid" ;
VAL_ 1006 RFBT_BLEConnectSts 0 "关闭" 1 "广播" 2 "连接中" 3 "已连接" 4 "预留" 7 "异常" ;
VAL_ 1295 ACC_ResetSts 0 "Valid" 1 "GW请求复位" 2 "自身判断复位" 3 "不满足复位条件" 4 "Reserve" 7 "Invalid" ;
VAL_ 1295 LCDAR_ResetSts 0 "Valid" 1 "GW请求复位" 2 "自身判断复位" 3 "不满足复位条件" 4 "Reserve" 7 "Invalid" ;
VAL_ 1295 LCDAL_ResetSts 0 "Valid" 1 "GW请求复位" 2 "自身判断复位" 3 "不满足复位条件" 4 "Reserve" 7 "Invalid" ;
VAL_ 1295 FRR_ResetSts 0 "Valid" 1 "GW请求复位" 2 "自身判断复位" 3 "不满足复位条件" 4 "Reserve" 7 "Invalid" ;
VAL_ 1295 FLR_ResetSts 0 "Valid" 1 "GW请求复位" 2 "自身判断复位" 3 "不满足复位条件" 4 "Reserve" 7 "Invalid" ;
VAL_ 1295 APA_Coordinate_Angle 0 "-180-180" 361 "reserved" 511 "invalid" ;
VAL_ 1295 APA_Coordinate_Y 0 "-1500-500" 2001 "reserved" 4095 "invalid" ;
VAL_ 1295 APA_Coordinate_X 0 "-500-500" 1001 "reserved" 2047 "invalid" ;
VAL_ 723 ACC_AEBTargetLatRange_for_SRS 0 "-50-50m" 1001 "reserved" ;
VAL_ 723 ACC_CRCCheckr_282 0 "0xFF，XOR value=0xFF，input data reflected=No，Result data reflected=No，check=0x48，Magic check=0xC4）" ;
VAL_ 723 ACC_AEBTargetType_for_SRS 0 "no display" 1 "sedan" 2 "motorcycle" 3 "pedestrian" 4 "Bicycle" 5 "Bus" 6 "reserved" 7 "truck" 8 "reserved" 15 "other" ;
VAL_ 723 ACC_AEBTargetTTC_for_SRS 0 "0.01~2.50" 250 "Time to Impact more than 2.5s and valid" 251 "Timeout" 252 "reserve" 254 "Invaild" ;
VAL_ 723 ACC_AEBTargetRelSpeed_for_SRS 0 "-250-250" 501 "reserved" ;
VAL_ 723 ACC_AEBTargetLngRange_for_SRS 0 "-70~180" 501 "reserved" 511 "no display" ;
VAL_ 723 ACC_AEBActive_for_SRS 0 "not Active" 1 "Active." ;
VAL_ 723 ACC_AEBStatus_for_SRS 0 "off" 1 "on" 2 " reserved" 3 "failure" ;
VAL_ 881 PCU_DrvMod2 0 "Inactive" 1 "ECO" 2 "normal" 3 "sport" 4 "自定义1" 5 "专属模式" 6 "AI（运动/智能）" 7 "Reserved" ;
VAL_ 796 PCU_VcuRdySts 0 "no Ready" 1 "Ready" ;
VAL_ 266 EPB_ClampForce_Secondary 0 "ClampForce" 30 "Reserved" 31 "Error" ;
VAL_ 266 EPB_EAR_Available 0 "Not available" 1 "available" ;
VAL_ 266 EPB_SwitchPositionValid 0 "valid _full function" 1 "error, init or substitute value (no function)" ;
VAL_ 266 EPB_SwitchPosition 0 "no request" 1 "Release request" 2 "Apply request" 3 "Error" ;
VAL_ 266 EPB_Status 0 "both brakes released" 1 "both brakes applied" 2 "both brakes in operation (applying/releasing)" 3 "unknown" ;
VAL_ 266 EPB_FailStatus 0 "no error in EPB – external apply available" 1 "not defined" 2 "not defined" 3 "error in EPB – no external apply allowed" ;
VAL_ 266 EPB_APArequest_Available 0 "notavailable" 1 "available" ;
VAL_ 266 EPB_AchievedClampForce 0 "ClampForce" 30 "Reserved" 31 "Error" ;
VAL_ 81 SRS_CrashOut_Cedr 0 "No Crash" 1 "C-EDR Trigger" ;
VAL_ 81 SRS_CrashOut_Micro 0 "No Crash" 1 "Micro Crash" ;
VAL_ 81 SRS_CrashOut_Rear 0 "No Crash" 1 "Rear Crash" ;
VAL_ 81 SRS_CrashOut_Right 0 "No Crash" 1 "Right Side Carsh" ;
VAL_ 81 SRS_CrashOut_Left 0 "No Crash" 1 "Left Side Crash" ;
VAL_ 81 SRS_CrashOut_Front 0 "No Crash" 1 "Front Crash" ;
VAL_ 849 AMB_Brightness 0 "0x00-0x3FD" 0 "0x3FF" 0 "0x3FE" ;
VAL_ 849 FW_Brightness 0 "0x3FF
默认值0x3FE" ;
VAL_ 380 EMS_IGNKL15Posn 1 "Yes" 0 "No" ;
VAL_ 380 EMS_IdleCtrlSts 1 "True" 0 "False" ;
VAL_ 380 EMS_EngTqFlywhFailr 0 "No error" 1 "Error" ;
VAL_ 380 EMS_EngSts 3 "Reserved" 2 "Running" 1 "Crank" 0 "Stop" ;
VAL_ 380 EMS_EngStrtSuccess 1 "Success" 0 "Not success" ;
VAL_ 380 EMS_EngStopInhb 3 "3rd priority" 2 "2nd priority" 1 "1st priority" 0 "no inhibit" ;
VAL_ 380 EMS_EngSpdErr 0 "No error" 1 "Error" ;
VAL_ 380 EMS_EngRunReq 3 "3rd priority" 2 "2nd priority" 1 "1st priority" 0 "no request" ;
VAL_ 380 EMS_EngFuPumpSts 3 "not used" 2 "Error" 1 "Work" 0 "Not work" ;
VAL_ 380 EMS_EngFuCutOff 1 "True" 0 "False" ;
VAL_ 380 EMS_RngMod_trqCrSLimtSts 1 "Not Valid" 0 "Valid" ;
VAL_ 378 IBCU_TankTurn_Status 0 " Disabled" 1 " Standby" 2 " Active" 3 " Failure" ;
VAL_ 378 ESP_VehicleSpeedValid 0 "Valid" 1 "NotValid" ;
VAL_ 378 ESP_VehicleSpeed 0 "0~360km/h" 6401 "Reserved" 8191 "Invalid" ;
VAL_ 378 ESP_TCSFailStatus 0 "Noerror" 1 "Error" ;
VAL_ 378 ESP_pMcVirtual_Q 0 " pMcVirtual_NotInitialized未初始化" 1 " pMcVirtual_Normal正常" 2 " pMcVirtual_Faulty错误" ;
VAL_ 378 ESP_MbRegenTarWhlRearQlfr 2 "Faulty" 1 "Normal" 0 "NotIntialized" ;
VAL_ 378 ESP_MbRegenTarWhlFrontQlfr 2 "Faulty" 1 "Normal" 0 "NotIntialized" ;
VAL_ 378 ESP_ESPFunctionStatus 0 "OFF" 1 "ON" ;
VAL_ 378 ESP_ESPActiveStatus 0 "NotActive" 1 "Active" ;
VAL_ 378 ESP_EngTorqIncRearActive 1 "Active," 0 "NotActive," ;
VAL_ 378 ESP_EngTorqIncFrontActive 0 "NotActive" 1 "Active" ;
VAL_ 378 ESP_EngTorqDecActive 0 "NotActive" 1 "Active" ;
VAL_ 378 ESP_ABSFailStatus 0 "Noerror" 1 "Error" ;
VAL_ 378 ESP_ABSActiveStatus 0 "NotActive" 1 "Active" ;
VAL_ 670 LCDAL_RCWVideoEnableStatus 0 "Off" 1 "On" ;
VAL_ 670 ADS_FRC_FCTBStatus 0 "OFF(关闭)" 1 "Inactive(未激活)" 2 "Active" 3 "Failure" ;
VAL_ 670 ADS_FRC_FCTAEnable 0 "off" 1 "on" ;
VAL_ 670 ADS_FRC_SystemStatus 0 "Reserved" 1 "StartUp" 2 "Running" 3 "Blocked" 4 "Calibration" 5 "ShutDown" 6 "Hot" 7 "Failure" ;
VAL_ 670 ADS_FLC_SystemStatus 0 "Reserved" 1 "StartUp" 2 "Running" 3 "Blocked" 4 "Calibration" 5 "ShutDown" 6 "Hot" 7 "Failure" ;
VAL_ 670 ADS_FRC_FCTARStatus 0 "OFF(关闭)" 1 "Inactive(未激活)" 2 "Active" 3 "Failure" ;
VAL_ 670 ADS_FRC_Right_FCTARAlert 0 "No FCTA warning" 1 "FCTA warning Level1" 2 "FCTA warning Level2" 3 "FCTA warning Level3" ;
VAL_ 670 ADS_FRC_Left_FCTALAlert 0 "No FCTA warning" 1 "FCTA warning Level1" 2 "FCTA warning Level2" 3 "FCTA warning Level3" ;
VAL_ 670 ADS_FRC_FCTBActive 0 " not Active" 1 " Active." ;
VAL_ 670 ADS_FRC_FCTBEnable 0 "off" 1 "on" ;
VAL_ 685 LCDAL_Right_SEAAlert 0 "No SEA warning" 1 "SEA warning level 1" 2 " SEA Exit" 3 " SEA warning level 2" ;
VAL_ 685 LCDAL_Right_RCWAlert 0 "No RCW warning" 1 "RCW warning level1" 2 "RCW warning level2" 3 "RCW warning level3" ;
VAL_ 685 LCDAL_SEAStatus 0 "OFF(关闭)" 1 "Inactive(未激活)" 2 "Active" 3 "Failure" ;
VAL_ 685 LCDAL_SEAAlert 0 "No SEA warning" 1 "SEA warning level 1" 2 " SEA Exit" 3 " SEA warning level 2" ;
VAL_ 685 LCDAL_SEAEnableStatus 0 "Off" 1 "On" ;
VAL_ 685 LCDAL_RCWStatus 0 "OFF(关闭)" 1 "Inactive(未激活)" 2 "Active" 3 "Failure" ;
VAL_ 685 LCDAL_RCWAlert 0 "No RCW warning" 1 "RCW warning level1" 2 "RCW warning level2" 3 "RCW warning level3" ;
VAL_ 685 LCDAL_RCWEnableStatus 0 "Off" 1 "On" ;
VAL_ 685 LCDAL_SystemStatus 0 "Reserved" 1 "StartUp" 2 "Running" 3 "Blocked" 4 "Calibration" 5 "ShutDown" 6 "Hot" 7 "Failure" ;
VAL_ 879 ADS_NDAStatus 0 "off" 1 "standby" 2 "passive" 3 "active" 4 "suspend" 5 "prohibition" 6 "reserved" 7 "failure" ;
VAL_ 879 ADS_NDATextInfo 0 "no display" 1 "Out of Road ODD（驶离HPP高速区域）" 2 "NDA Limit（NDA限制）" 3 "Weather Limit（天气条件差，请注意观察路况）" 4 "Turn Limit（弯道限制）" 5 "System Limit（驾驶员状态检测限制）" 6 "Toll Exit（前方收费站，即将驶出领航智驾可用路段）" 7 "TrafficAccident Exit（前方事故区域，请注意观察路况）" 8 "Construction Exit（前方施工区域，请注意观察路况）" 9 "Imminent Exit（即将驶离高速路退出提示）" 10 "Handsoff And Eyesoff（疲劳+脱手 请注前方）" 11 "Eyesoff level2（脱眼L2）" 12 "Eyesoff level1（脱眼L1）" 13 "About Exitt（即将驶离高速路退出提示）" 14 "Sharp Turn(急弯提示)" 15 "Leave current road（即将离开当前道路）" 16 "Join to main road（前方汇流，请注意观察路况）" 17 "Speed too high（车速过高提示）" 18 "NDA退出提示" 19 "NDA激活提示" 20 "下匝道脱手提示1级" 21 "下匝道脱手提示2级" 22 "NID已退出，请立即接管" 23 "NID已退出" 24 "NID意外退出" 25 "FIDA一级脱手报警" 26 "FIDA二级脱手报警" 27 "FIDA注意分散一级报警" 28 "FIDA注意分散二级报警" 29 "即将进入匝道，请手握方向盘，集中注意力" 30 "路面颠簸，请注意观察路况" 31 "路况复杂，请接管车辆" 32 "reserved" 33 "请控制方向，300m后将退出NID" 34 "请控制方向，200m后将退出NID" 35 "请控制方向，100m后将退出NID" 36 "前方收费站，请接管车辆" 37 "NID已禁用" 38 "即将进入匝道" 39 " 即将汇入主路" 40 "换道取消" 41 "车速过高，请注意控制车速" 42 "前方急弯" 43 "车道过窄减速" 44 "护栏压迫减速" 45 "高精地图退出，NID功能没退" 46 "道路变化，NID地图未更新，请注意观察路况" 47 "NID降级到ACC" 48 "NID降级到IACC" 49 "NID超越" 50 "NID超越恢复" ;
VAL_ 879 ADS_NIDOutDis 0 " 0~2000m" 201 "Out of Range" 202 "reserved" 255 "unknown" ;
VAL_ 879 LAS_OverspeedWarningRatioOffset_ 0 "-3%~3%" 13 "Reserved" 47 "Invalid." ;
VAL_ 879 LAS_TSRSpeedLimitChangeSoundEnSt 0 "Inactive" 1 "Off" 2 "On" 3 "Reserved" ;
VAL_ 879 LAS_TSRSpeedLimitStatus 0 " Invalid" 1 "valid" 2 " Uncertain speed limit" 3 "Reserved" ;
VAL_ 879 LAS_TSRNavCountryCode 0 "Unknown" 1 "Afghanistan" 2 "Albania" 3 "Algeria" 4 "American Samoa" 5 "Andorra" 6 "Angola" 7 "Anguilla" 8 "Antarctica" 9 "Antigua and Barbuda" 10 "Argentina" 11 "Armenia" 12 "Aruba" 13 "Australia" 14 "Austria" 15 "Azerbaijan" 16 "Bahamas" 17 "Bahrain" 18 "Bangladesh" 19 "Barbados" 20 "Belarus" 21 "Belgium" 22 "Belize" 23 "Benin" 24 "Bermuda" 25 "Bhutan" 26 "Bolivia" 27 "Bosnia and Herzegovina" 28 "Botswana" 29 "Bouvet Island" 30 "Brazil" 31 "British Indian Ocean Territory" 32 "Brunei Darussalam" 33 "Bulgaria" 34 "Burkina Faso" 35 "Burundi" 36 "Cambodia" 37 "Cameroon" 38 "Canada" 39 "Cabo Verde" 40 "Cayman Islands" 41 "Central African Republic" 42 "Chad" 43 "Chile" 44 "China" 45 "Christmas Island" 46 "Cocos (Keeling) Islands" 47 "Colombia" 48 "Comoros" 49 "Congo" 50 "Congo (Democratic Republic of the)" 51 "Cook Islands" 52 "Costa Rica" 53 "C?te d'Ivoire" 54 "Croatia" 55 "Cuba" 56 "Cyprus" 57 "Czech Republic" 58 "Denmark" 59 "Djibouti" 60 "Dominica" 61 "Dominican Republic" 62 "Timor-Leste (East Timor)" 63 "Ecuador" 64 "Egypt" 65 "El Salvador" 66 "Equatorial Guinea" 67 "Eritrea" 68 "Estonia" 69 "Ethiopia" 70 "Falkland Islands (Malvinas)" 71 "Faroe Islands" 72 "Fiji" 73 "Finland" 74 "France" 75 "FRANCE_METROPOLITAN currently not used France is coded as FRANCE" 76 "French Guiana" 77 "French Polynesia" 78 "French Southern Territories" 79 "Gabon" 80 "Gambia" 81 "Georgia" 82 "Germany" 83 "Ghana" 84 "Gibraltar" 85 "Greece" 86 "Greenland" 87 "Grenada" 88 "Guadeloupe" 89 "Guam" 90 "Guatemala" 91 "Guinea" 92 "Guinea-Bissau" 93 "Guyana" 94 "Haiti" 95 "Heard Island and McDonald Islands" 96 "Honduras" 97 "Hong Kong" 98 "Hungary" 99 "Iceland" 100 "India" 101 "Indonesia" 102 "Iran (Islamic Republic of)" 103 "Iraq" 104 "Ireland" 105 "Israel" 106 "Italy" 107 "Jamaica" 108 "Japan" 109 "Jordan" 110 "Kazakhstan" 111 "Kenya" 112 "Kiribati" 113 "Korea (Democratic People's Republic of)" 114 "Korea (Republic of)" 115 "Kuwait" 116 "Kyrgyzstan" 117 "Lao People's Democratic Republic" 118 "Latvia" 119 "Lebanon" 120 "Lesotho" 121 "Liberia" 122 "Libya" 123 "Liechtenstein" 124 "Lithuania" 125 "Luxembourg" 126 "Macao" 127 "Macedonia (the former Yugoslav Republic of)" 128 "Madagascar" 129 "Malawi" 130 "Malaysia" 131 "Maldives" 132 "Mali" 133 "Malta" 134 "Marshall Islands" 135 "Martinique" 136 "Mauritania" 137 "Mauritius" 138 "Mayotte" 139 "Mexico" 140 "Micronesia (Federated States of)" 141 "Moldova (Republic of)" 142 "Monaco" 143 "Mongolia" 144 "Montserrat" 145 "Morocco" 146 "Mozambique" 147 "Myanmar" 148 "Namibia" 149 "Nauru" 150 "Nepal" 151 "Netherlands" 152 "NETHERLANDS_ANTILLES" 153 "New Caledonia" 154 "New Zealand" 155 "Nicaragua" 156 "Niger" 157 "Nigeria" 158 "Niue" 159 "Norfolk Island" 160 "Northern Mariana Islands" 161 "Norway" 162 "Oman" 163 "Pakistan" 164 "Palau" 165 "Palestine, State of" 166 "Panama" 167 "Papua New Guinea" 168 "Paraguay" 169 "Peru" 170 "Philippines" 171 "Pitcairn" 172 "Poland" 173 "Portugal" 174 "Puerto Rico" 175 "Qatar" 176 "R?union" 177 "Romania" 178 "Russian Federation" 179 "Rwanda" 180 "Saint Kitts and Nevis" 181 "Saint Lucia" 182 "Saint Vincent and the Grenadines" 183 "Samoa" 184 "San Marino" 185 "Sao Tome and Principe" 186 "Saudi Arabia" 187 "Senegal" 188 "Seychelles" 189 "Sierra Leone" 190 "Singapore" 191 "Slovakia" 192 "Slovenia" 193 "Solomon Islands" 194 "Somalia" 195 "South Africa" 196 "South Georgia and the South Sandwich Islands" 197 "Spain" 198 "Sri Lanka" 199 "Saint Helena, Ascension and Tristan da Cunha" 200 "Saint Pierre and Miquelon" 201 "Sudan" 202 "Suriname" 203 "Svalbard and Jan Mayen" 204 "Swaziland" 205 "Sweden" 206 "Switzerland" 207 "Syrian Arab Republic" 208 "Taiwan, Province of China" 209 "Tajikistan" 210 "Tanzania, United Republic of" 211 "Thailand" 212 "Togo" 213 "Tokelau" 214 "Tonga" 215 "Trinidad and Tobago" 216 "Tunisia" 217 "Turkey" 218 "Turkmenistan" 219 "Turks and Caicos Islands" 220 "Tuvalu" 221 "Uganda" 222 "Ukraine" 223 "United Arab Emirates" 224 "United Kingdom of Great Britain and Northern Ireland" 225 "United States of America" 226 "United States Minor Outlying Islands" 227 "Uruguay" 228 "Uzbekistan" 229 "Vanuatu" 230 "VATICAN" 231 "Venezuela (Bolivarian Republic of)" 232 "Viet Nam" 233 "Virgin Islands (British)" 234 "Virgin Islands (U.S.)" 235 "Wallis and Futuna" 236 "Western Sahara" 237 "Yemen" 238 "Serbia" 239 "Zambia" 240 "Zimbabwe" 241 "CROATIA2" 242 "MACEDONIA2" 243 "BOSNIA_HERZEGOVINA" 244 "Montenegro" 245 "South Sudan" 246 "Guernsey" 247 "Jersey" 248 "Isle of Man" 249 "?land Islands" 250 "Kosovo" 251 "reserved" ;
VAL_ 879 RADS_DynamicButton 0 "RADS Unavailable
0x1=RADS Available
0x2=Pause button
0x3=Continue button Available
0x4=Continue button Unavailable
0x5-0x7=Reserved" ;
VAL_ 879 LAS_OverspeedWarningRatioOffset 0 "-10%~20%
0x1F~0x2E=Reserved
0x2F=Invalid." ;
VAL_ 879 APA_RPA_Notice 0 " IDLE" 1 " DigKey not detected" 2 " Remote Parking Start" 3 " Remote Parking Suspend" 4 " Remote Parking Suspend Pedestrian tracked" 5 " Remote Parking Suspend Vehicle tracked" 6 " Remote Parking Resume" 7 " Remote Parking Cancel" 8 " Remote Parking Finished" 9 " Vertical Forward Parking" 10 " Vertical Backward Parking" 11 " Parking System Error" 12 " Function Cancel Slop too high" 13 " Function Cancel Feeble illumination" 14 " Function Cancel insufficient Space" 15 " Remote Parkout direction unavailable" 16 "未开启APA页面，功能激活失败" 17 "请关闭车门" 18 "等待超时，功能已退出" 19 "车辆智能泊车中，请注意避让" 20 "车辆即将泊出，请注意避让" 21 "系统失效，请立即接管车辆" 22 "Reserved" ;
VAL_ 879 APA_FunRecomReq 0 "Invalid" 1 "ParkIn" 2 "ParkOut" 3 "Reserved" ;
VAL_ 879 ADS_TunnelStatus 0 "no display" 1 "nearTunnel" 2 "inTunnel" 3 "reserved" ;
VAL_ 879 ADS_RampStatus 0 "no display" 1 "nearRamp" 2 "rampIn" 3 "inRamp" 4 "RampOut" 5 "reserved" ;
VAL_ 879 ADS_PathThroughRamp 0 "notThroughRamp" 1 "throughRamp" 2 "invalid" 3 "reserved" ;
VAL_ 879 ADS_RampSide 0 "invalid" 1 "onRightSide" 2 "onLeftSide" 3 "reserved" ;
VAL_ 879 ADS_AutoDriveStateDisplay 0 "no display" 1 "ACC" 2 "IACC" 3 "HWA" 4 "NDA" 5 "共驾" 6 "1级提醒报警" 7 "2级提醒报警" 8 "3级提醒报警" 9 "4级提醒报警" 10 "1级立即接管报警" 11 "2级立即接管报警" 12 "3级立即接管报警" 13 "0xF=reserved" ;
VAL_ 879 ADS_PathShow_Status 0 "no display" 1 "LaneChangeTryPath，换道等待" 2 "NormalLaneChangePath，换道过程" 3 "LaneChangeReturnPath，换道回退" 4 "CanNotChangeLanePath，换道等待或保持本车道行驶" 5 "SmartBiasPath，智慧偏移路径" 6 "FollowVehicleDrivePath，跟车行驶路径" 7 "RecommendPath，推荐路径" ;
VAL_ 879 ACC_TakeoverReqAtIPFail 0 "no request" 1 "level 1 request" 2 "level 2 request" 3 "reserved" ;
VAL_ 879 ADS_TSRHostNextSpdLimitDist 0 "0~400" 401 "reserved" 511 "no display" ;
VAL_ 879 ADS_TSRHostNextSpdLimit 0 "no speed limit detected" 1 "SL5" 2 "SL10" 3 "SL15" 4 "SL20" 5 "SL25" 6 "SL30" 7 "SL35" 8 "SL40" 9 "SL45" 10 "SL50" 11 "SL55" 12 "SL60" 13 "SL65" 14 "SL70" 15 "SL75" 16 "SL80" 17 "SL85" 18 "SL90" 19 "SL95" 20 "SL100" 21 "SL105" 22 "SL110" 23 "SL115" 24 "SL120" 25 "SL125" 26 "SL130" 27 "SL135" 28 "SL140" 29 "SL145" 30 "SL150" 31 "SL155" 32 "SL160" 33 " Reserved" 254 " Unlimited" 255 " SLEND" ;
VAL_ 1535 BCM_RemoteReadyReq 0 "No Reqeust" 1 "进入可行驶模式" 2 "退出可行驶模式" 3 "Invalid" ;
VAL_ 349 ESP_IMUCalibrated 0 "Calibrated" 1 "Not Calibrated" ;
VAL_ 349 ESP_YawRateValid 0 "Initializing" 1 "Valid" 2 "Invalid" 3 "Reserved" ;
VAL_ 349 ESP_LatAccelValid 0 "Initializing" 1 "Valid" 2 "Invalid" 3 "Reserved" ;
VAL_ 349 ESP_LongAccelValid 0 "Initializing" 1 "Valid" 2 "Invalid" 3 "Reserved" ;
VAL_ 271 IBCU_sOutputRodAct_Q 0 "SoutputRodAct_NotInitialized" 1 "SoutputRodAct_Normal" 2 "SoutputRodAct_Faulty" ;
